VERSION ""

NS_ :

BS_:

BU_: Airbag Allrad EPS Teves_MK60_ESP LWS LWR Teves_MK70_MABS Waehlhebel EPB TRW_ESP ACC_Radar AFS Magne_Ride RKA_Plus Selespeed Waehlhebel_Sele PDC_PLA Lenkhilfe_APA VAQ Daempfer Hybrid_BMS Hybrid_PWR Hybrid_DQ200 EKlimakomp SWA HCA ACC_Lidar Lenkhilfe_ZF_3G FLA AG6 DQ Hybrid_MSG Diesel Otto Gateway_PQ35_A Gateway_PQ46_A Vector_XXX Fzg_CAN

BO_ 1164 mHandschalter_1: 8 Diesel
 SG_ HS1_res_24 : 24|8@1+ (1,0) [0|255] ""  Gateway_PQ46_A,Gateway_PQ35_A,ACC_Lidar,ACC_Radar
 SG_ HS1_Checksumme : 0|8@1+ (1,0) [0|255] ""  Gateway_PQ46_A,Gateway_PQ35_A,ACC_Radar,ACC_Lidar
 SG_ HS1_res_32 : 32|8@1+ (1,0) [0|255] ""  Gateway_PQ46_A,Gateway_PQ35_A,ACC_Lidar,ACC_Radar
 SG_ HS1_res_48 : 48|5@1+ (1,0) [0|31] ""  Gateway_PQ46_A,Gateway_PQ35_A,ACC_Lidar,ACC_Radar
 SG_ HS1_res_19 : 19|1@1+ (1,0) [0|1] ""  Gateway_PQ46_A,Gateway_PQ35_A,ACC_Lidar,ACC_Radar
 SG_ HS1_res_60 : 60|4@1+ (1,0) [0|15] ""  Gateway_PQ46_A,Gateway_PQ35_A,ACC_Lidar,ACC_Radar
 SG_ HS1_res_40 : 40|8@1+ (1,0) [0|255] ""  Gateway_PQ46_A,Gateway_PQ35_A,ACC_Lidar,ACC_Radar
 SG_ HS1_Zaehler : 8|4@1+ (1,0) [0|15] ""  Gateway_PQ46_A,Gateway_PQ35_A,ACC_Radar,ACC_Lidar
 SG_ HS1_res_56 : 56|4@1+ (1,0) [0|15] ""  Gateway_PQ46_A,Gateway_PQ35_A,ACC_Lidar,ACC_Radar
 SG_ HS1_Gang : 16|3@1+ (1,0) [0|7] ""  ACC_Radar,Gateway_PQ46_A,Gateway_PQ35_A,ACC_Lidar
 SG_ HS1_res_12 : 12|1@1+ (1,0) [0|1] ""  Gateway_PQ46_A,Gateway_PQ35_A,ACC_Lidar,ACC_Radar
 SG_ HS1_Drehz_Grenze : 13|3@1+ (1,0) [0|7] ""  ACC_Radar,Gateway_PQ46_A,Gateway_PQ35_A,ACC_Lidar
 SG_ HS1_res_20 : 20|2@1+ (1,0) [0|3] ""  Gateway_PQ46_A,Gateway_PQ35_A,ACC_Lidar,ACC_Radar
 SG_ HS1_res_22 : 22|1@1+ (1,0) [0|1] ""  Gateway_PQ46_A,Gateway_PQ35_A,ACC_Lidar,ACC_Radar
 SG_ HS1_res_23 : 23|1@1+ (1,0) [0|1] ""  Gateway_PQ46_A,Gateway_PQ35_A,ACC_Lidar,ACC_Radar
 SG_ HS1_res_53 : 53|1@1+ (1,0) [0|1] "" Vector__XXX
 SG_ HS1_res_54 : 54|2@1+ (1,0) [0|3] "" Vector__XXX

BO_ 1423 mMotor_12: 8 Diesel
 SG_ M12_Reserve1 : 0|8@1+ (1,0) [0|255] ""  Gateway_PQ46_A,Gateway_PQ35_A
 SG_ M12_Reserve2 : 8|4@1+ (1,0) [0|15] ""  Gateway_PQ46_A,Gateway_PQ35_A
 SG_ M12_SCR_Anz_Motorstarts : 12|4@1+ (1,0) [0|15] ""  Gateway_PQ35_A,Gateway_PQ46_A
 SG_ M12_SCR_Reichweite : 16|15@1+ (1,0) [0|32766] "km"  Gateway_PQ35_A,Gateway_PQ46_A
 SG_ M12_SCR_Warnstufe_1 : 32|1@1+ (1,0) [0|1] ""  Gateway_PQ35_A,Gateway_PQ46_A
 SG_ M12_SCR_Warnstufe_2 : 33|1@1+ (1,0) [0|1] ""  Gateway_PQ35_A,Gateway_PQ46_A
 SG_ M12_Luftfilter_Lampe : 39|1@1+ (1,0) [0|1] ""  Gateway_PQ46_A,Gateway_PQ35_A
 SG_ M12_res_31 : 31|1@1+ (1,0) [0|1] ""  Gateway_PQ46_A,Gateway_PQ35_A
 SG_ M12_Akustik : 37|2@1+ (1,0) [0|3] ""  Gateway_PQ35_A,Gateway_PQ46_A
 SG_ M12_res_40 : 40|1@1+ (1,0) [0|1] ""  Gateway_PQ46_A,Gateway_PQ35_A
 SG_ M12_SCR_Systemfehler : 41|1@1+ (1,0) [0|1] ""  Gateway_PQ35_A,Gateway_PQ46_A
 SG_ M12_SCR_Text : 34|3@1+ (1,0) [0|7] ""  Gateway_PQ35_A,Gateway_PQ46_A
 SG_ M12_SCR_Inducement : 42|2@1+ (1,0) [0|3] ""  Gateway_PQ35_A,Gateway_PQ46_A
 SG_ M12_res_44 : 44|1@1+ (1,0) [0|1] ""  Gateway_PQ46_A,Gateway_PQ35_A
 SG_ M12_res_45 : 45|1@1+ (1,0) [0|1] ""  Gateway_PQ46_A,Gateway_PQ35_A
 SG_ M12_res_46 : 46|1@1+ (1,0) [0|1] ""  Gateway_PQ46_A,Gateway_PQ35_A
 SG_ M12_res_47 : 47|1@1+ (1,0) [0|1] ""  Gateway_PQ46_A,Gateway_PQ35_A
 SG_ M12_res_48 : 48|1@1+ (1,0) [0|1] ""  Gateway_PQ46_A,Gateway_PQ35_A
 SG_ M12_res_49 : 49|1@1+ (1,0) [0|1] ""  Gateway_PQ46_A,Gateway_PQ35_A
 SG_ M12_res_50 : 50|1@1+ (1,0) [0|1] ""  Gateway_PQ46_A,Gateway_PQ35_A
 SG_ M12_res_51 : 51|1@1+ (1,0) [0|1] ""  Gateway_PQ46_A,Gateway_PQ35_A
 SG_ M12_res_52 : 52|1@1+ (1,0) [0|1] ""  Gateway_PQ46_A,Gateway_PQ35_A
 SG_ M12_res_53 : 53|1@1+ (1,0) [0|1] ""  Gateway_PQ46_A,Gateway_PQ35_A
 SG_ M12_res_54 : 54|1@1+ (1,0) [0|1] ""  Gateway_PQ46_A,Gateway_PQ35_A
 SG_ M12_res_55 : 55|1@1+ (1,0) [0|1] ""  Gateway_PQ46_A,Gateway_PQ35_A
 SG_ M12_res_56 : 56|1@1+ (1,0) [0|1] ""  Gateway_PQ46_A,Gateway_PQ35_A
 SG_ M12_res_57 : 57|1@1+ (1,0) [0|1] ""  Gateway_PQ46_A,Gateway_PQ35_A
 SG_ M12_res_58 : 58|1@1+ (1,0) [0|1] ""  Gateway_PQ46_A,Gateway_PQ35_A
 SG_ M12_res_59 : 59|1@1+ (1,0) [0|1] ""  Gateway_PQ46_A,Gateway_PQ35_A
 SG_ M12_res_60 : 60|1@1+ (1,0) [0|1] ""  Gateway_PQ46_A,Gateway_PQ35_A
 SG_ M12_res_61 : 61|1@1+ (1,0) [0|1] ""  Gateway_PQ46_A,Gateway_PQ35_A
 SG_ M12_res_62 : 62|1@1+ (1,0) [0|1] ""  Gateway_PQ46_A,Gateway_PQ35_A
 SG_ M12_res_63 : 63|1@1+ (1,0) [0|1] ""  Gateway_PQ46_A,Gateway_PQ35_A

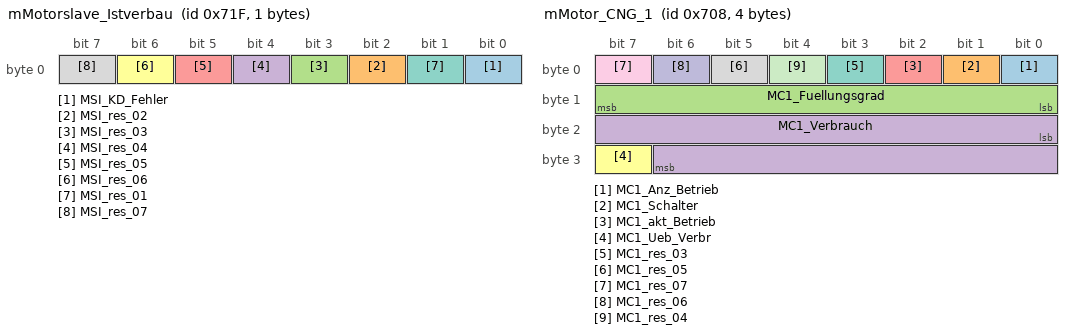
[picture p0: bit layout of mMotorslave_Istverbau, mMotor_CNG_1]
BO_ 1823 mMotorslave_Istverbau: 1 Otto
 SG_ MSI_KD_Fehler : 0|1@1+ (1,0) [0|1] ""  Gateway_PQ35_A
 SG_ MSI_res_02 : 2|1@1+ (1,0) [0|1] "" Vector__XXX
 SG_ MSI_res_03 : 3|1@1+ (1,0) [0|1] "" Vector__XXX
 SG_ MSI_res_04 : 4|1@1+ (1,0) [0|1] "" Vector__XXX
 SG_ MSI_res_05 : 5|1@1+ (1,0) [0|1] "" Vector__XXX
 SG_ MSI_res_06 : 6|1@1+ (1,0) [0|1] "" Vector__XXX
 SG_ MSI_res_01 : 1|1@1+ (1,0) [0|1] "" Vector__XXX
 SG_ MSI_res_07 : 7|1@1+ (1,0) [0|1] "" Vector__XXX

BO_ 1800 mMotor_CNG_1: 4 Otto
 SG_ MC1_Anz_Betrieb : 0|1@1+ (1,0) [0|1] ""  Gateway_PQ35_A,Gateway_PQ46_A
 SG_ MC1_Schalter : 1|1@1+ (1,0) [0|1] ""  Gateway_PQ35_A,Gateway_PQ46_A
 SG_ MC1_Fuellungsgrad : 8|8@1+ (0.4,0) [0|101.6] "%"  Gateway_PQ35_A,Gateway_PQ46_A
 SG_ MC1_Verbrauch : 16|15@1+ (1,0) [0|32767] "mg"  Gateway_PQ35_A,Gateway_PQ46_A
 SG_ MC1_akt_Betrieb : 2|1@1+ (1,0) [0|1] ""  Gateway_PQ35_A,Gateway_PQ46_A
 SG_ MC1_Ueb_Verbr : 31|1@1+ (1,0) [0|1] ""  Gateway_PQ35_A,Gateway_PQ46_A
 SG_ MC1_res_03 : 3|1@1+ (1,0) [0|1] ""  Gateway_PQ46_A,Gateway_PQ35_A
 SG_ MC1_res_05 : 5|1@1+ (1,0) [0|1] ""  Gateway_PQ46_A,Gateway_PQ35_A
 SG_ MC1_res_07 : 7|1@1+ (1,0) [0|1] ""  Gateway_PQ46_A,Gateway_PQ35_A
 SG_ MC1_res_06 : 6|1@1+ (1,0) [0|1] ""  Gateway_PQ46_A,Gateway_PQ35_A
 SG_ MC1_res_04 : 4|1@1+ (1,0) [0|1] ""  Gateway_PQ46_A,Gateway_PQ35_A

BO_ 1888 mTP_Dyn_Getriebe_1: 8 Gateway_PQ35_A
 SG_ TPDyn_Getriebe_1 : 0|64@1+ (1,0) [0|1.8446744074E+019] ""  AG6,DQ,Selespeed,Hybrid_DQ200

BO_ 1897 mTP_Dyn_Airbag_2: 8 Gateway_PQ35_A
 SG_ TPDyn_Airbag_2 : 0|64@1+ (1,0) [0|1.8446744074E+019] ""  Airbag

BO_ 1960 mTP_Dyn_Lenkhilfe_1: 8 Gateway_PQ35_A
 SG_ TPDyn_Lenkhilfe_1 : 0|64@1+ (1,0) [0|1.8446744074E+019] ""  EPS,Lenkhilfe_APA

BO_ 1889 mTP_Dyn_Getriebe_2: 8 Gateway_PQ35_A
 SG_ TPDyn_Getriebe_2 : 0|64@1+ (1,0) [0|1.8446744074E+019] ""  AG6,DQ,Selespeed,Hybrid_DQ200

BO_ 1924 mTP_Dyn_Dyn_LWR_1: 8 Gateway_PQ35_A
 SG_ TPDyn_Dyn_LWR_1 : 0|64@1+ (1,0) [0|1.8446744074E+019] ""  LWR,AFS

BO_ 1925 mTP_Dyn_Dyn_LWR_2: 8 Gateway_PQ35_A
 SG_ TPDyn_Dyn_LWR_2 : 0|64@1+ (1,0) [0|1.8446744074E+019] ""  LWR,AFS

BO_ 1961 mTP_Dyn_Lenkhilfe_2: 8 Gateway_PQ35_A
 SG_ TPDyn_Lenkhilfe_2 : 0|64@1+ (1,0) [0|1.8446744074E+019] ""  EPS,Lenkhilfe_APA

BO_ 1892 mTP_Dyn_Allrad_1: 8 Gateway_PQ35_A
 SG_ TPDyn_Allrad_1 : 0|64@1+ (1,0) [0|1.8446744074E+019] ""  Allrad

BO_ 1937 mTP_Dyn_ABS_2: 8 Gateway_PQ35_A
 SG_ TPDyn_ABS_2 : 0|64@1+ (1,0) [0|1.8446744074E+019] "" Vector__XXX

BO_ 1896 mTP_Dyn_Airbag_1: 8 Gateway_PQ35_A
 SG_ TPDyn_Airbag_1 : 0|64@1+ (1,0) [0|1.8446744074E+019] ""  Airbag

BO_ 1936 mTP_Dyn_ABS_1: 8 Gateway_PQ35_A
 SG_ TPDyn_ABS_1 : 0|64@1+ (1,0) [0|1.8446744074E+019] ""  Teves_MK60_ESP,Teves_MK70_MABS,TRW_ESP

BO_ 800 mKombi_1: 8 Gateway_PQ35_A
 SG_ KO1_Oeldruck : 2|1@1+ (1,0) [0|1] ""  Diesel,Otto
 SG_ KO1_SleepInd : 0|1@1+ (1,0) [0|1] "" Vector__XXX
 SG_ KO1_Sta_Tank : 1|1@1+ (1,0) [0|1] ""  Otto,Hybrid_MSG,Diesel
 SG_ KO1_Kuehlmittel : 4|1@1+ (1,0) [0|1] "" Vector__XXX
 SG_ KO1_Sta_Oeldr : 3|1@1+ (1,0) [0|1] "" Vector__XXX
 SG_ KO1_Warn_Tank : 6|1@1+ (1,0) [0|1] ""  Diesel
 SG_ KO1_La_Ladekon : 10|1@1+ (1,0) [0|1] "" Vector__XXX
 SG_ KO1_Vorgluehen : 7|1@1+ (1,0) [0|1] ""  Diesel
 SG_ KO1_Wakeup_Komfort : 5|1@1+ (1,0) [0|1] "" Vector__XXX
 SG_ KO1_Tankinhalt : 16|7@1+ (1,0) [0|126] "l"  Diesel,Otto,Hybrid_MSG
 SG_ KO1_Zeitluecke : 12|3@1+ (1,0) [0|7] ""  ACC_Radar,ACC_Lidar
 SG_ KO1_Tankstop : 15|1@1+ (1,0) [0|1] "" Vector__XXX
 SG_ KO1_OBD_Tank : 23|1@1+ (1,0) [0|1] ""  Otto,Hybrid_MSG,Diesel
 SG_ KO1_kmh : 25|15@1+ (0.01,0) [0|326] "km/h"  EPS,LWR,PDC_PLA,Lenkhilfe_ZF_3G
 SG_ KO1_Quelle_kmh : 24|1@1+ (1,0) [0|1] ""  Otto
 SG_ KO1_ACC_Inkons : 44|1@1+ (1,0) [0|1] ""  ACC_Radar,ACC_Lidar
 SG_ KO1_Zaehler : 40|4@1+ (1,0) [0|15] ""  ACC_Radar,HCA,ACC_Lidar
 SG_ KO1_kmh_mph : 56|1@1+ (1,0) [0|1] ""  ACC_Radar,ACC_Lidar,Diesel,Otto
 SG_ KO1_ACC_AnzFhl : 45|1@1+ (1,0) [0|1] ""  ACC_Radar,ACC_Lidar
 SG_ KO1_angez_kmh : 46|10@1+ (0.32,0) [0|325.76] "km/h"  DQ,ACC_Radar,RKA_Plus,Hybrid_DQ200,HCA,ACC_Lidar,Diesel,Otto
 SG_ KO1_Bremsinfo : 8|1@1+ (1,0) [0|1] "" Vector__XXX
 SG_ KO1_Stellglieder : 11|1@1+ (1,0) [0|1] ""  Diesel,Airbag,EPS,Lenkhilfe_ZF_3G
 SG_ KO1_ABS_Lampe : 57|1@1+ (1,0) [0|1] "" Vector__XXX
 SG_ KO1_LDW_AnzFeh : 62|1@1+ (1,0) [0|1] ""  HCA
 SG_ KO1_Airbag_Lampe : 60|1@1+ (1,0) [0|1] ""  Airbag
 SG_ KO1_ASRESP_Lampe : 58|1@1+ (1,0) [0|1] "" Vector__XXX
 SG_ KO1_Lenkh_Lampe : 61|1@1+ (1,0) [0|1] ""  EPS,Lenkhilfe_APA,Lenkhilfe_ZF_3G
 SG_ KO1_SILA_gueltig : 63|1@1+ (1,0) [0|1] ""  Airbag,EPS,Lenkhilfe_APA,Lenkhilfe_ZF_3G
 SG_ KO1_Handbremse : 9|1@1+ (1,0) [0|1] ""  DQ,RKA_Plus,Hybrid_DQ200,Selespeed,Allrad,Lenkhilfe_APA,Teves_MK60_ESP,Teves_MK70_MABS,EPS,Lenkhilfe_ZF_3G
 SG_ KO1_Brems_Lampe : 59|1@1+ (1,0) [0|1] "" Vector__XXX

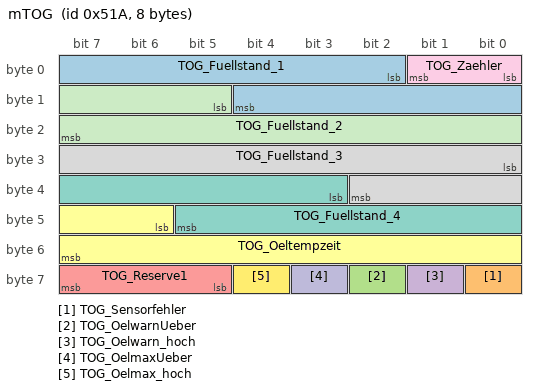
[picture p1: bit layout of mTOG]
BO_ 1306 mTOG: 8 Gateway_PQ35_A
 SG_ TOG_Fuellstand_1 : 2|11@1+ (0.5,100) [101|1123] "ms"  Diesel,Otto,Hybrid_MSG
 SG_ TOG_Sensorfehler : 56|1@1+ (1,0) [0|1] ""  Diesel,Otto,Hybrid_MSG
 SG_ TOG_OelwarnUeber : 58|1@1+ (1,0) [0|1] "" Vector__XXX
 SG_ TOG_Oelwarn_hoch : 57|1@1+ (1,0) [0|1] ""  Diesel,Otto,Hybrid_MSG
 SG_ TOG_Reserve1 : 61|3@1+ (1,0) [0|7] "" Vector__XXX
 SG_ TOG_Oeltempzeit : 46|10@1+ (0.125,0) [0.25|127] "ms"  Diesel,Otto,Hybrid_MSG
 SG_ TOG_Fuellstand_4 : 35|11@1+ (0.5,100) [101|1123] "ms"  Diesel,Otto,Hybrid_MSG
 SG_ TOG_Fuellstand_3 : 24|11@1+ (0.5,100) [101|1123] "ms"  Diesel,Otto,Hybrid_MSG
 SG_ TOG_Zaehler : 0|2@1+ (1,0) [0|3] ""  Diesel,Otto,Hybrid_MSG
 SG_ TOG_OelmaxUeber : 59|1@1+ (1,0) [0|1] "" Vector__XXX
 SG_ TOG_Fuellstand_2 : 13|11@1+ (0.5,100) [101|1123] "ms"  Diesel,Otto,Hybrid_MSG
 SG_ TOG_Oelmax_hoch : 60|1@1+ (1,0) [0|1] "" Vector__XXX

BO_ 1312 mKombi_3: 8 Gateway_PQ35_A
 SG_ KO3_Sprache m0 : 0|8@1+ (1,0) [0|255] ""  TRW_ESP
 SG_ KO3_Mp_Code M : 14|2@1+ (1,0) [0|3] ""  Airbag,Teves_MK60_ESP,Teves_MK70_MABS,TRW_ESP,PDC_PLA,SWA,Allrad
 SG_ KO3_Schluessel : 16|4@1+ (1,0) [0|15] "" Vector__XXX
 SG_ KO3_Standzeit : 24|15@1+ (4,0) [0|131068] "s"  Otto,TRW_ESP,AFS,Magne_Ride,Hybrid_MSG,Diesel,Allrad,Teves_MK60_ESP
 SG_ KO3_Sta_Standz : 39|1@1+ (1,0) [0|1] ""  AFS,Magne_Ride,Diesel,Otto,Teves_MK60_ESP
 SG_ KO3_Kilometer : 40|20@1+ (1,0) [0|1000000] "km"  AG6,EPS,Teves_MK60_ESP,Teves_MK70_MABS,Lenkhilfe_ZF_3G
 SG_ KO3_Um_AFS2 : 20|1@1+ (1,0) [0|1] ""  AFS
 SG_ KO3_Reserve2 : 60|4@1+ (1,0) [0|15] "" Vector__XXX
 SG_ KO3_Land m0 : 8|6@1+ (1,0) [0|63] "" Vector__XXX
 SG_ KO3_Baureihe m1 : 8|3@1+ (1,0) [0|7] ""  Teves_MK60_ESP,Allrad
 SG_ KO3_Radumfang m2 : 0|12@1+ (1,0) [0|4095] ""  Teves_MK60_ESP,Teves_MK70_MABS,TRW_ESP,PDC_PLA,SWA,Allrad
 SG_ KO3_Derivat m1 : 0|4@1+ (1,0) [0|15] ""  Teves_MK60_ESP,Allrad
 SG_ KO3_Generation m1 : 4|4@1+ (1,0) [0|15] ""  Teves_MK60_ESP,Allrad
 SG_ KO3_Marke m1 : 11|3@1+ (1,0) [0|7] ""  Teves_MK60_ESP,Allrad
 SG_ KO3_Verbau_BN m3 : 6|1@1+ (1,0) [0|1] "" Vector__XXX
 SG_ KO3_Verbau_ADR m3 : 5|1@1+ (1,0) [0|1] "" Vector__XXX
 SG_ KO3_Verbau_Air m3 : 4|1@1+ (1,0) [0|1] ""  Airbag
 SG_ KO3_Verbau_DP m3 : 9|1@1+ (1,0) [0|1] "" Vector__XXX
 SG_ KO3_Verbau_Get m3 : 1|1@1+ (1,0) [0|1] "" Vector__XXX
 SG_ KO3_Verbau_Kl m3 : 3|1@1+ (1,0) [0|1] "" Vector__XXX
 SG_ KO3_Verbau_LH m3 : 10|1@1+ (1,0) [0|1] "" Vector__XXX
 SG_ KO3_Verbau_Br m3 : 2|1@1+ (1,0) [0|1] ""  Teves_MK60_ESP
 SG_ KO3_Verbau_Niveau m3 : 11|1@1+ (1,0) [0|1] "" Vector__XXX
 SG_ KO3_Verbau_Mot m3 : 0|1@1+ (1,0) [0|1] "" Vector__XXX
 SG_ KO3_SWA_AnzFeh : 23|1@1+ (1,0) [0|1] ""  SWA
 SG_ KO3_Verbau_LWS m3 : 8|1@1+ (1,0) [0|1] "" Vector__XXX
 SG_ KO3_Um_AutoHold : 22|1@1+ (1,0) [0|1] ""  TRW_ESP
 SG_ KO3_Verbau_Syn m3 : 7|1@1+ (1,0) [0|1] "" Vector__XXX
 SG_ KO3_Um_Tourist : 21|1@1+ (1,0) [0|1] ""  AFS

BO_ 1056 mKombi_2: 8 Gateway_PQ35_A
 SG_ KO2_Sta_Auss_T : 0|1@1+ (1,0) [0|1] ""  Diesel,Otto,Magne_Ride,RKA_Plus,Hybrid_MSG,HCA,Teves_MK60_ESP,Teves_MK70_MABS
 SG_ KO2_Temp_Einheit : 4|1@1+ (1,0) [0|1] "" Vector__XXX
 SG_ KO2_gef_Auss_T : 8|8@1+ (0.5,-50) [-50|77] "°C"  Otto,DQ,TRW_ESP,Magne_Ride,RKA_Plus,PDC_PLA,Hybrid_MSG,Hybrid_DQ200,HCA,Selespeed
 SG_ KO2_Bel_Schalt : 48|7@1+ (1,0) [0|100] "%" Vector__XXX
 SG_ KO2_Oelwarn : 2|1@1+ (1,0) [0|1] "" Vector__XXX
 SG_ KO2_Aussen_T : 16|8@1+ (0.5,-50) [-50|77] "°C"  PDC_PLA,Magne_Ride,Otto,Diesel,Teves_MK60_ESP,Teves_MK70_MABS
 SG_ KO2_Sta_Schalt : 55|1@1+ (1,0) [0|1] "" Vector__XXX
 SG_ KO2_Sta_Displ : 47|1@1+ (1,0) [0|1] ""  Airbag,Magne_Ride,Waehlhebel_Sele,PDC_PLA,Daempfer
 SG_ KO2_Bel_Displ : 40|7@1+ (1,0) [0|100] "%"  Airbag,Magne_Ride,Waehlhebel_Sele,PDC_PLA,Daempfer
 SG_ KO2_Fehlereintr : 7|1@1+ (1,0) [0|1] "" Vector__XXX
 SG_ KO2_Reserve5 : 59|1@1+ (1,0) [0|1] "" Vector__XXX
 SG_ KO2_Wischwasser : 5|1@1+ (1,0) [0|1] "" Vector__XXX
 SG_ KO2_PLA_Displaystatus : 6|1@1+ (1,0) [0|1] ""  PDC_PLA
 SG_ KO2_GRA_High : 3|1@1+ (1,0) [0|1] ""  Diesel,Otto
 SG_ KO2_Kuehlm_T : 32|8@1+ (0.75,-48) [-48|142.5] "°C" Vector__XXX
 SG_ KO2_Verb_TOG : 1|1@1+ (1,0) [0|1] ""  Diesel,Hybrid_MSG,Otto
 SG_ KO2_OelTemp : 24|8@1+ (1,-60) [-60|194] "°C" Vector__XXX
 SG_ KO2_MFA_v_Einheit : 56|1@1+ (1,0) [0|1] ""  Diesel,Otto,Hybrid_MSG
 SG_ KO2_OBD_Nib_Temp : 60|4@1+ (1,0) [0|15] ""  Diesel,Otto,Hybrid_MSG
 SG_ KO2_Passiv_Autolock : 57|1@1+ (1,0) [0|1] "" Vector__XXX
 SG_ KO2_WFS_Schl_Ort : 58|1@1+ (1,0) [0|1] "" Vector__XXX

BO_ 912 mGate_Komf_1: 8 Gateway_PQ35_A
 SG_ GK1_Sta_Licht1 : 2|1@1+ (1,0) [0|1] ""  Teves_MK60_ESP,Teves_MK70_MABS,TRW_ESP,AFS,PDC_PLA,SWA,Lenkhilfe_APA,Diesel,Otto,EPS,Lenkhilfe_ZF_3G,EPB,FLA
 SG_ GK1_Sta_Licht3 : 3|1@1+ (1,0) [0|1] ""  AFS,TRW_ESP
 SG_ GK1_Sta_Anhaen : 1|1@1+ (1,0) [0|1] ""  Teves_MK60_ESP,DQ,TRW_ESP,RKA_Plus,PDC_PLA,Hybrid_DQ200,Diesel,Otto,SWA,HCA
 SG_ GK1_Sta_Tuerkont : 4|1@1+ (1,0) [0|1] ""  Teves_MK60_ESP,Teves_MK70_MABS,EPB,TRW_ESP,Hybrid_MSG,Otto,Diesel
 SG_ GK1_Sta_RDK_Warn : 0|1@1+ (1,0) [0|1] ""  TRW_ESP
 SG_ GK1_SleepAckn : 7|1@1+ (1,0) [0|1] ""  AG6,Diesel,EPS,Otto,Teves_MK60_ESP,LWS,Teves_MK70_MABS,DQ,EPB,TRW_ESP,Waehlhebel_Sele,Lenkhilfe_APA,Hybrid_MSG,Hybrid_DQ200,Selespeed,Lenkhilfe_ZF_3G
 SG_ GK1_Fa_Tuerkont : 16|1@1+ (1,0) [0|1] ""  Teves_MK60_ESP,Teves_MK70_MABS,EPB,TRW_ESP,Hybrid_MSG,Diesel,Otto
 SG_ GK1_BLS_ILM : 32|1@1+ (1,0) [0|1] ""  TRW_ESP
 SG_ GK1_Count_Li_Hi : 24|4@1+ (1,0) [0|15] ""  TRW_ESP
 SG_ GK1_BrLi_links : 29|1@1+ (1,0) [0|1] ""  TRW_ESP
 SG_ GK1_BrLi_rechts : 30|1@1+ (1,0) [0|1] ""  TRW_ESP
 SG_ GK1_KW_Warm : 23|1@1+ (1,0) [0|1] ""  Otto,TRW_ESP,Hybrid_MSG
 SG_ GK1_BrLi_mitte : 31|1@1+ (1,0) [0|1] ""  TRW_ESP
 SG_ GK1_EDC_ILM : 33|1@1+ (1,0) [0|1] ""  TRW_ESP
 SG_ GK1_EDC_AAG : 45|1@1+ (1,0) [0|1] ""  TRW_ESP
 SG_ GK1_Count_Anhaen : 40|4@1+ (1,0) [0|15] ""  TRW_ESP
 SG_ GK1_BLS_AAG : 44|1@1+ (1,0) [0|1] ""  TRW_ESP
 SG_ GK1_LS1_Fernlicht : 37|1@1+ (1,0) [0|1] ""  TRW_ESP,FLA
 SG_ GK1_Rueckfahr : 28|1@1+ (1,0) [0|1] ""  Teves_MK60_ESP,Teves_MK70_MABS,EPB,TRW_ESP,AFS,PDC_PLA,SWA,Otto,Diesel,Lenkhilfe_APA,EPS,Lenkhilfe_ZF_3G,FLA
 SG_ GK1_Anhaenger : 46|1@1+ (1,0) [0|1] ""  Teves_MK60_ESP,DQ,TRW_ESP,RKA_Plus,PDC_PLA,Hybrid_DQ200,Otto,Diesel,SWA,HCA
 SG_ GK1_Abblendlicht : 48|1@1+ (1,0) [0|1] ""  LWR,TRW_ESP,AFS,FLA
 SG_ GK1_BrLi_Anhaen : 47|1@1+ (1,0) [0|1] ""  TRW_ESP
 SG_ GK1_Blinker_re : 35|1@1+ (1,0) [0|1] ""  LWR,TRW_ESP,AFS,PDC_PLA,Diesel,Otto
 SG_ GK1_Blinker_li : 34|1@1+ (1,0) [0|1] ""  LWR,TRW_ESP,AFS,PDC_PLA,Diesel,Otto
 SG_ GK1_Anh_abgesteckt : 60|1@1+ (1,0) [0|1] ""  TRW_ESP
 SG_ GK1_Sta_Li_vorn : 5|1@1+ (1,0) [0|1] ""  AFS,TRW_ESP
 SG_ GK1_Warnblk_Status : 55|1@1+ (1,0) [0|1] ""  TRW_ESP
 SG_ GK1_Fernlicht : 49|1@1+ (1,0) [0|1] ""  LWR,TRW_ESP,AFS,FLA
 SG_ GK1_RueckfahrSch : 17|1@1+ (1,0) [0|1] ""  TRW_ESP
 SG_ GK1_res_06 : 6|1@1+ (1,0) [0|1] ""  TRW_ESP
 SG_ GK1_Abbl_VR_def : 53|1@1+ (1,0) [0|1] ""  TRW_ESP,AFS
 SG_ GK1_Blink_Autob : 54|1@1+ (1,0) [0|1] ""  AFS,TRW_ESP
 SG_ GK1_Wischer_vorn : 50|1@1+ (1,0) [0|1] ""  Diesel,Teves_MK60_ESP,TRW_ESP,AFS,Teves_MK70_MABS,HCA
 SG_ GK1_Abbl_VL_def : 52|1@1+ (1,0) [0|1] ""  TRW_ESP,AFS
 SG_ GK1_Sta_ILM_F_1 : 51|1@1+ (1,0) [0|1] ""  Teves_MK60_ESP,TRW_ESP,AFS,Teves_MK70_MABS,HCA
 SG_ GK1_ELV_verrieg : 18|1@1+ (1,0) [0|1] ""  EPB,TRW_ESP
 SG_ GK1_def_P_verr : 36|1@1+ (1,0) [0|1] ""  AG6,DQ,TRW_ESP,Hybrid_DQ200
 SG_ GK1_Sta_Kessy_2 : 19|1@1+ (1,0) [0|1] ""  TRW_ESP,EPB
 SG_ GK1_SH_Verbau : 21|1@1+ (1,0) [0|1] ""  Otto,TRW_ESP,Hybrid_MSG
 SG_ GK1_Sta_LSM : 39|1@1+ (1,0) [0|1] ""  AG6,TRW_ESP,AFS,PDC_PLA,Diesel,Otto,FLA
 SG_ GK1_Sta_Licht2 : 38|1@1+ (1,0) [0|1] ""  TRW_ESP,AFS
 SG_ GK1_Sta_Stdhzg : 20|1@1+ (1,0) [0|1] ""  Otto,TRW_ESP,Hybrid_MSG
 SG_ GK1_SH_laeuft : 56|1@1+ (1,0) [0|1] ""  TRW_ESP
 SG_ GK1_ParkFrontWi : 22|1@1+ (1,0) [0|1] ""  TRW_ESP
 SG_ GK1_AnhKonLamp : 61|1@1+ (1,0) [0|1] ""  TRW_ESP
 SG_ GK1_SH_Zusatzfkt : 63|1@1+ (1,0) [0|1] ""  TRW_ESP
 SG_ GK1_Nebel_ein : 58|1@1+ (1,0) [0|1] ""  TRW_ESP,AFS,FLA
 SG_ GK1_Bremslicht : 59|1@1+ (1,0) [0|1] ""  TRW_ESP
 SG_ GK1_SH_Vorwaerm : 57|1@1+ (1,0) [0|1] ""  TRW_ESP
 SG_ GK1_res_62 : 62|1@1+ (1,0) [0|1] ""  TRW_ESP
 SG_ GK1_CharismaModus m1 : 8|4@1+ (1,0) [0|3] ""  TRW_ESP,Daempfer,Lenkhilfe_APA,EPS,Otto,Diesel,AG6,DQ,Lenkhilfe_ZF_3G
 SG_ GK1_SamFktNr M : 12|4@1+ (1,0) [0|15] ""  TRW_ESP,Diesel,Daempfer,Lenkhilfe_APA,EPS,Otto,AG6,DQ,Lenkhilfe_ZF_3G

BO_ 1490 mIdent: 8 Gateway_PQ35_A
 SG_ IDT_Mux M : 0|2@1+ (1,0) [0|2] ""  EPS,Teves_MK60_ESP,Teves_MK70_MABS,TRW_ESP,Magne_Ride,Lenkhilfe_APA,Daempfer,LWS,EPB,Lenkhilfe_ZF_3G,Airbag
 SG_ IDT_Geheimnis_2 m0 : 16|8@1+ (1,0) [0|255] ""  TRW_ESP
 SG_ IDT_VIN_1 m0 : 40|8@1+ (1,0) [0|255] ""  Magne_Ride,Daempfer,LWS,TRW_ESP,Airbag
 SG_ IDT_Geheimnis_1 m0 : 8|8@1+ (1,0) [0|255] ""  TRW_ESP
 SG_ IDT_VIN_16 m2 : 48|8@1+ (1,0) [0|255] ""  EPS,Teves_MK60_ESP,Teves_MK70_MABS,TRW_ESP,Magne_Ride,Lenkhilfe_APA,Daempfer,LWS,EPB,Lenkhilfe_ZF_3G,Airbag
 SG_ IDT_Geheimnis_3 m0 : 24|8@1+ (1,0) [0|255] ""  TRW_ESP
 SG_ IDT_VIN_14 m2 : 32|8@1+ (1,0) [0|255] ""  EPS,Teves_MK60_ESP,Teves_MK70_MABS,TRW_ESP,Magne_Ride,Lenkhilfe_APA,Daempfer,LWS,EPB,Lenkhilfe_ZF_3G,Airbag
 SG_ IDT_VIN_15 m2 : 40|8@1+ (1,0) [0|255] ""  EPS,Teves_MK60_ESP,Teves_MK70_MABS,TRW_ESP,Magne_Ride,Lenkhilfe_APA,Daempfer,LWS,EPB,Lenkhilfe_ZF_3G,Airbag
 SG_ IDT_Geheimnis_4 m0 : 32|8@1+ (1,0) [0|255] ""  TRW_ESP
 SG_ IDT_VIN_13 m2 : 24|8@1+ (1,0) [0|255] ""  Magne_Ride,Daempfer,LWS,TRW_ESP,EPB,Airbag,Teves_MK60_ESP
 SG_ IDT_VIN_10 m1 : 56|8@1+ (1,0) [0|255] ""  Magne_Ride,Daempfer,LWS,TRW_ESP,Airbag
 SG_ IDT_VIN_11 m2 : 8|8@1+ (1,0) [0|255] ""  Magne_Ride,Daempfer,LWS,TRW_ESP,Airbag
 SG_ IDT_VIN_4 m1 : 8|8@1+ (1,0) [0|255] ""  Magne_Ride,Daempfer,LWS,TRW_ESP,Airbag
 SG_ IDT_VIN_2 m0 : 48|8@1+ (1,0) [0|255] ""  Magne_Ride,Daempfer,LWS,TRW_ESP,Airbag
 SG_ IDT_VIN_12 m2 : 16|8@1+ (1,0) [0|255] ""  Magne_Ride,Daempfer,LWS,TRW_ESP,Airbag
 SG_ IDT_VIN_6 m1 : 24|8@1+ (1,0) [0|255] ""  Magne_Ride,Daempfer,LWS,TRW_ESP,Airbag
 SG_ IDT_VIN_3 m0 : 56|8@1+ (1,0) [0|255] ""  Magne_Ride,Daempfer,LWS,TRW_ESP,Airbag
 SG_ IDT_VIN_17 m2 : 56|8@1+ (1,0) [0|255] ""  EPS,Teves_MK60_ESP,Teves_MK70_MABS,TRW_ESP,Magne_Ride,Lenkhilfe_APA,Daempfer,LWS,EPB,Lenkhilfe_ZF_3G,Airbag
 SG_ IDT_VIN_7 m1 : 32|8@1+ (1,0) [0|255] ""  Teves_MK60_ESP,Magne_Ride,Daempfer,LWS,TRW_ESP,EPB,Airbag
 SG_ IDT_VIN_9 m1 : 48|8@1+ (1,0) [0|255] ""  Magne_Ride,Daempfer,LWS,TRW_ESP,Airbag
 SG_ IDT_VIN_5 m1 : 16|8@1+ (1,0) [0|255] ""  Magne_Ride,Daempfer,LWS,TRW_ESP,Airbag
 SG_ IDT_VIN_8 m1 : 40|8@1+ (1,0) [0|255] ""  Teves_MK60_ESP,Magne_Ride,Daempfer,LWS,TRW_ESP,EPB,Airbag
 SG_ IDT_res2 : 2|1@1+ (1,0) [0|1] ""  TRW_ESP
 SG_ IDT_res3 : 3|1@1+ (1,0) [0|1] ""  TRW_ESP
 SG_ IDT_res7 : 7|1@1+ (1,0) [0|1] ""  TRW_ESP
 SG_ IDT_res5 : 5|1@1+ (1,0) [0|1] ""  TRW_ESP
 SG_ IDT_res6 : 6|1@1+ (1,0) [0|1] ""  TRW_ESP
 SG_ IDT_res4 : 4|1@1+ (1,0) [0|1] ""  TRW_ESP

BO_ 906 mGRA_Neu: 4 Gateway_PQ35_A
 SG_ GRA_Checksum : 0|8@1+ (1,0) [0|255] ""  Diesel,Otto,ACC_Radar,Hybrid_MSG,ACC_Lidar
 SG_ GRA_Kodierinfo : 15|1@1+ (1,0) [0|1] ""  Diesel,ACC_Radar,ACC_Lidar
 SG_ GRA_Hauptschalt : 8|1@1+ (1,0) [0|1] ""  Diesel,Otto,ACC_Radar,Hybrid_MSG,ACC_Lidar
 SG_ GRA_Neu_Zaehler : 20|4@1+ (1,0) [0|15] ""  Diesel,Otto,ACC_Radar,Hybrid_MSG,ACC_Lidar
 SG_ GRA_Sender : 18|2@1+ (1,0) [0|3] ""  Diesel,Otto,ACC_Radar,Hybrid_MSG,ACC_Lidar
 SG_ GRA_Sta_Limiter : 28|1@1+ (1,0) [0|1] "" Vector__XXX
 SG_ GRA_Sportschalter : 30|1@1+ (1,0) [0|1] "" Vector__XXX
 SG_ GRA_Abbrechen : 9|1@1+ (1,0) [0|1] ""  Diesel,Otto,ACC_Radar,Hybrid_MSG,ACC_Lidar
 SG_ GRA_Down_kurz : 10|1@1+ (1,0) [0|1] ""  Diesel,Otto,ACC_Radar,Hybrid_MSG,ACC_Lidar
 SG_ GRA_Fehler_Tip : 31|1@1+ (1,0) [0|1] ""  AG6
 SG_ GRA_Up_kurz : 11|1@1+ (1,0) [0|1] ""  Diesel,Otto,ACC_Radar,Hybrid_MSG,ACC_Lidar
 SG_ GRA_Up_lang : 13|1@1+ (1,0) [0|1] ""  Diesel,Otto,ACC_Radar,Hybrid_MSG,ACC_Lidar
 SG_ GRA_Down_lang : 12|1@1+ (1,0) [0|1] ""  Diesel,Otto,ACC_Radar,Hybrid_MSG,ACC_Lidar
 SG_ GRA_Neu_Setzen : 16|1@1+ (1,0) [0|1] ""  Diesel,Otto,DQ,ACC_Radar,Hybrid_MSG,Hybrid_DQ200,ACC_Lidar
 SG_ GRA_Tip_Down : 24|1@1+ (1,0) [0|1] ""  AG6,DQ,Hybrid_DQ200,Selespeed
 SG_ GRA_Recall : 17|1@1+ (1,0) [0|1] ""  Diesel,Otto,DQ,ACC_Radar,Hybrid_MSG,Hybrid_DQ200,ACC_Lidar
 SG_ GRA_Tip_Up : 25|1@1+ (1,0) [0|1] ""  AG6,DQ,Hybrid_DQ200,Selespeed
 SG_ GRA_Zeitluecke : 26|2@1+ (1,0) [0|3] ""  ACC_Radar,ACC_Lidar
 SG_ GRA_Typ_Hauptschalt : 29|1@1+ (1,0) [0|1] ""  Diesel,Otto,ACC_Radar,Hybrid_MSG,ACC_Lidar
 SG_ GRA_Fehler_Bed : 14|1@1+ (1,0) [0|1] ""  Diesel,ACC_Radar,Hybrid_MSG,Otto,ACC_Lidar

BO_TX_BU_ 1164 : Otto,Diesel;
BO_TX_BU_ 1888 : Gateway_PQ46_A,Gateway_PQ35_A;
BO_TX_BU_ 1897 : Gateway_PQ46_A,Gateway_PQ35_A;
BO_TX_BU_ 1960 : Gateway_PQ46_A,Gateway_PQ35_A;
BO_TX_BU_ 1889 : Gateway_PQ46_A,Gateway_PQ35_A;
BO_TX_BU_ 1924 : Gateway_PQ46_A,Gateway_PQ35_A;
BO_TX_BU_ 1925 : Gateway_PQ46_A,Gateway_PQ35_A;
BO_TX_BU_ 1961 : Gateway_PQ46_A,Gateway_PQ35_A;
BO_TX_BU_ 1892 : Gateway_PQ46_A,Gateway_PQ35_A;
BO_TX_BU_ 1937 : Gateway_PQ46_A,Gateway_PQ35_A;
BO_TX_BU_ 1896 : Gateway_PQ46_A,Gateway_PQ35_A;
BO_TX_BU_ 1936 : Gateway_PQ46_A,Gateway_PQ35_A;
BO_TX_BU_ 800 : Gateway_PQ46_A,Gateway_PQ35_A;
BO_TX_BU_ 1306 : Gateway_PQ46_A,Gateway_PQ35_A;
BO_TX_BU_ 1312 : Gateway_PQ46_A,Gateway_PQ35_A;
BO_TX_BU_ 1056 : Gateway_PQ46_A,Gateway_PQ35_A;
BO_TX_BU_ 912 : Gateway_PQ46_A,Gateway_PQ35_A;
BO_TX_BU_ 1490 : Gateway_PQ46_A,Gateway_PQ35_A;
BO_TX_BU_ 906 : Gateway_PQ46_A,Gateway_PQ35_A;
CM_ SG_ 1164 HS1_res_24 " 
 ";
CM_ SG_ 1164 HS1_Checksumme " 
Prüfsumme, Definition im CAN Lastenheft";
CM_ SG_ 1164 HS1_res_32 " 
 ";
CM_ SG_ 1164 HS1_res_48 " 
 ";
CM_ SG_ 1164 HS1_res_19 " 
Reserviert für Kupplungsschalter";
CM_ SG_ 1164 HS1_res_60 " 
Reserviert für Sollgang (für Hochschaltanzeige im Kombi)";
CM_ SG_ 1164 HS1_res_40 " 
 ";
CM_ SG_ 1164 HS1_Zaehler " 
Freilaufender Botschaftszähler gem. CAN Lastenheft";
CM_ SG_ 1164 HS1_res_56 " 
Reserviert für Istgang (für Hochschaltanzeige im Kombi)";
CM_ SG_ 1164 HS1_Gang "Ganginformation
Erkennung der Ganginformation im ACC für die ACC-Funktion in Kombination mit Handschaltgetrieben";
CM_ SG_ 1164 HS1_res_12 " 
 ";
CM_ SG_ 1164 HS1_Drehz_Grenze "ACC Motordrehzahlgrenze
Erkennung der Motordrehzahlgrenzen im ACC für die ACC-Funktion in Kombination mit Handschaltgetrieben für die Schaltaufforderung beim Erreichen der Komfortgrenzen bzw. die ACC-Abschaltung beim Erreichen der Abschaltgrenzen";
CM_ SG_ 1164 HS1_res_20 " 
 ";
CM_ SG_ 1164 HS1_res_22 " 
Reserviert für Pfeil-Anzeige Kombi";
CM_ SG_ 1164 HS1_res_23 " 
Reserviert für Pfeil-Anzeige Kombi";
CM_ SG_ 1164 HS1_res_53 " 
Reserviert für Senderkennung";
CM_ SG_ 1164 HS1_res_54 " 
 ";
CM_ SG_ 1423 M12_Reserve1 " 
 ";
CM_ SG_ 1423 M12_Reserve2 " 
 ";
CM_ SG_ 1423 M12_SCR_Anz_Motorstarts "SCR_Anz_Motorstarts
Anzahl noch möglicher Motorstarts, wenn Reichweite = 0 ist0..13 = Anzeige x mögliche Restarts14 = Eingeschränkte Fahrfunktion (z. Zt. Audi)15 = keine Einschränkung (Anzeige Reichweite)";
CM_ SG_ 1423 M12_SCR_Reichweite "SCR_Reichweite
Gesamtreichweite in km der aktuellen SCR-Tankfüllung";
CM_ SG_ 1423 M12_SCR_Warnstufe_1 "SCR_Warnstufe_1 (Prio 2)
Ansteuerung der SCR Füllstandswarnlampe (Stufe 1) (gelbe Lampe)";
CM_ SG_ 1423 M12_SCR_Warnstufe_2 "SCR_Warnstufe_2 (Prio 1)
Ansteuerung der SCR Füllstandswarnlampe (Stufe 2) (Blinkbit für gelbe Lampe oder rote Lampe)";
CM_ SG_ 1423 M12_Luftfilter_Lampe "Lampe Luftfilter verschmutzt
 ";
CM_ SG_ 1423 M12_res_31 " 
 ";
CM_ SG_ 1423 M12_Akustik "Akustik
0 = keine Akustik1 = Akustik 1 (1xSummer 2000 bei VW)2 = Akustik 2 (3xSummer2000 bei VW)3 = Akustik bei Hinweis (Gong 1000 bei VW)";
CM_ SG_ 1423 M12_res_40 " 
 ";
CM_ SG_ 1423 M12_SCR_Systemfehler "SCR_Systemfehler
Ansteuerung Anzeige für SCR-Systemfehler";
CM_ SG_ 1423 M12_SCR_Text "SCR_Text
Warntext (z. B. in Kombination mit SCR Warnstufe und SCR-Systemfehler)0 =  kein Text1 =  Warntext 1 (Prio 2)2 = Warntext 2 (Prio 1)3 = Hinweistext bzgl. Füllstand4 = reserviert5 = Warntext SCR-Systemfehler Stufe 16 = Warntext SCR-Systemfehler Stufe 27 = Hinweistext SCR-Systemfehler";
CM_ SG_ 1423 M12_SCR_Inducement "SCR_Inducement_Strategie
Reserviert für Information an das Kombi, welches Anzeigekonzept das Kombiinstrument passend zur Auslegung des Motor-Inducement-Konzeptes bedienen soll.";
CM_ SG_ 1423 M12_res_44 " 
 ";
CM_ SG_ 1423 M12_res_45 " 
 ";
CM_ SG_ 1423 M12_res_46 " 
 ";
CM_ SG_ 1423 M12_res_47 " 
 ";
CM_ SG_ 1423 M12_res_48 " 
 ";
CM_ SG_ 1423 M12_res_49 " 
 ";
CM_ SG_ 1423 M12_res_50 " 
 ";
CM_ SG_ 1423 M12_res_51 " 
 ";
CM_ SG_ 1423 M12_res_52 " 
 ";
CM_ SG_ 1423 M12_res_53 " 
 ";
CM_ SG_ 1423 M12_res_54 " 
 ";
CM_ SG_ 1423 M12_res_55 " 
 ";
CM_ SG_ 1423 M12_res_56 " 
 ";
CM_ SG_ 1423 M12_res_57 " 
 ";
CM_ SG_ 1423 M12_res_58 " 
 ";
CM_ SG_ 1423 M12_res_59 " 
 ";
CM_ SG_ 1423 M12_res_60 " 
 ";
CM_ SG_ 1423 M12_res_61 " 
 ";
CM_ SG_ 1423 M12_res_62 " 
 ";
CM_ SG_ 1423 M12_res_63 " 
 ";
CM_ SG_ 1823 MSI_KD_Fehler "Kundendienstfehler
Info für Diagnose; bei gesetztem Bit befindet sich mindestens ein Kundendienstfehler im Fehlerspeicher des Motorslave";
CM_ SG_ 1823 MSI_res_02 " 
 ";
CM_ SG_ 1823 MSI_res_03 " 
 ";
CM_ SG_ 1823 MSI_res_04 " 
 ";
CM_ SG_ 1823 MSI_res_05 " 
 ";
CM_ SG_ 1823 MSI_res_06 " 
 ";
CM_ SG_ 1823 MSI_res_01 " 
 ";
CM_ SG_ 1823 MSI_res_07 " 
 ";
CM_ SG_ 1800 MC1_Anz_Betrieb "Betriebsart für Anzeige
Kombiinstrument zeigt die Gasbetriebsart an; Motor steuert die Anzeige mit diesem Bit;Blinken der Anzeige wird durch Setzen und Löschen des Bits nachgebildet (z.B. wenn der Fahrer auf leeren Gastank schalten will)";
CM_ SG_ 1800 MC1_Schalter "Betriebsart Schalterstellung
In diesem Bit wird die Schalterstellung ausgegeben (nicht für die Anzeige im Kombi !); Anmerkung: die aktuelle Betriebsart kann von der eingestellten abweichen";
CM_ SG_ 1800 MC1_Fuellungsgrad "Füllungsgrad Erdgas
Gefilterter temperaturkompensierter Gasdruckwert als Prozentwert vom Maximalwert wird im Kombi als Zeiger dargestellt";
CM_ SG_ 1800 MC1_Verbrauch "Erdgas-Verbrauchssignal
Low Byte 3; High Byte 4;Motor-Steuergerät interner Verbrauchszähler, der vom Kombi zyklisch ausgelesen wird, um die Gasmenge zur Verbrauchsberechnung aufzusummieren; aus diesem Zählerstand werden Momentan- und Durchschnitts-verbrauch berechnet; das Überlauf-Bit (Byte 4, Bit 7) ist zu berücksichtigen";
CM_ SG_ 1800 MC1_akt_Betrieb "Aktuelle Betriebsart
Motor fährt mit Benzin oder Gas(z.Zt. nicht für die Anzeige im Kombi !)";
CM_ SG_ 1800 MC1_Ueb_Verbr "Erdgasverbrauch-Überlauf
Der Motor-Steuergerät interne Verbrauchszähler ist mindestens einmal übergelaufen. Dieses Bit wird genutzt, um erkennen zu können, das das Motorsteuergerät aus dem Reset-Zustand hochläuft";
CM_ SG_ 1800 MC1_res_03 " 
 ";
CM_ SG_ 1800 MC1_res_05 " 
 ";
CM_ SG_ 1800 MC1_res_07 " 
 ";
CM_ SG_ 1800 MC1_res_06 " 
 ";
CM_ SG_ 1800 MC1_res_04 " 
 ";
CM_ SG_ 1888 TPDyn_Getriebe_1 "TP 2.0 Empfangskanal 1 fuer Getriebe_SG
Getriebe";
CM_ SG_ 1897 TPDyn_Airbag_2 "TP 2.0 Empfangskanal 2 fuer Airbag_SG
Airbag";
CM_ SG_ 1960 TPDyn_Lenkhilfe_1 "TP 2.0 Empfangskanal 1 fuer Lenkhilfe_SG
Lenkhilfe";
CM_ SG_ 1889 TPDyn_Getriebe_2 "TP 2.0 Empfangskanal 2 fuer Getriebe_SG
Getriebe";
CM_ SG_ 1924 TPDyn_Dyn_LWR_1 "TP 2.0 Empfangskanal 1 fuer Dyn_LWR_SG
Dyn_LWR";
CM_ SG_ 1925 TPDyn_Dyn_LWR_2 "TP 2.0 Empfangskanal 2 fuer Dyn_LWR_SG
Dyn_LWR";
CM_ SG_ 1961 TPDyn_Lenkhilfe_2 "TP 2.0 Empfangskanal 2 fuer Lenkhilfe_SG
Lenkhilfe";
CM_ SG_ 1892 TPDyn_Allrad_1 "TP 2.0 Empfangskanal 1 fuer Allrad_SG
Allrad";
CM_ SG_ 1937 TPDyn_ABS_2 "TP 2.0 Empfangskanal 2 fuer ABS_SG
ABS";
CM_ SG_ 1896 TPDyn_Airbag_1 "TP 2.0 Empfangskanal 1 fuer Airbag_SG
Airbag";
CM_ SG_ 1936 TPDyn_ABS_1 "TP 2.0 Empfangskanal 1 fuer ABS_SG
ABS";
CM_ SG_ 800 KO1_Oeldruck "Öldruck
Öldruckschalter";
CM_ SG_ 800 KO1_SleepInd "Sleep-Indication-Bit Kombi-CAN
SIB zwischen Kombi und Gateway (nur auf dem Kombi-CAN, wird aber auch auf A-CAN gespiegelt)(z.Zt. nur Audi D3/C6, Audi AB2 und PQ46): Bit hält im PQ35/46 den CAN-Infotainment wachNMHigh-Teilnehmer der PQ35/46 müssen das Signal nach Kl.-15 aus weiterhin bedienen oder dauerhaft auf 1 = Sleep bereit setzen!";
CM_ SG_ 800 KO1_Sta_Tank "Fehlerstatus Tank
nach 2 Sekunden liegt spätestens die Tankinfo vor";
CM_ SG_ 800 KO1_Kuehlmittel "Kühlmittelmangel
 ";
CM_ SG_ 800 KO1_Sta_Oeldr "Dynamische Öldruckwarnung
Öldruckwarnung könnte auch vom Empfänger des Öldruckschalters generiert werden";
CM_ SG_ 800 KO1_Warn_Tank "Tankwarnlampe
Fahrer wird gewarnt (z. Zt. 7 Liter)";
CM_ SG_ 800 KO1_La_Ladekon "Ladekontroll-Lampe (Kombi 1)
Kombi hat seine Ladekontroll-Lampe eingeschaltet (Empfänger: z.Zt. Batman), nicht PQ35/46, nicht Audi D3/C6";
CM_ SG_ 800 KO1_Vorgluehen "Vorglühlampe (Kombi 1)
Rückmeldeinformation für das Motorsteuergerät";
CM_ SG_ 800 KO1_Wakeup_Komfort "Wakeup CAN-Komfort
Das Audi PQ35-/ VW PQ46-Kombi kann durch Setzen dieses Bits bei aktivem Kombi-CAN den Komfort-CAN aufwecken oder wachhalten";
CM_ SG_ 800 KO1_Tankinhalt "Tankinhalt
Restmenge 2 bzw. 2,5l nicht auflösbar";
CM_ SG_ 800 KO1_Zeitluecke "ACC Zusatzanzeige / Angezeigte Zeitlücke
nur in ADR/ACC-Fahrzeugen:ACC Zusatzanzeige: 0 = aus / ungleich 0 = ein;angezeigte ADR-Zeitlücke wird auf 3 Bits begrenzt";
CM_ SG_ 800 KO1_Tankstop "Tankstop
Kombi hat Tankstop erkannt (Vorsicht: Wartezeit nach Klemme 15 ein berücksichtigen); Flag wird nach 5 Sekunden bei fahrendem Fahrzeug gelöscht";
CM_ SG_ 800 KO1_OBD_Tank "Tankwarnung
OBD-Schwelle (z. Zt. 15 %, applizierbar)";
CM_ SG_ 800 KO1_kmh "Geschwindigkeit (Kombi 1)
Fahrzeuggeschwindigkeit als Rohsignal vom Tachogeber (ab ca. 25 km/h eine Geberradumdrehung, d.h. z.Zt. Mittelwert aus 4 Perioden der wahren Geschwindigkeit) oder vom ABS-Steuergerät (Raddrehzahl x Radumfang); die Auflösung entspricht der ABS-Geschwindigkeit in Bremse 1, (nicht Audi D3/C6) ; bei Geschwindigkeiten > 326 wird FFH ausgegeben";
CM_ SG_ 800 KO1_Quelle_kmh "Signalquelle Geschwindigkeit
Die Fahrzeuggeschwindigkeit wird aus einem Tachogeber (eigener Hallgeber, eigener Reed-Kontakt, Fahrtenschreiber) oder aus der Referenzgeschwindigkeit vom ABS berechnet (nicht Audi D3/C6)";
CM_ SG_ 800 KO1_ACC_Inkons "ACC Botschaft(en) nicht konsistent
Rückmeldung zum ACC-/ADR- System bzgl. CAN- Lastenheft";
CM_ SG_ 800 KO1_Zaehler "Botschaftszähler
Plausibilisierung erfolgt im ACC-/ADR- System: im PQ46 nur bei ACC unterstützt";
CM_ SG_ 800 KO1_kmh_mph "Einheit der angezeigten Geschwindigkeit
Dem Fahrer wird die Geschwindigkeit in km/h oder in Miles/hour angezeigt (über Personalisierung verstellbar) (bei Audi konstanter Wert)";
CM_ SG_ 800 KO1_ACC_AnzFhl "ACC Anzeige Fehler
Bit wird bei einem ACC/ADR relevanten Fehler (Anzeige/Gong) gesetzt.";
CM_ SG_ 800 KO1_angez_kmh "Angezeigte Geschwindigkeit
Am Tacho angezeigte Geschwindigkeit (incl Voreilung)";
CM_ SG_ 800 KO1_Bremsinfo "Bremsflüssigkeitswarnung
 ";
CM_ SG_ 800 KO1_Stellglieder "Kombi im Stellgliedtest
Im Stellgliedtest werden auch Lampen angesteuert (Achtung: Rückmeldebits können gesetzt sein)";
CM_ SG_ 800 KO1_ABS_Lampe "ABS Lampe ein
ABS-Sicherheits-Lampe wurde eingeschaltet";
CM_ SG_ 800 KO1_LDW_AnzFeh "LDW-Anzeigefehler
Kombiinstrument hat Fehler erkannt";
CM_ SG_ 800 KO1_Airbag_Lampe "Airbag Lampe ein
Airbag Sicherheits-Lampe wurde eingeschaltet";
CM_ SG_ 800 KO1_ASRESP_Lampe "ASR/ESP Lampe ein
ASR-/ESP-Sicherheits-Lampe wurde eingeschaltet";
CM_ SG_ 800 KO1_Lenkh_Lampe "Lenkhilfe Lampe ein
Lenkhilfe-Sicherheits-Lampe wurde eingeschaltet";
CM_ SG_ 800 KO1_SILA_gueltig "SILA gültig
Rückmeldeinformation (Bit 1-5) ist gültig";
CM_ SG_ 800 KO1_Handbremse "Handbremse angezogen
Umgesetzt bei VW, Audi B6, B7Nicht bei Audi-Fahrzeugen mit EPB (Audi D3, C6)Sonderfall PQ46: Hardware-Eingang von EPB zur Ansteuerung der BKL-Lampe, auch im Betriebsfall BKL-Blinken!Sonderfall BY61x: Gespiegelt aus EPB-Botschaft CAN-Antrieb.";
CM_ SG_ 800 KO1_Brems_Lampe "Bremskontroll-Lampe ein
Sicherheits-Lampe Bremskontrolle wurde eingeschaltet;Besonderheit (VW PQ35/46): Lampe wird auch zur Handbremskontrolle (Audi: auch von EPB) und Bremsflüssigkeitswarnung (auch bei Audi) verwendet und vom Kombi aufgeprüft";
CM_ SG_ 1306 TOG_Fuellstand_1 "Füllstandszeit 1
Füllstand im ersten Zeitfenster";
CM_ SG_ 1306 TOG_Sensorfehler "Sensorfehler
 ";
CM_ SG_ 1306 TOG_OelwarnUeber "Ölwarnschwelle überschritten
nur für WIV 3.1 im Audi C6";
CM_ SG_ 1306 TOG_Oelwarn_hoch "Ölwarnschwelle plus Offset überschritten
 ";
CM_ SG_ 1306 TOG_Reserve1 " 
 ";
CM_ SG_ 1306 TOG_Oeltempzeit "Öltemperaturzeit
Öltemperaturzeit aus max. 4 Zeitfenstern";
CM_ SG_ 1306 TOG_Fuellstand_4 "Füllstandszeit 4
Füllstand im vierten Zeitfenster";
CM_ SG_ 1306 TOG_Fuellstand_3 "Füllstandszeit 3
Füllstand im dritten Zeitfenster";
CM_ SG_ 1306 TOG_Zaehler "Botschaftszähler
Zähler wird mit jeder Botschaft inkrementiert";
CM_ SG_ 1306 TOG_OelmaxUeber "Maximums-Ölfüllstand überschritten
nur für WIV 3.1 im Audi C6";
CM_ SG_ 1306 TOG_Fuellstand_2 "Füllstandszeit 2
Füllstand im zweiten Zeitfenster";
CM_ SG_ 1306 TOG_Oelmax_hoch "Maximums-Ölfüllstand plus Offset überschritten
nur für WIV 3.1 im Audi C6";
CM_ SG_ 1312 KO3_Sprache "Kombi Multiplex Info (Sprachvariante)
Code 00: Länder- und Sprachvariante werden nur ausgegeben, wenn Sie im Kombi vorliegen (z.B. Highline);";
CM_ SG_ 1312 KO3_Mp_Code "Kombi Multiplex Code
Code 00 Ländervariante, Sprachvariante: Land, Sprache (nur Highline); Code 01 Plattform: Plattforminfo, die im Kombi vorliegt; Code 10 Radumfang: mittlerer Radumfang (aus der K-Zahl gerechnet); Code 11 Verbauliste: Verbauliste nach Kenntnisstand des KombisMuxinhalte zu Code ´01´ und ´11´ werden im Kombi Audi C6 nicht mehr unterstützt!!!";
CM_ SG_ 1312 KO3_Schluessel "Schlüsselinfo
15 Schlüssel-Infos Nur wenn WFS im Kombi implementiert ist! (im Touareg GP, D1GP/BY61x gespiegelt aus Komfort-Botschaft mKessy_2, Byte 1, Bit 0-3)";
CM_ SG_ 1312 KO3_Standzeit "Standzeit
(0...36,4 h)  Low Byte 4, High Byte 5; ; Standzeit in 4 Sekunden Auflösung; mit diesen 15 Bits läßt sich eine Zeit bis 36 Stunden, 24 Minuten und 28 Sekunden darstellen; ; Der Standzeitzähler wird mit Klemme 15 aus gestartet, ; er bleibt 2 Minuten vor einem Überlauf stehen, dieser alte Wert für den es keinen Überlauf geben darf, wird erst mit Motorstart und 2 Sekunden Motorlauf aktualisiert   ; Beispiel für Standzeitzähler:	alter Zählerstand 343H, Klemme 15 3 Minuten aus (45 x 4 Sekunden), ;";
CM_ SG_ 1312 KO3_Sta_Standz "Reset Standzeit
 ";
CM_ SG_ 1312 KO3_Kilometer "Kilometerstand
Low Byte 6, High Byte 7 und in Byte 8 Bit 3..0 (additiv) ; Wertebereich geht bis (220 - 1), Fehler wird ausgegeben, falls Kilometerstand nicht restaurierbar";
CM_ SG_ 1312 KO3_Um_AFS2 "Umschaltung AFS II
Aufforderung an das AFS.Funktion auch während der Fahrt bedienbar.Gedrückter Taster bewirkt Umschaltung im AFS-Steuergerät (siehe mLWR_Zustand, Byte 6, Bit 4,5)";
CM_ SG_ 1312 KO3_Reserve2 " 
Reserviert für Fehlerstatus Tankfüllstandsgeber";
CM_ SG_ 1312 KO3_Land "Kombi Multiplex Info (Ländervariante)
Code 00: Länder- und Sprachvariante werden nur ausgegeben, wenn Sie im Kombi vorliegen (z.B. Highline);";
CM_ SG_ 1312 KO3_Baureihe "Kombi Multiplex Info (Plattform/Baureihe)
Code 01: Plattforminformation entspricht dem Kenntnisstand des Kombis";
CM_ SG_ 1312 KO3_Radumfang "Kombi Multiplex Info (Radumfang)
Code 10: mittlerer Reifenumfang in Millimeter (Byte 2 Bit 5,4 reserviert, Byte 2 Bit 3..0 und Byte 1 Bit 7..0; Wertebereich 0..4096 mm)";
CM_ SG_ 1312 KO3_Derivat "Kombi Multiplex Info (Plattform/Derivat)
Code 01: Plattforminformation entspricht dem Kenntnisstand des Kombis; als Derivat wird 0 (Kurzheck) ausgegeben, wenn es keine Besonderheiten abhängig vom Derivat gibt";
CM_ SG_ 1312 KO3_Generation "Kombi Multiplex Info (Plattform/Generation)
Code 01: Plattforminformation entspricht dem Kenntnisstand des Kombis";
CM_ SG_ 1312 KO3_Marke "Kombi Multiplex Info (Plattform/Marke)
Code 01: Plattforminformation entspricht dem Kenntnisstand des Kombis";
CM_ SG_ 1312 KO3_Verbau_BN "Verbauliste Bordnetz
Code 11: Verbauliste nach Kenntnisstand des Kombis";
CM_ SG_ 1312 KO3_Verbau_ADR "Verbauliste ADR
Code 11: Verbauliste nach Kenntnisstand des Kombis";
CM_ SG_ 1312 KO3_Verbau_Air "Verbauliste Airbag
Code 11: Verbauliste nach Kenntnisstand des Kombis";
CM_ SG_ 1312 KO3_Verbau_DP "Verbauliste Dieselpumpe
Code 11: Verbauliste nach Kenntnisstand des Kombis";
CM_ SG_ 1312 KO3_Verbau_Get "Verbauliste Getriebe
Code 11: Verbauliste nach Kenntnisstand des Kombis";
CM_ SG_ 1312 KO3_Verbau_Kl "Verbauliste Klima
Code 11: Verbauliste nach Kenntnisstand des Kombis";
CM_ SG_ 1312 KO3_Verbau_LH "Verbauliste Lenkhilfe
Code 11: Verbauliste nach Kenntnisstand des Kombis";
CM_ SG_ 1312 KO3_Verbau_Br "Verbauliste Bremse
Code 11: Verbauliste nach Kenntnisstand des Kombis";
CM_ SG_ 1312 KO3_Verbau_Niveau "Verbauliste Niveauregulierung
Code 11: Verbauliste nach Kenntnisstand des Kombis";
CM_ SG_ 1312 KO3_Verbau_Mot "Verbauliste Motor
Code 11: Verbauliste nach Kenntnisstand des Kombis";
CM_ SG_ 1312 KO3_SWA_AnzFeh "SWA Anzeigefehler
Kombiinstrument hat Fehler erkannt";
CM_ SG_ 1312 KO3_Verbau_LWS "Verbauliste Lenkwinkel
Code 11: Verbauliste nach Kenntnisstand des Kombis";
CM_ SG_ 1312 KO3_Um_AutoHold "Auto Hold umschalten
Umstellung der Auto Hold-Funktion im MFA-Display als Rückmeldung für die EPB (PQ46 ab 22/08, VW469)Gedrückter Taster bewirkt Umschaltung im EPB-Steuergerät (siehe mEPB_1, Byte 5, Bit 2,3)";
CM_ SG_ 1312 KO3_Verbau_Syn "Verbauliste Allrad
Code 11: Verbauliste nach Kenntnisstand des Kombis";
CM_ SG_ 1312 KO3_Um_Tourist "Touristenfunktion umschalten
Aufforderung an das AFS.Gedrückter Taster bewirkt Umschaltung im AFS-Steuergerät (siehe mLWR_Zustand, Byte 6, Bit 6,7)";
CM_ SG_ 1056 KO2_Sta_Auss_T "Fehlerstatus Außentemperatur
n.i.O. steht für Fehlerwert, außerhalb des Meßbereichs (ungenau), nicht verbaut oder noch kein aktueller Wert ,  Besonderheit Initwerte Temperaturen (bei VW und Audi ???): ; 0/1*: 	0:   Klemme 30 Reset ; 	1:   Klemme 15 Hochlauf ; 0/alt**	0:   es liegt kein alter Wert vor (Kl.30 reset) ; 	alt: der letzte bei Kl.15 aus abgespeicherte Wert (bei Audi-Kombis wird hier 01H ausgegeben) ; ";
CM_ SG_ 1056 KO2_Temp_Einheit "Temperatureinheit
Außentemperatur Anzeige im Kombi wird in Grad Celsius oder Fahrenheit gemacht";
CM_ SG_ 1056 KO2_gef_Auss_T "Außentemperatur gefiltert
realer Meßbereich z. Zt. ca. -45..58 Grad; 0 für nicht verbaut;im Fehlerfall (FFH) ggf. auf Byte 8, Bit 7..4 achten";
CM_ SG_ 1056 KO2_Bel_Schalt "Klemme 58s (Kombi 2)
Schalter-Beleuchtung (z.Zt. nur Audi) ,Tastverhältnis in Prozent";
CM_ SG_ 1056 KO2_Oelwarn "Ölwarnschwelle plus Offset überschritten
´Ölwarnschwelle plus Offset überschritten (s. TOG1, Byte 8, Bit 1)(wird verwendet, falls bei WIV3.2 der TOG-Sensor nicht direkt am Kombi angeschlossen ist, siehe Byte 1, Bit 1)";
CM_ SG_ 1056 KO2_Aussen_T "Außentemperatur ungefiltert (Kombi 2)
Klima-Steuergerät kann aus dem Rohsignal eigene Plausibilitäten berechnen; 0 für nicht verbaut; im Hochlauf alter abgespeicherter Wert bis neuer vorliegt, Besonderheit Initwerte Temperaturen (bei VW und Audi ???): ; 0/1*: 	0:   Klemme 30 Reset ; 	1:   Klemme 15 Hochlauf ; 0/alt**	0:   es liegt kein alter Wert vor (Kl.30 reset) ; 	alt: der letzte bei Kl.15 aus abgespeicherte Wert (bei Audi-Kombis wird hier 01H ausgegeben) ;im Fehlerfall (FFH) ggf. auf Byte 8, Bit 7..4 ";
CM_ SG_ 1056 KO2_Sta_Schalt "Fehlerstatus Kl. 58 s (Kombi 2)
N.i.O. steht für nicht verfügbar (z. Zt. bei VW) oder Ersatzwert in Bit 6..0 wird vorgegeben";
CM_ SG_ 1056 KO2_Sta_Displ "Fehlerstatus Kl. 58 d (Kombi 2)
N.i.O. steht für nicht verfügbar oder Ersatzwert in Bit 6..0 wird vorgegeben (Standard); VW Highline / Mini-DOT und Audi Kombis geben das mit dem Fototransister bewertete Signal aus";
CM_ SG_ 1056 KO2_Bel_Displ "Klemme 58d (Kombi 2)
Display-Beleuchtung, Tastverhältnis in Prozent";
CM_ SG_ 1056 KO2_Fehlereintr "Fehlerspeichereintrag (Kombi 2)
Bei gesetztem Bit ist mindestens ein Kundendienstfehler eingetragen";
CM_ SG_ 1056 KO2_Reserve5 " 
 ";
CM_ SG_ 1056 KO2_Wischwasser "Wischwasserwarnung
Zusatzinfo zur Scheinwerferreinigungsanlage (z. Zt. nur Audi D3)";
CM_ SG_ 1056 KO2_PLA_Displaystatus "PLA Displaystatus
Das Signal wird als aktive Rückmeldung genutzt, ob die Info des PLA im Kombi angezeigt wird. Wenn nach Anforderung des Displays das Signal zweimal auf 0 ist, wird der Parkvorgang abgebrochen.Ein Kombi, dass PLA Anzeige nicht unterstützt, schickt dauerhaft 0.";
CM_ SG_ 1056 KO2_GRA_High "GRA-High-Anzeige im Display wird unterstützt
Kombi unterstützt die 'GRA High' (Sollgeschwindigkeit wird angezeigt)";
CM_ SG_ 1056 KO2_Kuehlm_T "Kühlmitteltemperatur (Kombi 2)
realer Meßbereich ca. 50..130 Grad, diese Größe wird nur vorrüber-gehend ausgegeben, bis das Motor-Steuergerät einen Temperatur-sensor für den gesamten Temperaturbereich hat; 0 für nicht verbaut ; im Hochlauf alter abgespeicherter Wert bis neuer vorliegt, (nur Porsche Cayenne, BY61x abwärtskompatibel)";
CM_ SG_ 1056 KO2_Verb_TOG "TOG nicht verbaut
´TOG nicht verbaut´: TOG nicht am Kombi angeschlossen; TOG-Botschaft wird nicht vom Kombi gesendet (Bit wird bei Audi nicht unterstützt)";
CM_ SG_ 1056 KO2_OelTemp "Öltemperatur
realer Meßbereich bei A03 Wirbelkammer Diesel ca. 60..150 Grad, sonst -40..150 Grad; 0 für nicht verbaut ; im Hochlauf alter abgespeicherter Wert bis neuer vorliegt, (nur Porsche Cayenne, BV61x abwärtskompatibel)";
CM_ SG_ 1056 KO2_MFA_v_Einheit "MFA v Einheit
Meldung an den Motor, mit welcher Einheit die GRA-Geschwindigkeit dargestellt wird, damit der Motor in der Botschaft Motor_8 die GRA-Wunschgeschwindigkeit anzeigeoptimiert ausgeben kann (Verhinderung von Werten, die keiner Meilengröße entsprechen). (im Audi B7, C6, D3, AU716, TTNF! Audi steuert mit dem Signal Einheit der angezeigten Geschwindigkeit in Kombi_1, Byte 8, Bit 0 Hardwarevarianten des Kombis! Daher die Notwendigkeit dieses Signals MFA v Einheit)";
CM_ SG_ 1056 KO2_OBD_Nib_Temp "Fehler-Nibble Aussentemperatur
Die Motorsteuerung muss bei einem Sensorfehler Fehlerarten unterscheiden können (CARB-Forderung)(PQ35/46 geplant zu KW 22/07, Touareg GP 22/08)0000 = kein Fehler0001 = KS-0010 = KS+0011 = OC0100 = OOR+0101 = OOR-0110 = RC+0111 = RC-1000 = KS+/OC1001 = KS-/OC1010 = KS-/KS+1011 = KS-/KS+/OC1100 = frei1101 = frei1110 = frei1111 = frei";
CM_ SG_ 1056 KO2_Passiv_Autolock "Passiv Autolock
Umschaltanforderung vom Kombi: ´Passiv Autolock / Autounlock´";
CM_ SG_ 1056 KO2_WFS_Schl_Ort "Schluesselerkennung
Schlüsselerkennung via Lesespule oder Keyless";
CM_ SG_ 912 GK1_Sta_Licht1 "Licht 1-Botschaft veraltet
Licht-Botschaft nicht empfangen (100 ms)";
CM_ SG_ 912 GK1_Sta_Licht3 "Licht 3-/ Licht hinten-Botschaft veraltet
'Licht_hinten'-Botschaft nicht empfangen (200 ms nur Audi)'mLicht_3'-Botschaft veraltet (2 s Colorado)reserviert im PQ35/46 (Init 0 im PQ35/46)";
CM_ SG_ 912 GK1_Sta_Anhaen "Anhänger-Botschaft veraltet
Anhänger-Botschaft nicht empfangen (1,6 s/200 ms)";
CM_ SG_ 912 GK1_Sta_Tuerkont "Fahrertürkontakt veraltet
'mBSG_Kombi oder 'mTSG_FT1 -Botschaft nicht empfangen (100 ms) ; 'mBSG_1' nicht empfangen (400 ms); (abhängig von der Quelle des Fahrertürkontaktes)";
CM_ SG_ 912 GK1_Sta_RDK_Warn "Reifendruckwarnung veraltet
RDK-Botschaft nicht empfangen (1,6 s/200 ms)";
CM_ SG_ 912 GK1_SleepAckn "Sleep Acknowledge
Nach Empfang des 'Sleep-Acknowledge (Klemme 15 aus) muß der Sendebetrieb sofort eingestellt werden; die CAN-Schnittstelle (empfangseitig) wird nach der Wartezeit (750 ms) komplett abgeschaltet (nicht Colorado)Touareg GP u. D1GP setzen das Bit nach Kl.15 aus (3-maliges Senden)* BCM PQ25 setzt Bit nach Kl.15 aus dauerhaft, wenn (BR1_Rad_kmh = 0 oder BR1 Timeout).Rücksetzen des Bits erst nach Kl.15 ein";
CM_ SG_ 912 GK1_Fa_Tuerkont "Fahrertürkontakt
1 = Tuer geoeffnet, 0 = Tuer geschlossenInfo wird bei Gateway-Funktionalität z. B. aus 'mBSG_1, Byte 1, Bit 0' (VW A4/B5/PQ24) oder TSG_FT1, Byte 1, Bit 0 entnommen (je nach Quelle des Signals). BCM PQ25 ist Original-Sender.";
CM_ SG_ 912 GK1_BLS_ILM "BLS ILM unplausibel
Bremse 1, Byte 2, Bit 3 widerspricht der Hardware-Leitung vom BLS zum ILM hinten (nur bei Audi): Info wird aus 'Licht hinten entnommen";
CM_ SG_ 912 GK1_Count_Li_Hi "Zähler Bremslicht
Zähler wird vom ILM in der Botschaft 'Licht hinten', Byte 1, Bit 0-3 generiert (nur bei Audi)";
CM_ SG_ 912 GK1_BrLi_links "Bremslicht links defekt
Aktueller Zustand der Bremslichtlampe hinten links aus 'mLicht 2, Byte 3, Bit 2 oder 'Licht 3, Byte 1, Bit 2";
CM_ SG_ 912 GK1_BrLi_rechts "Bremslicht rechts defekt
Aktueller Zustand der Bremslichtlampe hinten rechts aus 'mLicht 2, Byte 4, Bit 2 oder 'Licht 3, Byte 2, Bit 2";
CM_ SG_ 912 GK1_KW_Warm "Kühlwasser warm
Info wird aus mStHeizung_1 entnommen (Bit wurde ab V2.8.9 eingeführt) (Zusatzfunktion der Standheizung)";
CM_ SG_ 912 GK1_BrLi_mitte "Bremslicht mitte defekt
Aktueller Zustand der Bremslichtlampe hinten Mitte aus 'mLicht 2, Byte 3, Bit 5 oder 'Licht 3, Byte 1, Bit 5 oder aus 'Licht hinten, Byte 4, Bit 7 (nur bei Audi)";
CM_ SG_ 912 GK1_EDC_ILM "ECD ILM unplausibel
'Bremse 5, Byte 7, Bit 3 widerspricht der Hardware-Leitung vom ESP zum ILM hinten (nur bei Audi): Info wird aus 'Licht hinten entnommen";
CM_ SG_ 912 GK1_EDC_AAG "ECD AAG unplausibel
'Bremse 5, Byte 7, Bit 3 widerspricht der Hardware-Leitung vom ESP zum Anhänger-SG (nur bei Audi) : Info wird aus 'Anhänger 1 entnommen";
CM_ SG_ 912 GK1_Count_Anhaen "Zähler Anhänger
Zähler wird vom Anhänger-SG generiert (nur bei Audi): Info wird aus 'Anhänger 1 entnommen";
CM_ SG_ 912 GK1_BLS_AAG "BLS AAG unplausibel
Bremse 1, Byte 2, Bit 3 widerspricht der Hardware-Leitung vom BLS zum Anhänger-SG (nur bei Audi) : Info wird aus 'Anhänger 1 entnommen";
CM_ SG_ 912 GK1_LS1_Fernlicht "Fernlicht ein
Fernlichtschalter (Info wird aus 'mLSM_1', Byte 1, Bit 3 entnommen)";
CM_ SG_ 912 GK1_Rueckfahr "Rückfahrlicht (Gateway Komfort 1)
Info wird aus 'mLicht 1, Byte 1, Bit 5-Botschaft oder aus 'Licht hinten (nur bei Audi) entnommen ";
CM_ SG_ 912 GK1_Anhaenger "Anhänger erkannt (Gateway Komfort 1)
Info wird aus der 'mAnhänger_1, Byte 1, Bit 7 (Audi B6, VW) oder aus 'Anhänger 1 (nur Audi) entnommen";
CM_ SG_ 912 GK1_Abblendlicht "Abblendlicht
Aktueller Zustand des Abblendlichts; aus Licht vorne, Byte 1, Bit 1(nur Audi) oder aus 'Licht 1, Byte 1, Bit 1 (VW) entnommen";
CM_ SG_ 912 GK1_BrLi_Anhaen "Bremslicht Anhänger defekt
Aktueller Zustand der Bremslichtlampen; aus 'mAnhänger_1, Byte 1, Bit 0 entnommen";
CM_ SG_ 912 GK1_Blinker_re "Blinker rechts
Meldung für ADR/ACC, Info wird aus 'mLSM1, Byte1, Bit1 entnommen";
CM_ SG_ 912 GK1_Blinker_li "Blinker links
Meldung für ADR/ACC, Info wird aus 'mLSM1, Byte1, Bit0 entnommen";
CM_ SG_ 912 GK1_Anh_abgesteckt "Anhänger abgesteckt
Aktueller Zustand des Anhängers wird aus Anhänger-Botschaft entnommen";
CM_ SG_ 912 GK1_Sta_Li_vorn "Licht vorne-Botschaft veraltet
'Licht_vorne -Botschaft nicht empfangen (2 s, nur Audi)reserviert im PQ35/46 (Init 0 im PQ35/46)";
CM_ SG_ 912 GK1_Warnblk_Status "Warnblink-Status
Aktueller Zustand aus Licht-Botschaft entnommen";
CM_ SG_ 912 GK1_Fernlicht "Fernlicht
Aktueller Zustand des Fernlichts; aus Licht vorne, Byte 1, Bit 2(nur Audi) ) oder aus 'Licht 1, Byte 1, Bit 2 (VW) entnommen";
CM_ SG_ 912 GK1_RueckfahrSch "Rückfahrlichtschalter
Info wird aus 'ILM_Fahrer_1', Byte 2, Bit 1 (nur bei Audi) entnommen";
CM_ SG_ 912 GK1_res_06 " 
reserviert im PQ35/46 (Init 0 im PQ35/46)";
CM_ SG_ 912 GK1_Abbl_VR_def "Abblendlicht_VR_def
Aktueller Zustand aus Licht-Botschaft entnommen";
CM_ SG_ 912 GK1_Blink_Autob "Blinken_Autobahn
Aktueller Zustand aus Blinkmodi-Botschaft entnommen";
CM_ SG_ 912 GK1_Wischer_vorn "Wischer vorne läuft
Aktueller Zustand aus ILM Fahrer oder 'Wischer 1' Botschaft entnommen";
CM_ SG_ 912 GK1_Abbl_VL_def "Abblendlicht_VL_def
Aktueller Zustand aus Licht-Botschaft entnommen";
CM_ SG_ 912 GK1_Sta_ILM_F_1 "ILM_Fahrer_1 veraltet / Wischer 1 veraltet
ILM_Fahrer_1-Botschaft nicht empfangen (2 s); Wischer_1 Botschaft nicht empfangen (400 msec)";
CM_ SG_ 912 GK1_ELV_verrieg "ELV verriegelt
Info wird aus 'mKessy_2' Byte 2, Bit 2 (Col.), 'mELV_Kessy_WFS', Byte 3, Bit 2 (PQ46), 'mELV_1', Byte 2, Bit 0 (PQ35/PQ25) entnommen";
CM_ SG_ 912 GK1_def_P_verr "P-verriegelt defekt
P-verriegelt wurde als defekt erkannt";
CM_ SG_ 912 GK1_Sta_Kessy_2 "Kessy 2 Botschaft veraltet
Kessy 2 (400 msec Col.), mELV_Kessy_WFS (200 msec PQ46), mELV_1 (2000msec PQ35/PQ25) wird nicht empfangen";
CM_ SG_ 912 GK1_SH_Verbau "Standheizung verbaut
Info aus mStheizung_1: Standheizung steht für potentielle Aufheizung des Kühlwassers vor Kl. 15 ein (Zuheizer setzt Bit auf 0)";
CM_ SG_ 912 GK1_Sta_LSM "LSM-Botschaft veraltet
LSM-Botschaft wird nicht empfangen (200 ms)";
CM_ SG_ 912 GK1_Sta_Licht2 "Licht_2-Botschaft veraltet
Licht 2-Botschaft wird nicht empfangen (2 s)";
CM_ SG_ 912 GK1_Sta_Stdhzg "Standheizungs-Botschaft veraltet
mStheizung_1 wird nicht empfangen (400 ms)";
CM_ SG_ 912 GK1_SH_laeuft "Standheizung läuft
Nur im D3 wird diese Info auch aus ´Klima1_D3´ entnommen";
CM_ SG_ 912 GK1_ParkFrontWi "Parklage Frontwischer
Info wird aus 'mWischer_1' entnommen";
CM_ SG_ 912 GK1_AnhKonLamp "Kontrolllampe Anhänger
Akt. Zustand der Anhängerblinklampe (Taktsignal) wird aus BSG-Botschaft entnommen (nur T5)";
CM_ SG_ 912 GK1_SH_Zusatzfkt "Zusatzfunktionen Standheizung
Zusatzfunktionen der Standheizung sind verfügbar, wenn DLC von mStHeizung_1 >=7";
CM_ SG_ 912 GK1_Nebel_ein "Nebellicht ein
Aktueller Zustand des Nebellichts aus Licht-Botschaft entnommen";
CM_ SG_ 912 GK1_Bremslicht "Bremslicht ein
Aktueller Zustand des Bremslichts aus Licht-Botschaft entnommen";
CM_ SG_ 912 GK1_SH_Vorwaerm "Standheizung Motorvorwärmung
Nur im D3 wird diese Info auch aus ´Klima1_D3´ entnommen";
CM_ SG_ 912 GK1_res_62 " 
 ";
CM_ SG_ 912 GK1_CharismaModus "Charisma-Modus
Charisma-ModusNur gültig, wenn Byte 2, Bit 7..4 auf den Wert 1 gesetzt ist";
CM_ SG_ 912 GK1_SamFktNr "Sammelfunktion Nr.
Sammelfunktions-Nr.Die gültigen SF werden mit jeder neuen Botschaft hochgezählt. Bei Änderung wird mit Inhibit 50ms das Hochzählen mit der entsprech. SF-Nr. unterbrochen.";
CM_ SG_ 1490 IDT_Mux "Multiplexer Ident
Schaltet die nächsten 7 Byte um zur Übertragung von Fahrgestellnummer und Fahrzeuggeheimnis.VW756/VW611: Reihenfolge der Inhalte für schnelle Initialisierung anderer Steuergeräte über Ident-Wert 0 folgendermaßen definiert 0, 1, 0, 2, 0, 1, 0, &";
CM_ SG_ 1490 IDT_Geheimnis_2 "Geheimnis 2
Multiplex = 02. Byte Fahrzeuggeheimnis (nicht PQ35/46)";
CM_ SG_ 1490 IDT_VIN_1 "VIN 1
Multiplex = 01. Stelle der FahrgestellnummerWFS nicht angelernt: Ausgabe X (0x58) oder - (0x2D)";
CM_ SG_ 1490 IDT_Geheimnis_1 "Geheimnis 1
Multiplex = 01. Byte Fahrzeuggeheimnis (nicht PQ35/46)";
CM_ SG_ 1490 IDT_VIN_16 "VIN 16
Multiplex = 216. Stelle der FahrgestellnummerWFS nicht angelernt: Ausgabe X (0x58) oder - (0x2D)";
CM_ SG_ 1490 IDT_Geheimnis_3 "Geheimnis 3
Multiplex = 03. Byte Fahrzeuggeheimnis (nicht PQ35/46)";
CM_ SG_ 1490 IDT_VIN_14 "VIN 14
Multiplex = 214. Stelle der FahrgestellnummerWFS nicht angelernt: Ausgabe X (0x58) oder - (0x2D)";
CM_ SG_ 1490 IDT_VIN_15 "VIN 15
Multiplex = 215. Stelle der FahrgestellnummerWFS nicht angelernt: Ausgabe X (0x58) oder - (0x2D)";
CM_ SG_ 1490 IDT_Geheimnis_4 "Geheimnis 4
Multiplex = 04. Byte Fahrzeuggeheimnis (nicht PQ35/46)";
CM_ SG_ 1490 IDT_VIN_13 "VIN 13
Multiplex = 213. Stelle der FahrgestellnummerWFS nicht angelernt: Ausgabe X (0x58) oder - (0x2D)";
CM_ SG_ 1490 IDT_VIN_10 "VIN 10
Multiplex = 110. Stelle der FahrgestellnummerWFS nicht angelernt: Ausgabe X (0x58) oder - (0x2D)";
CM_ SG_ 1490 IDT_VIN_11 "VIN 11
Multiplex = 211. Stelle der FahrgestellnummerWFS nicht angelernt: Ausgabe X (0x58) oder - (0x2D)";
CM_ SG_ 1490 IDT_VIN_4 "VIN 4
Multiplex = 14. Stelle der FahrgestellnummerWFS nicht angelernt: Ausgabe X (0x58) oder - (0x2D)";
CM_ SG_ 1490 IDT_VIN_2 "VIN 2
Multiplex = 02. Stelle der FahrgestellnummerWFS nicht angelernt: Ausgabe X (0x58) oder - (0x2D)";
CM_ SG_ 1490 IDT_VIN_12 "VIN 12
Multiplex = 212. Stelle der FahrgestellnummerWFS nicht angelernt: Ausgabe X (0x58) oder - (0x2D)";
CM_ SG_ 1490 IDT_VIN_6 "VIN 6
Multiplex = 16. Stelle der FahrgestellnummerWFS nicht angelernt: Ausgabe X (0x58) oder - (0x2D)";
CM_ SG_ 1490 IDT_VIN_3 "VIN 3
Multiplex = 03. Stelle der FahrgestellnummerWFS nicht angelernt: Ausgabe X (0x58) oder - (0x2D)";
CM_ SG_ 1490 IDT_VIN_17 "VIN 17
Multiplex = 217. Stelle der FahrgestellnummerWFS nicht angelernt: Ausgabe X (0x58) oder - (0x2D)";
CM_ SG_ 1490 IDT_VIN_7 "VIN 7
Multiplex = 17. Stelle der FahrgestellnummerWFS nicht angelernt: Ausgabe X (0x58) oder - (0x2D)";
CM_ SG_ 1490 IDT_VIN_9 "VIN 9
Multiplex = 19. Stelle der FahrgestellnummerWFS nicht angelernt: Ausgabe X (0x58) oder - (0x2D)";
CM_ SG_ 1490 IDT_VIN_5 "VIN 5
Multiplex = 15. Stelle der FahrgestellnummerWFS nicht angelernt: Ausgabe X (0x58) oder - (0x2D)";
CM_ SG_ 1490 IDT_VIN_8 "VIN 8
Multiplex = 18. Stelle der FahrgestellnummerWFS nicht angelernt: Ausgabe X (0x58) oder - (0x2D)";
CM_ SG_ 1490 IDT_res2 " 
 ";
CM_ SG_ 1490 IDT_res3 " 
 ";
CM_ SG_ 1490 IDT_res7 " 
 ";
CM_ SG_ 1490 IDT_res5 " 
 ";
CM_ SG_ 1490 IDT_res6 " 
 ";
CM_ SG_ 1490 IDT_res4 " 
 ";
CM_ SG_ 906 GRA_Checksum "Checksumme (GRA_Neu)
Prüfsumme, Definition im CAN-Lastenheft";
CM_ SG_ 906 GRA_Kodierinfo "Kodierinfo SMLS
Wird zur Verbaukontrolle verwendet (nicht VW D1/Colorado, aber im Touareg GP) (im PQ24/T5 immer 0=GRA)";
CM_ SG_ 906 GRA_Hauptschalt "GRA/ ADR-Hauptschalter (GRA_Neu)
GRA Gerastetes Aus / Ein (Ein steht für 'aktivierbar); ; ADR/ACC 'Gerastet AUS / 'Nicht Gerastet AUS; ; Bei Sender-Codierung '01 u. 10' sind Tipsignale entprellt.4 Positionen LSM (Sender-Codierung '11') überträgt Tastsignal (Byte 4 Bit 5 gesetzt)";
CM_ SG_ 906 GRA_Neu_Zaehler "Botschaftszähler (GRA_Neu)
Botschaftszähler zur Erkennung fehlender und veraltetet Botschaften, Definition im CAN-Lastenheft";
CM_ SG_ 906 GRA_Sender "Sender Codierung
Sender der Original-Information wird hier eingetragen; die Botschaft wird in einigen Fahrzeugen vom Gateway gespiegelt (z.B. LSM in der D-Klasse) ;";
CM_ SG_ 906 GRA_Sta_Limiter "Limiter ein
Variable Geschwindigkeitsbegrenzung ist eingeschaltet ; (z.Zt. ist die Nutzung nicht geklärt)";
CM_ SG_ 906 GRA_Sportschalter "Sportschalter ein
z. Zt. nur Audi B7 RS4 (bewirkt Fahrpedal-Kennlinienumschaltung im Motor-SG)";
CM_ SG_ 906 GRA_Abbrechen "Abbrechen
GRA: 'GRA Aus mit Speichern bzw. ADR/ACC: 'Soft AUS ; Bei Sender-Codierung '01 u. 10' sind Tipsignale entprellt.";
CM_ SG_ 906 GRA_Down_kurz "KurzTip-down
GRA-Tipschalter 'Verzögern / Tip Down ; ADR/ACC-Tipschalter 'Kurz Tip Down; ; Bei Sender-Codierung '00' und '11' wird hier 'Setzen/Verzögern' übertragen (4 Position Lenkstockschalter, siehe auch Konzernspec. GRA).  ; Bei Sender Codierung '01 u. 10' sind Tipsignale entprellt.";
CM_ SG_ 906 GRA_Fehler_Tip "Tiptronik-Bedienteil Fehler
Wird gesendet bei Codierung '01' und '11' Bedienteil hat einen Fehler erkannt";
CM_ SG_ 906 GRA_Up_kurz "KurzTip-up
GRA-Tipschalter 'Beschleunigen / Tip-up ; ADR/ACC-Tipschalter 'Kurz Tip Up; ; Bei Sender-Codierung '00' und '11' wird hier 'Wiederaufnahme/Beschleunigen' übertragen (4 Position Lenkstockschalter, siehe auch Konzernspec. GRA). ; Bei Sender Codierung '01 u. 10' sind Tipsignale entprellt.";
CM_ SG_ 906 GRA_Up_lang "LangTip-up
Betätigung des Tipschalters 'Kurz Tip Upfür t > 0.5 sec bedeutet bei GRA 'Beschleunigen'  ; bzw. bei ADR/ACC 'Lang Tip Up";
CM_ SG_ 906 GRA_Down_lang "LangTip-down
Betätigung des Tipschalters 'Kurz Tip Down für t > 0.5 sec bedeutet bei GRA 'Verzögern' bzw. bei ADR/ACC 'Lang Tip Down";
CM_ SG_ 906 GRA_Neu_Setzen "GRA / ADR-Tipschalter 'Setzen'
Für ADR/ACC: Tipschalter 'SET' ; Bei Sender-Codierung '00' und '11' wird hier immer '0' übertragen (4 Position Lenkstockschalter, siehe auch Konzernspec. GRA) ; Bei B6 Bedienhebel eigene Taste sonst aus Tipschalter 'Kurz-Tip-down' generiert. ; Bei Sender Codierung '01 u. 10' sind Tipsignale entprellt.";
CM_ SG_ 906 GRA_Tip_Down "Tiptronik-Tip-Down
Wird gesendet bei Codierung '01' und '11' Übertragungszeit Tastenbetätigung bis CAN-Signal im Eingangspuffer des Getriebesteuergerätes maximal 100ms";
CM_ SG_ 906 GRA_Recall "GRA / ADR-Tipschalter 'Wiederaufnahme'
Für ADR/ACC: Tipschalter 'RESUME' ; Bei Sender Codierung '00' und '11' wird hier immer '0' übertragen (4 Position Lenkstockschalter, siehe auch Konzernspec. GRA) ; Bei B6 Bedienhebel eigene Taste sonst aus Tipschalter 'Kurz-Tip-up' generiert. ; Bei Sender Codierung '01 u. 10' sind Tipsignale entprellt.";
CM_ SG_ 906 GRA_Tip_Up "Tiptronik-Tip-Up
Wird gesendet bei Codierung '01' und '11' Übertragungszeit Tastenbetätigung bis CAN-Signal im Eingangspuffer des Getriebesteuergerätes maximal 100ms";
CM_ SG_ 906 GRA_Zeitluecke "Zeitlückenverstellung
DIST -1: Zeitlücke um 1 Stufe kleiner ; DIST +1: Zeitlücke um 1 Stufe größer";
CM_ SG_ 906 GRA_Typ_Hauptschalt "Typ Hauptschalter
Hauptschalter (Byte 2, Bit 0) ist gerastet Schalter oder getastet ausgeführt (im PQ24/T5 immer 0=gerastet)";
CM_ SG_ 906 GRA_Fehler_Bed "Bedienteil Fehler (GRA_Neu)
Im Bedienteil selbst wurde ein Fehler erkannt und im sendenden Steuergerät abgelegt";
BA_DEF_ BO_  "VAGTP20_API" HEX 0 255;
BA_DEF_ BO_  "VAGTP20_StatConnection" ENUM  "No","Yes";
BA_DEF_ BO_  "VAGTP20_DynConnection" ENUM  "No","Yes";
BA_DEF_ BO_  "VAGTP20_DynSetup" ENUM  "No","Yes";
BA_DEF_ BO_  "NmMessage" ENUM  "No","Yes";
BA_DEF_ BO_  "NmhMessage" ENUM  "No","Yes";
BA_DEF_ BO_  "GenMsgCycleTime" INT 0 65535;
BA_DEF_ BO_  "GenMsgSendType" ENUM  "cyclicX","spontanX","cyclicIfActiveX","spontanWithDelay","cyclicAndSpontanX","cyclicAndSpontanWithDelay","spontanWithRepitition","cyclicIfActiveAndSpontanWD","NoMsgSendType","cyclicWithRepeatOnDemand";
BA_DEF_ BO_  "GenMsgCycleTimeFast" INT 0 65535;
BA_DEF_ BO_  "GenMsgNrOfRepetition" INT 0 255;
BA_DEF_ BO_  "GenMsgDelayTime" INT 0 100000;
BA_DEF_ BO_  "GenMsgILSupport" ENUM  "No","Yes";
BA_DEF_ BO_  "GenMsgTimeoutTime" INT 0 100000;
BA_DEF_ BO_  "GenMsgAutoGenDsp" ENUM  "No","Yes";
BA_DEF_ BO_  "GenMsgAutoGenSnd" ENUM  "No","Yes";
BA_DEF_ BO_  "DiagRequest" ENUM  "No","Yes";
BA_DEF_ BO_  "DiagResponse" ENUM  "No","Yes";
BA_DEF_ BO_  "DiagState" ENUM  "No","Yes";
BA_DEF_ SG_  "GenSigSendType" ENUM  "Cyclic","OnWrite","OnWriteWithRepetition","OnChange","OnChangeWithRepetition","IfActive","IfActiveWithRepetition","NoSigSendType";
BA_DEF_ SG_  "GenSigStartValue" INT 0 4294967295;
BA_DEF_ SG_  "GenSigInactiveValue" INT 0 2147483647;
BA_DEF_ SG_  "GenSigAutoGenDsp" ENUM  "No","Yes";
BA_DEF_ SG_  "GenSigAutoGenSnd" ENUM  "No","Yes";
BA_DEF_ SG_  "GenSigEnvVarType" STRING ;
BA_DEF_ SG_  "GenSigFuncType" ENUM  "NoFunction","MsgCounter","CRC-8","XOR","XOR-2","DatedBit","SW-Kl15","CHK","Constant","Protokoll";
BA_DEF_ SG_  "NWM-WakeUpAllowed" ENUM  "No","Yes";
BA_DEF_ SG_  "INIT" STRING ;
BA_DEF_ SG_  "GenSigTimeoutMsg_Airbag" HEX 0 2047;
BA_DEF_ SG_  "GenSigTimeoutTime_Airbag" INT 0 65535;
BA_DEF_ SG_  "GenSigTimeoutMsg_Allrad" HEX 0 2047;
BA_DEF_ SG_  "GenSigTimeoutTime_Allrad" INT 0 65535;
BA_DEF_ SG_  "GenSigTimeoutMsg_Lenkhilfe_ZF_2" HEX 0 2047;
BA_DEF_ SG_  "GenSigTimeoutTime_Lenkhilfe_ZF_2" INT 0 65535;
BA_DEF_ SG_  "GenSigTimeoutMsg_Teves_MK60_ESP" HEX 0 2047;
BA_DEF_ SG_  "GenSigTimeoutTime_Teves_MK60_ESP" INT 0 65535;
BA_DEF_ SG_  "GenSigTimeoutMsg_LWS" HEX 0 2047;
BA_DEF_ SG_  "GenSigTimeoutTime_LWS" INT 0 65535;
BA_DEF_ SG_  "GenSigTimeoutMsg_LWR" HEX 0 2047;
BA_DEF_ SG_  "GenSigTimeoutTime_LWR" INT 0 65535;
BA_DEF_ SG_  "GenSigTimeoutMsg_Teves_MK70_MAB" HEX 0 2047;
BA_DEF_ SG_  "GenSigTimeoutTime_Teves_MK70_MAB" INT 0 65535;
BA_DEF_ SG_  "GenSigTimeoutMsg_Waehlhebel" HEX 0 2047;
BA_DEF_ SG_  "GenSigTimeoutTime_Waehlhebel" INT 0 65535;
BA_DEF_ SG_  "GenSigTimeoutMsg_EPB" HEX 0 2047;
BA_DEF_ SG_  "GenSigTimeoutTime_EPB" INT 0 65535;
BA_DEF_ SG_  "GenSigTimeoutMsg_TRW_ESP" HEX 0 2047;
BA_DEF_ SG_  "GenSigTimeoutTime_TRW_ESP" INT 0 65535;
BA_DEF_ SG_  "GenSigTimeoutMsg_ACC_Radar" HEX 0 2047;
BA_DEF_ SG_  "GenSigTimeoutTime_ACC_Radar" INT 0 65535;
BA_DEF_ SG_  "GenSigTimeoutMsg_AFS" HEX 0 2047;
BA_DEF_ SG_  "GenSigTimeoutTime_AFS" INT 0 65535;
BA_DEF_ SG_  "GenSigTimeoutMsg_Magne_Ride" HEX 0 2047;
BA_DEF_ SG_  "GenSigTimeoutTime_Magne_Ride" INT 0 65535;
BA_DEF_ SG_  "GenSigTimeoutMsg_RKA_Plus" HEX 0 2047;
BA_DEF_ SG_  "GenSigTimeoutTime_RKA_Plus" INT 0 65535;
BA_DEF_ SG_  "GenSigTimeoutMsg_Selespeed" HEX 0 2047;
BA_DEF_ SG_  "GenSigTimeoutTime_Selespeed" INT 0 65535;
BA_DEF_ SG_  "GenSigTimeoutMsg_Waehlhebel_Sel" HEX 0 2047;
BA_DEF_ SG_  "GenSigTimeoutTime_Waehlhebel_Sel" INT 0 65535;
BA_DEF_ SG_  "GenSigTimeoutMsg_PDC_PLA" HEX 0 2047;
BA_DEF_ SG_  "GenSigTimeoutTime_PDC_PLA" INT 0 65535;
BA_DEF_ SG_  "GenSigTimeoutMsg_Lenkhilfe_APA" HEX 0 2047;
BA_DEF_ SG_  "GenSigTimeoutTime_Lenkhilfe_APA" INT 0 65535;
BA_DEF_ SG_  "GenSigTimeoutMsg_VAQ" HEX 0 2047;
BA_DEF_ SG_  "GenSigTimeoutTime_VAQ" INT 0 65535;
BA_DEF_ SG_  "GenSigTimeoutMsg_Daempfer" HEX 0 2047;
BA_DEF_ SG_  "GenSigTimeoutTime_Daempfer" INT 0 65535;
BA_DEF_ SG_  "GenSigTimeoutMsg_Hybrid_BMS" HEX 0 2047;
BA_DEF_ SG_  "GenSigTimeoutTime_Hybrid_BMS" INT 0 65535;
BA_DEF_ SG_  "GenSigTimeoutMsg_Hybrid_PWR" HEX 0 2047;
BA_DEF_ SG_  "GenSigTimeoutTime_Hybrid_PWR" INT 0 65535;
BA_DEF_ SG_  "GenSigTimeoutMsg_Hybrid_DQ200" HEX 0 2047;
BA_DEF_ SG_  "GenSigTimeoutTime_Hybrid_DQ200" INT 0 65535;
BA_DEF_ SG_  "GenSigTimeoutMsg_EKlimakomp" HEX 0 2047;
BA_DEF_ SG_  "GenSigTimeoutTime_EKlimakomp" INT 0 65535;
BA_DEF_ SG_  "GenSigTimeoutMsg_SWA" HEX 0 2047;
BA_DEF_ SG_  "GenSigTimeoutTime_SWA" INT 0 65535;
BA_DEF_ SG_  "GenSigTimeoutMsg_HCA" HEX 0 2047;
BA_DEF_ SG_  "GenSigTimeoutTime_HCA" INT 0 65535;
BA_DEF_ SG_  "GenSigTimeoutMsg_ACC_Lidar" HEX 0 2047;
BA_DEF_ SG_  "GenSigTimeoutTime_ACC_Lidar" INT 0 65535;
BA_DEF_ SG_  "GenSigTimeoutMsg_Lenkhilfe_ZF_3" HEX 0 2047;
BA_DEF_ SG_  "GenSigTimeoutTime_Lenkhilfe_ZF_3" INT 0 65535;
BA_DEF_ SG_  "GenSigTimeoutMsg_FLA" HEX 0 2047;
BA_DEF_ SG_  "GenSigTimeoutTime_FLA" INT 0 65535;
BA_DEF_ SG_  "GenSigTimeoutMsg_AG6" HEX 0 2047;
BA_DEF_ SG_  "GenSigTimeoutTime_AG6" INT 0 65535;
BA_DEF_ SG_  "GenSigTimeoutMsg_DQ" HEX 0 2047;
BA_DEF_ SG_  "GenSigTimeoutTime_DQ" INT 0 65535;
BA_DEF_ SG_  "GenSigTimeoutMsg_Hybrid_MSG" HEX 0 2047;
BA_DEF_ SG_  "GenSigTimeoutTime_Hybrid_MSG" INT 0 65535;
BA_DEF_ SG_  "GenSigTimeoutMsg_Diesel" HEX 0 2047;
BA_DEF_ SG_  "GenSigTimeoutTime_Diesel" INT 0 65535;
BA_DEF_ SG_  "GenSigTimeoutMsg_Otto" HEX 0 2047;
BA_DEF_ SG_  "GenSigTimeoutTime_Otto" INT 0 65535;
BA_DEF_ SG_  "GenSigTimeoutMsg_Gateway_PQ35_A" HEX 0 2047;
BA_DEF_ SG_  "GenSigTimeoutTime_Gateway_PQ35_A" INT 0 65535;
BA_DEF_ SG_  "GenSigTimeoutMsg_Gateway_PQ46_A" HEX 0 2047;
BA_DEF_ SG_  "GenSigTimeoutTime_Gateway_PQ46_A" INT 0 65535;
BA_DEF_DEF_  "VAGTP20_API" 0;
BA_DEF_DEF_  "VAGTP20_StatConnection" "No";
BA_DEF_DEF_  "VAGTP20_DynConnection" "No";
BA_DEF_DEF_  "VAGTP20_DynSetup" "No";
BA_DEF_DEF_  "NmMessage" "No";
BA_DEF_DEF_  "NmhMessage" "No";
BA_DEF_DEF_  "GenMsgCycleTime" 0;
BA_DEF_DEF_  "GenMsgSendType" "NoMsgSendType";
BA_DEF_DEF_  "GenMsgCycleTimeFast" 0;
BA_DEF_DEF_  "GenMsgNrOfRepetition" 0;
BA_DEF_DEF_  "GenMsgDelayTime" 0;
BA_DEF_DEF_  "GenMsgILSupport" "No";
BA_DEF_DEF_  "GenMsgTimeoutTime" 0;
BA_DEF_DEF_  "GenMsgAutoGenDsp" "Yes";
BA_DEF_DEF_  "GenMsgAutoGenSnd" "Yes";
BA_DEF_DEF_  "DiagRequest" "No";
BA_DEF_DEF_  "DiagResponse" "No";
BA_DEF_DEF_  "DiagState" "No";
BA_DEF_DEF_  "GenSigSendType" "NoSigSendType";
BA_DEF_DEF_  "GenSigStartValue" 0;
BA_DEF_DEF_  "GenSigInactiveValue" 0;
BA_DEF_DEF_  "GenSigAutoGenDsp" "Yes";
BA_DEF_DEF_  "GenSigAutoGenSnd" "Yes";
BA_DEF_DEF_  "GenSigEnvVarType" "Undef";
BA_DEF_DEF_  "GenSigFuncType" "NoFunction";
BA_DEF_DEF_  "NWM-WakeUpAllowed" "No";
BA_DEF_DEF_  "INIT" "";
BA_DEF_DEF_  "GenSigTimeoutMsg_Airbag" 0;
BA_DEF_DEF_  "GenSigTimeoutTime_Airbag" 0;
BA_DEF_DEF_  "GenSigTimeoutMsg_Allrad" 0;
BA_DEF_DEF_  "GenSigTimeoutTime_Allrad" 0;
BA_DEF_DEF_  "GenSigTimeoutMsg_Lenkhilfe_ZF_2" 0;
BA_DEF_DEF_  "GenSigTimeoutTime_Lenkhilfe_ZF_2" 0;
BA_DEF_DEF_  "GenSigTimeoutMsg_Teves_MK60_ESP" 0;
BA_DEF_DEF_  "GenSigTimeoutTime_Teves_MK60_ESP" 0;
BA_DEF_DEF_  "GenSigTimeoutMsg_LWS" 0;
BA_DEF_DEF_  "GenSigTimeoutTime_LWS" 0;
BA_DEF_DEF_  "GenSigTimeoutMsg_LWR" 0;
BA_DEF_DEF_  "GenSigTimeoutTime_LWR" 0;
BA_DEF_DEF_  "GenSigTimeoutMsg_Teves_MK70_MAB" 0;
BA_DEF_DEF_  "GenSigTimeoutTime_Teves_MK70_MAB" 0;
BA_DEF_DEF_  "GenSigTimeoutMsg_Waehlhebel" 0;
BA_DEF_DEF_  "GenSigTimeoutTime_Waehlhebel" 0;
BA_DEF_DEF_  "GenSigTimeoutMsg_EPB" 0;
BA_DEF_DEF_  "GenSigTimeoutTime_EPB" 0;
BA_DEF_DEF_  "GenSigTimeoutMsg_TRW_ESP" 0;
BA_DEF_DEF_  "GenSigTimeoutTime_TRW_ESP" 0;
BA_DEF_DEF_  "GenSigTimeoutMsg_ACC_Radar" 0;
BA_DEF_DEF_  "GenSigTimeoutTime_ACC_Radar" 0;
BA_DEF_DEF_  "GenSigTimeoutMsg_AFS" 0;
BA_DEF_DEF_  "GenSigTimeoutTime_AFS" 0;
BA_DEF_DEF_  "GenSigTimeoutMsg_Magne_Ride" 0;
BA_DEF_DEF_  "GenSigTimeoutTime_Magne_Ride" 0;
BA_DEF_DEF_  "GenSigTimeoutMsg_RKA_Plus" 0;
BA_DEF_DEF_  "GenSigTimeoutTime_RKA_Plus" 0;
BA_DEF_DEF_  "GenSigTimeoutMsg_Selespeed" 0;
BA_DEF_DEF_  "GenSigTimeoutTime_Selespeed" 0;
BA_DEF_DEF_  "GenSigTimeoutMsg_Waehlhebel_Sel" 0;
BA_DEF_DEF_  "GenSigTimeoutTime_Waehlhebel_Sel" 0;
BA_DEF_DEF_  "GenSigTimeoutMsg_PDC_PLA" 0;
BA_DEF_DEF_  "GenSigTimeoutTime_PDC_PLA" 0;
BA_DEF_DEF_  "GenSigTimeoutMsg_Lenkhilfe_APA" 0;
BA_DEF_DEF_  "GenSigTimeoutTime_Lenkhilfe_APA" 0;
BA_DEF_DEF_  "GenSigTimeoutMsg_VAQ" 0;
BA_DEF_DEF_  "GenSigTimeoutTime_VAQ" 0;
BA_DEF_DEF_  "GenSigTimeoutMsg_Daempfer" 0;
BA_DEF_DEF_  "GenSigTimeoutTime_Daempfer" 0;
BA_DEF_DEF_  "GenSigTimeoutMsg_Hybrid_BMS" 0;
BA_DEF_DEF_  "GenSigTimeoutTime_Hybrid_BMS" 0;
BA_DEF_DEF_  "GenSigTimeoutMsg_Hybrid_PWR" 0;
BA_DEF_DEF_  "GenSigTimeoutTime_Hybrid_PWR" 0;
BA_DEF_DEF_  "GenSigTimeoutMsg_Hybrid_DQ200" 0;
BA_DEF_DEF_  "GenSigTimeoutTime_Hybrid_DQ200" 0;
BA_DEF_DEF_  "GenSigTimeoutMsg_EKlimakomp" 0;
BA_DEF_DEF_  "GenSigTimeoutTime_EKlimakomp" 0;
BA_DEF_DEF_  "GenSigTimeoutMsg_SWA" 0;
BA_DEF_DEF_  "GenSigTimeoutTime_SWA" 0;
BA_DEF_DEF_  "GenSigTimeoutMsg_HCA" 0;
BA_DEF_DEF_  "GenSigTimeoutTime_HCA" 0;
BA_DEF_DEF_  "GenSigTimeoutMsg_ACC_Lidar" 0;
BA_DEF_DEF_  "GenSigTimeoutTime_ACC_Lidar" 0;
BA_DEF_DEF_  "GenSigTimeoutMsg_Lenkhilfe_ZF_3" 0;
BA_DEF_DEF_  "GenSigTimeoutTime_Lenkhilfe_ZF_3" 0;
BA_DEF_DEF_  "GenSigTimeoutMsg_FLA" 0;
BA_DEF_DEF_  "GenSigTimeoutTime_FLA" 0;
BA_DEF_DEF_  "GenSigTimeoutMsg_AG6" 0;
BA_DEF_DEF_  "GenSigTimeoutTime_AG6" 0;
BA_DEF_DEF_  "GenSigTimeoutMsg_DQ" 0;
BA_DEF_DEF_  "GenSigTimeoutTime_DQ" 0;
BA_DEF_DEF_  "GenSigTimeoutMsg_Hybrid_MSG" 0;
BA_DEF_DEF_  "GenSigTimeoutTime_Hybrid_MSG" 0;
BA_DEF_DEF_  "GenSigTimeoutMsg_Diesel" 0;
BA_DEF_DEF_  "GenSigTimeoutTime_Diesel" 0;
BA_DEF_DEF_  "GenSigTimeoutMsg_Otto" 0;
BA_DEF_DEF_  "GenSigTimeoutTime_Otto" 0;
BA_DEF_DEF_  "GenSigTimeoutMsg_Gateway_PQ35_A" 0;
BA_DEF_DEF_  "GenSigTimeoutTime_Gateway_PQ35_A" 0;
BA_DEF_DEF_  "GenSigTimeoutMsg_Gateway_PQ46_A" 0;
BA_DEF_DEF_  "GenSigTimeoutTime_Gateway_PQ46_A" 0;
BA_ "GenMsgTimeoutTime" BO_ 1164 500;
BA_ "GenMsgSendType" BO_ 1164 0;
BA_ "GenMsgCycleTime" BO_ 1164 40;
BA_ "GenMsgTimeoutTime" BO_ 1423 5000;
BA_ "GenMsgSendType" BO_ 1423 0;
BA_ "GenMsgCycleTime" BO_ 1423 500;
BA_ "GenMsgTimeoutTime" BO_ 1823 1000;
BA_ "GenMsgSendType" BO_ 1823 0;
BA_ "GenMsgCycleTime" BO_ 1823 100;
BA_ "GenMsgTimeoutTime" BO_ 1800 2000;
BA_ "GenMsgSendType" BO_ 1800 0;
BA_ "GenMsgCycleTime" BO_ 1800 200;
BA_ "GenMsgSendType" BO_ 1888 1;
BA_ "VAGTP20_DynConnection" BO_ 1888 1;
BA_ "GenMsgSendType" BO_ 1897 1;
BA_ "VAGTP20_DynConnection" BO_ 1897 1;
BA_ "GenMsgSendType" BO_ 1960 1;
BA_ "VAGTP20_DynConnection" BO_ 1960 1;
BA_ "GenMsgSendType" BO_ 1889 1;
BA_ "VAGTP20_DynConnection" BO_ 1889 1;
BA_ "GenMsgSendType" BO_ 1924 1;
BA_ "VAGTP20_DynConnection" BO_ 1924 1;
BA_ "GenMsgSendType" BO_ 1925 1;
BA_ "VAGTP20_DynConnection" BO_ 1925 1;
BA_ "GenMsgSendType" BO_ 1961 1;
BA_ "VAGTP20_DynConnection" BO_ 1961 1;
BA_ "GenMsgSendType" BO_ 1892 1;
BA_ "VAGTP20_DynConnection" BO_ 1892 1;
BA_ "GenMsgSendType" BO_ 1937 1;
BA_ "VAGTP20_DynConnection" BO_ 1937 1;
BA_ "GenMsgSendType" BO_ 1896 1;
BA_ "VAGTP20_DynConnection" BO_ 1896 1;
BA_ "GenMsgSendType" BO_ 1936 1;
BA_ "VAGTP20_DynConnection" BO_ 1936 1;
BA_ "GenMsgTimeoutTime" BO_ 800 500;
BA_ "GenMsgCycleTimeFast" BO_ 800 20;
BA_ "GenMsgSendType" BO_ 800 0;
BA_ "GenMsgCycleTime" BO_ 800 25;
BA_ "GenMsgTimeoutTime" BO_ 1306 5000;
BA_ "GenMsgSendType" BO_ 1306 0;
BA_ "GenMsgCycleTime" BO_ 1306 500;
BA_ "GenMsgTimeoutTime" BO_ 1312 2000;
BA_ "GenMsgSendType" BO_ 1312 0;
BA_ "GenMsgCycleTime" BO_ 1312 200;
BA_ "GenMsgTimeoutTime" BO_ 1056 2000;
BA_ "GenMsgSendType" BO_ 1056 0;
BA_ "GenMsgCycleTime" BO_ 1056 200;
BA_ "GenMsgTimeoutTime" BO_ 912 1000;
BA_ "GenMsgDelayTime" BO_ 912 50;
BA_ "GenMsgSendType" BO_ 912 0;
BA_ "GenMsgCycleTime" BO_ 912 100;
BA_ "GenMsgTimeoutTime" BO_ 1490 2000;
BA_ "GenMsgSendType" BO_ 1490 0;
BA_ "GenMsgCycleTime" BO_ 1490 200;
BA_ "GenMsgTimeoutTime" BO_ 906 500;
BA_ "GenMsgSendType" BO_ 906 0;
BA_ "GenMsgCycleTime" BO_ 906 20;
BA_ "GenSigTimeoutTime_ACC_Radar" SG_ 1164 HS1_res_24 500;
BA_ "GenSigTimeoutMsg_ACC_Radar" SG_ 1164 HS1_res_24 1164;
BA_ "GenSigTimeoutTime_ACC_Lidar" SG_ 1164 HS1_res_24 500;
BA_ "GenSigTimeoutMsg_ACC_Lidar" SG_ 1164 HS1_res_24 1164;
BA_ "GenSigTimeoutTime_Gateway_PQ35_A" SG_ 1164 HS1_res_24 500;
BA_ "GenSigTimeoutMsg_Gateway_PQ35_A" SG_ 1164 HS1_res_24 1164;
BA_ "GenSigTimeoutTime_Gateway_PQ46_A" SG_ 1164 HS1_res_24 500;
BA_ "GenSigTimeoutMsg_Gateway_PQ46_A" SG_ 1164 HS1_res_24 1164;
BA_ "GenSigSendType" SG_ 1164 HS1_res_24 0;
BA_ "GenSigTimeoutTime_ACC_Lidar" SG_ 1164 HS1_Checksumme 500;
BA_ "GenSigTimeoutMsg_ACC_Lidar" SG_ 1164 HS1_Checksumme 1164;
BA_ "GenSigTimeoutTime_ACC_Radar" SG_ 1164 HS1_Checksumme 500;
BA_ "GenSigTimeoutMsg_ACC_Radar" SG_ 1164 HS1_Checksumme 1164;
BA_ "GenSigTimeoutTime_Gateway_PQ35_A" SG_ 1164 HS1_Checksumme 500;
BA_ "GenSigTimeoutMsg_Gateway_PQ35_A" SG_ 1164 HS1_Checksumme 1164;
BA_ "GenSigTimeoutTime_Gateway_PQ46_A" SG_ 1164 HS1_Checksumme 500;
BA_ "GenSigTimeoutMsg_Gateway_PQ46_A" SG_ 1164 HS1_Checksumme 1164;
BA_ "GenSigSendType" SG_ 1164 HS1_Checksumme 0;
BA_ "INIT" SG_ 1164 HS1_Checksumme "CHK";
BA_ "GenSigTimeoutTime_ACC_Radar" SG_ 1164 HS1_res_32 500;
BA_ "GenSigTimeoutMsg_ACC_Radar" SG_ 1164 HS1_res_32 1164;
BA_ "GenSigTimeoutTime_ACC_Lidar" SG_ 1164 HS1_res_32 500;
BA_ "GenSigTimeoutMsg_ACC_Lidar" SG_ 1164 HS1_res_32 1164;
BA_ "GenSigTimeoutTime_Gateway_PQ35_A" SG_ 1164 HS1_res_32 500;
BA_ "GenSigTimeoutMsg_Gateway_PQ35_A" SG_ 1164 HS1_res_32 1164;
BA_ "GenSigTimeoutTime_Gateway_PQ46_A" SG_ 1164 HS1_res_32 500;
BA_ "GenSigTimeoutMsg_Gateway_PQ46_A" SG_ 1164 HS1_res_32 1164;
BA_ "GenSigSendType" SG_ 1164 HS1_res_32 0;
BA_ "GenSigTimeoutTime_ACC_Radar" SG_ 1164 HS1_res_48 500;
BA_ "GenSigTimeoutMsg_ACC_Radar" SG_ 1164 HS1_res_48 1164;
BA_ "GenSigTimeoutTime_ACC_Lidar" SG_ 1164 HS1_res_48 500;
BA_ "GenSigTimeoutMsg_ACC_Lidar" SG_ 1164 HS1_res_48 1164;
BA_ "GenSigTimeoutTime_Gateway_PQ35_A" SG_ 1164 HS1_res_48 500;
BA_ "GenSigTimeoutMsg_Gateway_PQ35_A" SG_ 1164 HS1_res_48 1164;
BA_ "GenSigTimeoutTime_Gateway_PQ46_A" SG_ 1164 HS1_res_48 500;
BA_ "GenSigTimeoutMsg_Gateway_PQ46_A" SG_ 1164 HS1_res_48 1164;
BA_ "GenSigSendType" SG_ 1164 HS1_res_48 0;
BA_ "GenSigTimeoutTime_ACC_Radar" SG_ 1164 HS1_res_19 500;
BA_ "GenSigTimeoutMsg_ACC_Radar" SG_ 1164 HS1_res_19 1164;
BA_ "GenSigTimeoutTime_ACC_Lidar" SG_ 1164 HS1_res_19 500;
BA_ "GenSigTimeoutMsg_ACC_Lidar" SG_ 1164 HS1_res_19 1164;
BA_ "GenSigTimeoutTime_Gateway_PQ35_A" SG_ 1164 HS1_res_19 500;
BA_ "GenSigTimeoutMsg_Gateway_PQ35_A" SG_ 1164 HS1_res_19 1164;
BA_ "GenSigTimeoutTime_Gateway_PQ46_A" SG_ 1164 HS1_res_19 500;
BA_ "GenSigTimeoutMsg_Gateway_PQ46_A" SG_ 1164 HS1_res_19 1164;
BA_ "GenSigSendType" SG_ 1164 HS1_res_19 0;
BA_ "GenSigTimeoutTime_ACC_Radar" SG_ 1164 HS1_res_60 500;
BA_ "GenSigTimeoutMsg_ACC_Radar" SG_ 1164 HS1_res_60 1164;
BA_ "GenSigTimeoutTime_ACC_Lidar" SG_ 1164 HS1_res_60 500;
BA_ "GenSigTimeoutMsg_ACC_Lidar" SG_ 1164 HS1_res_60 1164;
BA_ "GenSigTimeoutTime_Gateway_PQ35_A" SG_ 1164 HS1_res_60 500;
BA_ "GenSigTimeoutMsg_Gateway_PQ35_A" SG_ 1164 HS1_res_60 1164;
BA_ "GenSigTimeoutTime_Gateway_PQ46_A" SG_ 1164 HS1_res_60 500;
BA_ "GenSigTimeoutMsg_Gateway_PQ46_A" SG_ 1164 HS1_res_60 1164;
BA_ "GenSigSendType" SG_ 1164 HS1_res_60 0;
BA_ "GenSigTimeoutTime_ACC_Radar" SG_ 1164 HS1_res_40 500;
BA_ "GenSigTimeoutMsg_ACC_Radar" SG_ 1164 HS1_res_40 1164;
BA_ "GenSigTimeoutTime_ACC_Lidar" SG_ 1164 HS1_res_40 500;
BA_ "GenSigTimeoutMsg_ACC_Lidar" SG_ 1164 HS1_res_40 1164;
BA_ "GenSigTimeoutTime_Gateway_PQ35_A" SG_ 1164 HS1_res_40 500;
BA_ "GenSigTimeoutMsg_Gateway_PQ35_A" SG_ 1164 HS1_res_40 1164;
BA_ "GenSigTimeoutTime_Gateway_PQ46_A" SG_ 1164 HS1_res_40 500;
BA_ "GenSigTimeoutMsg_Gateway_PQ46_A" SG_ 1164 HS1_res_40 1164;
BA_ "GenSigSendType" SG_ 1164 HS1_res_40 0;
BA_ "GenSigTimeoutTime_ACC_Lidar" SG_ 1164 HS1_Zaehler 500;
BA_ "GenSigTimeoutMsg_ACC_Lidar" SG_ 1164 HS1_Zaehler 1164;
BA_ "GenSigTimeoutTime_ACC_Radar" SG_ 1164 HS1_Zaehler 500;
BA_ "GenSigTimeoutMsg_ACC_Radar" SG_ 1164 HS1_Zaehler 1164;
BA_ "GenSigTimeoutTime_Gateway_PQ35_A" SG_ 1164 HS1_Zaehler 500;
BA_ "GenSigTimeoutMsg_Gateway_PQ35_A" SG_ 1164 HS1_Zaehler 1164;
BA_ "GenSigTimeoutTime_Gateway_PQ46_A" SG_ 1164 HS1_Zaehler 500;
BA_ "GenSigTimeoutMsg_Gateway_PQ46_A" SG_ 1164 HS1_Zaehler 1164;
BA_ "GenSigSendType" SG_ 1164 HS1_Zaehler 0;
BA_ "GenSigTimeoutTime_ACC_Radar" SG_ 1164 HS1_res_56 500;
BA_ "GenSigTimeoutMsg_ACC_Radar" SG_ 1164 HS1_res_56 1164;
BA_ "GenSigTimeoutTime_ACC_Lidar" SG_ 1164 HS1_res_56 500;
BA_ "GenSigTimeoutMsg_ACC_Lidar" SG_ 1164 HS1_res_56 1164;
BA_ "GenSigTimeoutTime_Gateway_PQ35_A" SG_ 1164 HS1_res_56 500;
BA_ "GenSigTimeoutMsg_Gateway_PQ35_A" SG_ 1164 HS1_res_56 1164;
BA_ "GenSigTimeoutTime_Gateway_PQ46_A" SG_ 1164 HS1_res_56 500;
BA_ "GenSigTimeoutMsg_Gateway_PQ46_A" SG_ 1164 HS1_res_56 1164;
BA_ "GenSigSendType" SG_ 1164 HS1_res_56 0;
BA_ "GenSigTimeoutTime_ACC_Lidar" SG_ 1164 HS1_Gang 500;
BA_ "GenSigTimeoutMsg_ACC_Lidar" SG_ 1164 HS1_Gang 1164;
BA_ "GenSigTimeoutTime_Gateway_PQ35_A" SG_ 1164 HS1_Gang 500;
BA_ "GenSigTimeoutMsg_Gateway_PQ35_A" SG_ 1164 HS1_Gang 1164;
BA_ "GenSigTimeoutTime_Gateway_PQ46_A" SG_ 1164 HS1_Gang 500;
BA_ "GenSigTimeoutMsg_Gateway_PQ46_A" SG_ 1164 HS1_Gang 1164;
BA_ "GenSigTimeoutTime_ACC_Radar" SG_ 1164 HS1_Gang 500;
BA_ "GenSigTimeoutMsg_ACC_Radar" SG_ 1164 HS1_Gang 1164;
BA_ "GenSigSendType" SG_ 1164 HS1_Gang 0;
BA_ "GenSigStartValue" SG_ 1164 HS1_Gang 7;
BA_ "GenSigTimeoutTime_ACC_Radar" SG_ 1164 HS1_res_12 500;
BA_ "GenSigTimeoutMsg_ACC_Radar" SG_ 1164 HS1_res_12 1164;
BA_ "GenSigTimeoutTime_ACC_Lidar" SG_ 1164 HS1_res_12 500;
BA_ "GenSigTimeoutMsg_ACC_Lidar" SG_ 1164 HS1_res_12 1164;
BA_ "GenSigTimeoutTime_Gateway_PQ35_A" SG_ 1164 HS1_res_12 500;
BA_ "GenSigTimeoutMsg_Gateway_PQ35_A" SG_ 1164 HS1_res_12 1164;
BA_ "GenSigTimeoutTime_Gateway_PQ46_A" SG_ 1164 HS1_res_12 500;
BA_ "GenSigTimeoutMsg_Gateway_PQ46_A" SG_ 1164 HS1_res_12 1164;
BA_ "GenSigSendType" SG_ 1164 HS1_res_12 0;
BA_ "GenSigTimeoutTime_ACC_Lidar" SG_ 1164 HS1_Drehz_Grenze 500;
BA_ "GenSigTimeoutMsg_ACC_Lidar" SG_ 1164 HS1_Drehz_Grenze 1164;
BA_ "GenSigTimeoutTime_Gateway_PQ35_A" SG_ 1164 HS1_Drehz_Grenze 500;
BA_ "GenSigTimeoutMsg_Gateway_PQ35_A" SG_ 1164 HS1_Drehz_Grenze 1164;
BA_ "GenSigTimeoutTime_Gateway_PQ46_A" SG_ 1164 HS1_Drehz_Grenze 500;
BA_ "GenSigTimeoutMsg_Gateway_PQ46_A" SG_ 1164 HS1_Drehz_Grenze 1164;
BA_ "GenSigTimeoutTime_ACC_Radar" SG_ 1164 HS1_Drehz_Grenze 500;
BA_ "GenSigTimeoutMsg_ACC_Radar" SG_ 1164 HS1_Drehz_Grenze 1164;
BA_ "GenSigSendType" SG_ 1164 HS1_Drehz_Grenze 0;
BA_ "GenSigStartValue" SG_ 1164 HS1_Drehz_Grenze 1;
BA_ "GenSigTimeoutTime_ACC_Radar" SG_ 1164 HS1_res_20 500;
BA_ "GenSigTimeoutMsg_ACC_Radar" SG_ 1164 HS1_res_20 1164;
BA_ "GenSigTimeoutTime_ACC_Lidar" SG_ 1164 HS1_res_20 500;
BA_ "GenSigTimeoutMsg_ACC_Lidar" SG_ 1164 HS1_res_20 1164;
BA_ "GenSigTimeoutTime_Gateway_PQ35_A" SG_ 1164 HS1_res_20 500;
BA_ "GenSigTimeoutMsg_Gateway_PQ35_A" SG_ 1164 HS1_res_20 1164;
BA_ "GenSigTimeoutTime_Gateway_PQ46_A" SG_ 1164 HS1_res_20 500;
BA_ "GenSigTimeoutMsg_Gateway_PQ46_A" SG_ 1164 HS1_res_20 1164;
BA_ "GenSigSendType" SG_ 1164 HS1_res_20 0;
BA_ "GenSigTimeoutTime_ACC_Radar" SG_ 1164 HS1_res_22 500;
BA_ "GenSigTimeoutMsg_ACC_Radar" SG_ 1164 HS1_res_22 1164;
BA_ "GenSigTimeoutTime_ACC_Lidar" SG_ 1164 HS1_res_22 500;
BA_ "GenSigTimeoutMsg_ACC_Lidar" SG_ 1164 HS1_res_22 1164;
BA_ "GenSigTimeoutTime_Gateway_PQ35_A" SG_ 1164 HS1_res_22 500;
BA_ "GenSigTimeoutMsg_Gateway_PQ35_A" SG_ 1164 HS1_res_22 1164;
BA_ "GenSigTimeoutTime_Gateway_PQ46_A" SG_ 1164 HS1_res_22 500;
BA_ "GenSigTimeoutMsg_Gateway_PQ46_A" SG_ 1164 HS1_res_22 1164;
BA_ "GenSigSendType" SG_ 1164 HS1_res_22 0;
BA_ "GenSigTimeoutTime_ACC_Radar" SG_ 1164 HS1_res_23 500;
BA_ "GenSigTimeoutMsg_ACC_Radar" SG_ 1164 HS1_res_23 1164;
BA_ "GenSigTimeoutTime_ACC_Lidar" SG_ 1164 HS1_res_23 500;
BA_ "GenSigTimeoutMsg_ACC_Lidar" SG_ 1164 HS1_res_23 1164;
BA_ "GenSigTimeoutTime_Gateway_PQ35_A" SG_ 1164 HS1_res_23 500;
BA_ "GenSigTimeoutMsg_Gateway_PQ35_A" SG_ 1164 HS1_res_23 1164;
BA_ "GenSigTimeoutTime_Gateway_PQ46_A" SG_ 1164 HS1_res_23 500;
BA_ "GenSigTimeoutMsg_Gateway_PQ46_A" SG_ 1164 HS1_res_23 1164;
BA_ "GenSigSendType" SG_ 1164 HS1_res_23 0;
BA_ "GenSigSendType" SG_ 1164 HS1_res_53 0;
BA_ "GenSigSendType" SG_ 1164 HS1_res_54 0;
BA_ "GenSigTimeoutTime_Gateway_PQ35_A" SG_ 1423 M12_Reserve1 5000;
BA_ "GenSigTimeoutMsg_Gateway_PQ35_A" SG_ 1423 M12_Reserve1 1423;
BA_ "GenSigTimeoutTime_Gateway_PQ46_A" SG_ 1423 M12_Reserve1 5000;
BA_ "GenSigTimeoutMsg_Gateway_PQ46_A" SG_ 1423 M12_Reserve1 1423;
BA_ "GenSigSendType" SG_ 1423 M12_Reserve1 0;
BA_ "GenSigTimeoutTime_Gateway_PQ35_A" SG_ 1423 M12_Reserve2 5000;
BA_ "GenSigTimeoutMsg_Gateway_PQ35_A" SG_ 1423 M12_Reserve2 1423;
BA_ "GenSigTimeoutTime_Gateway_PQ46_A" SG_ 1423 M12_Reserve2 5000;
BA_ "GenSigTimeoutMsg_Gateway_PQ46_A" SG_ 1423 M12_Reserve2 1423;
BA_ "GenSigSendType" SG_ 1423 M12_Reserve2 0;
BA_ "GenSigTimeoutTime_Gateway_PQ46_A" SG_ 1423 M12_SCR_Anz_Motorstarts 5000;
BA_ "GenSigTimeoutMsg_Gateway_PQ46_A" SG_ 1423 M12_SCR_Anz_Motorstarts 1423;
BA_ "GenSigTimeoutTime_Gateway_PQ35_A" SG_ 1423 M12_SCR_Anz_Motorstarts 5000;
BA_ "GenSigTimeoutMsg_Gateway_PQ35_A" SG_ 1423 M12_SCR_Anz_Motorstarts 1423;
BA_ "GenSigSendType" SG_ 1423 M12_SCR_Anz_Motorstarts 0;
BA_ "GenSigStartValue" SG_ 1423 M12_SCR_Anz_Motorstarts 15;
BA_ "GenSigTimeoutTime_Gateway_PQ46_A" SG_ 1423 M12_SCR_Reichweite 5000;
BA_ "GenSigTimeoutMsg_Gateway_PQ46_A" SG_ 1423 M12_SCR_Reichweite 1423;
BA_ "GenSigTimeoutTime_Gateway_PQ35_A" SG_ 1423 M12_SCR_Reichweite 5000;
BA_ "GenSigTimeoutMsg_Gateway_PQ35_A" SG_ 1423 M12_SCR_Reichweite 1423;
BA_ "GenSigSendType" SG_ 1423 M12_SCR_Reichweite 0;
BA_ "GenSigStartValue" SG_ 1423 M12_SCR_Reichweite 32767;
BA_ "GenSigTimeoutTime_Gateway_PQ46_A" SG_ 1423 M12_SCR_Warnstufe_1 5000;
BA_ "GenSigTimeoutMsg_Gateway_PQ46_A" SG_ 1423 M12_SCR_Warnstufe_1 1423;
BA_ "GenSigTimeoutTime_Gateway_PQ35_A" SG_ 1423 M12_SCR_Warnstufe_1 5000;
BA_ "GenSigTimeoutMsg_Gateway_PQ35_A" SG_ 1423 M12_SCR_Warnstufe_1 1423;
BA_ "GenSigSendType" SG_ 1423 M12_SCR_Warnstufe_1 0;
BA_ "GenSigTimeoutTime_Gateway_PQ46_A" SG_ 1423 M12_SCR_Warnstufe_2 5000;
BA_ "GenSigTimeoutMsg_Gateway_PQ46_A" SG_ 1423 M12_SCR_Warnstufe_2 1423;
BA_ "GenSigTimeoutTime_Gateway_PQ35_A" SG_ 1423 M12_SCR_Warnstufe_2 5000;
BA_ "GenSigTimeoutMsg_Gateway_PQ35_A" SG_ 1423 M12_SCR_Warnstufe_2 1423;
BA_ "GenSigSendType" SG_ 1423 M12_SCR_Warnstufe_2 0;
BA_ "GenSigTimeoutTime_Gateway_PQ35_A" SG_ 1423 M12_Luftfilter_Lampe 5000;
BA_ "GenSigTimeoutMsg_Gateway_PQ35_A" SG_ 1423 M12_Luftfilter_Lampe 1423;
BA_ "GenSigTimeoutTime_Gateway_PQ46_A" SG_ 1423 M12_Luftfilter_Lampe 5000;
BA_ "GenSigTimeoutMsg_Gateway_PQ46_A" SG_ 1423 M12_Luftfilter_Lampe 1423;
BA_ "GenSigSendType" SG_ 1423 M12_Luftfilter_Lampe 0;
BA_ "GenSigTimeoutTime_Gateway_PQ35_A" SG_ 1423 M12_res_31 5000;
BA_ "GenSigTimeoutMsg_Gateway_PQ35_A" SG_ 1423 M12_res_31 1423;
BA_ "GenSigTimeoutTime_Gateway_PQ46_A" SG_ 1423 M12_res_31 5000;
BA_ "GenSigTimeoutMsg_Gateway_PQ46_A" SG_ 1423 M12_res_31 1423;
BA_ "GenSigSendType" SG_ 1423 M12_res_31 0;
BA_ "GenSigTimeoutTime_Gateway_PQ46_A" SG_ 1423 M12_Akustik 5000;
BA_ "GenSigTimeoutMsg_Gateway_PQ46_A" SG_ 1423 M12_Akustik 1423;
BA_ "GenSigTimeoutTime_Gateway_PQ35_A" SG_ 1423 M12_Akustik 5000;
BA_ "GenSigTimeoutMsg_Gateway_PQ35_A" SG_ 1423 M12_Akustik 1423;
BA_ "GenSigSendType" SG_ 1423 M12_Akustik 0;
BA_ "GenSigTimeoutTime_Gateway_PQ35_A" SG_ 1423 M12_res_40 5000;
BA_ "GenSigTimeoutMsg_Gateway_PQ35_A" SG_ 1423 M12_res_40 1423;
BA_ "GenSigTimeoutTime_Gateway_PQ46_A" SG_ 1423 M12_res_40 5000;
BA_ "GenSigTimeoutMsg_Gateway_PQ46_A" SG_ 1423 M12_res_40 1423;
BA_ "GenSigSendType" SG_ 1423 M12_res_40 0;
BA_ "GenSigTimeoutTime_Gateway_PQ46_A" SG_ 1423 M12_SCR_Systemfehler 5000;
BA_ "GenSigTimeoutMsg_Gateway_PQ46_A" SG_ 1423 M12_SCR_Systemfehler 1423;
BA_ "GenSigTimeoutTime_Gateway_PQ35_A" SG_ 1423 M12_SCR_Systemfehler 5000;
BA_ "GenSigTimeoutMsg_Gateway_PQ35_A" SG_ 1423 M12_SCR_Systemfehler 1423;
BA_ "GenSigSendType" SG_ 1423 M12_SCR_Systemfehler 0;
BA_ "GenSigTimeoutTime_Gateway_PQ46_A" SG_ 1423 M12_SCR_Text 5000;
BA_ "GenSigTimeoutMsg_Gateway_PQ46_A" SG_ 1423 M12_SCR_Text 1423;
BA_ "GenSigTimeoutTime_Gateway_PQ35_A" SG_ 1423 M12_SCR_Text 5000;
BA_ "GenSigTimeoutMsg_Gateway_PQ35_A" SG_ 1423 M12_SCR_Text 1423;
BA_ "GenSigSendType" SG_ 1423 M12_SCR_Text 0;
BA_ "GenSigTimeoutTime_Gateway_PQ46_A" SG_ 1423 M12_SCR_Inducement 5000;
BA_ "GenSigTimeoutMsg_Gateway_PQ46_A" SG_ 1423 M12_SCR_Inducement 1423;
BA_ "GenSigTimeoutTime_Gateway_PQ35_A" SG_ 1423 M12_SCR_Inducement 5000;
BA_ "GenSigTimeoutMsg_Gateway_PQ35_A" SG_ 1423 M12_SCR_Inducement 1423;
BA_ "GenSigSendType" SG_ 1423 M12_SCR_Inducement 0;
BA_ "INIT" SG_ 1423 M12_SCR_Inducement "const";
BA_ "GenSigTimeoutTime_Gateway_PQ35_A" SG_ 1423 M12_res_44 5000;
BA_ "GenSigTimeoutMsg_Gateway_PQ35_A" SG_ 1423 M12_res_44 1423;
BA_ "GenSigTimeoutTime_Gateway_PQ46_A" SG_ 1423 M12_res_44 5000;
BA_ "GenSigTimeoutMsg_Gateway_PQ46_A" SG_ 1423 M12_res_44 1423;
BA_ "GenSigSendType" SG_ 1423 M12_res_44 0;
BA_ "GenSigTimeoutTime_Gateway_PQ35_A" SG_ 1423 M12_res_45 5000;
BA_ "GenSigTimeoutMsg_Gateway_PQ35_A" SG_ 1423 M12_res_45 1423;
BA_ "GenSigTimeoutTime_Gateway_PQ46_A" SG_ 1423 M12_res_45 5000;
BA_ "GenSigTimeoutMsg_Gateway_PQ46_A" SG_ 1423 M12_res_45 1423;
BA_ "GenSigSendType" SG_ 1423 M12_res_45 0;
BA_ "GenSigTimeoutTime_Gateway_PQ35_A" SG_ 1423 M12_res_46 5000;
BA_ "GenSigTimeoutMsg_Gateway_PQ35_A" SG_ 1423 M12_res_46 1423;
BA_ "GenSigTimeoutTime_Gateway_PQ46_A" SG_ 1423 M12_res_46 5000;
BA_ "GenSigTimeoutMsg_Gateway_PQ46_A" SG_ 1423 M12_res_46 1423;
BA_ "GenSigSendType" SG_ 1423 M12_res_46 0;
BA_ "GenSigTimeoutTime_Gateway_PQ35_A" SG_ 1423 M12_res_47 5000;
BA_ "GenSigTimeoutMsg_Gateway_PQ35_A" SG_ 1423 M12_res_47 1423;
BA_ "GenSigTimeoutTime_Gateway_PQ46_A" SG_ 1423 M12_res_47 5000;
BA_ "GenSigTimeoutMsg_Gateway_PQ46_A" SG_ 1423 M12_res_47 1423;
BA_ "GenSigSendType" SG_ 1423 M12_res_47 0;
BA_ "GenSigTimeoutTime_Gateway_PQ35_A" SG_ 1423 M12_res_48 5000;
BA_ "GenSigTimeoutMsg_Gateway_PQ35_A" SG_ 1423 M12_res_48 1423;
BA_ "GenSigTimeoutTime_Gateway_PQ46_A" SG_ 1423 M12_res_48 5000;
BA_ "GenSigTimeoutMsg_Gateway_PQ46_A" SG_ 1423 M12_res_48 1423;
BA_ "GenSigSendType" SG_ 1423 M12_res_48 0;
BA_ "GenSigTimeoutTime_Gateway_PQ35_A" SG_ 1423 M12_res_49 5000;
BA_ "GenSigTimeoutMsg_Gateway_PQ35_A" SG_ 1423 M12_res_49 1423;
BA_ "GenSigTimeoutTime_Gateway_PQ46_A" SG_ 1423 M12_res_49 5000;
BA_ "GenSigTimeoutMsg_Gateway_PQ46_A" SG_ 1423 M12_res_49 1423;
BA_ "GenSigSendType" SG_ 1423 M12_res_49 0;
BA_ "GenSigTimeoutTime_Gateway_PQ35_A" SG_ 1423 M12_res_50 5000;
BA_ "GenSigTimeoutMsg_Gateway_PQ35_A" SG_ 1423 M12_res_50 1423;
BA_ "GenSigTimeoutTime_Gateway_PQ46_A" SG_ 1423 M12_res_50 5000;
BA_ "GenSigTimeoutMsg_Gateway_PQ46_A" SG_ 1423 M12_res_50 1423;
BA_ "GenSigSendType" SG_ 1423 M12_res_50 0;
BA_ "GenSigTimeoutTime_Gateway_PQ35_A" SG_ 1423 M12_res_51 5000;
BA_ "GenSigTimeoutMsg_Gateway_PQ35_A" SG_ 1423 M12_res_51 1423;
BA_ "GenSigTimeoutTime_Gateway_PQ46_A" SG_ 1423 M12_res_51 5000;
BA_ "GenSigTimeoutMsg_Gateway_PQ46_A" SG_ 1423 M12_res_51 1423;
BA_ "GenSigSendType" SG_ 1423 M12_res_51 0;
BA_ "GenSigTimeoutTime_Gateway_PQ35_A" SG_ 1423 M12_res_52 5000;
BA_ "GenSigTimeoutMsg_Gateway_PQ35_A" SG_ 1423 M12_res_52 1423;
BA_ "GenSigTimeoutTime_Gateway_PQ46_A" SG_ 1423 M12_res_52 5000;
BA_ "GenSigTimeoutMsg_Gateway_PQ46_A" SG_ 1423 M12_res_52 1423;
BA_ "GenSigSendType" SG_ 1423 M12_res_52 0;
BA_ "GenSigTimeoutTime_Gateway_PQ35_A" SG_ 1423 M12_res_53 5000;
BA_ "GenSigTimeoutMsg_Gateway_PQ35_A" SG_ 1423 M12_res_53 1423;
BA_ "GenSigTimeoutTime_Gateway_PQ46_A" SG_ 1423 M12_res_53 5000;
BA_ "GenSigTimeoutMsg_Gateway_PQ46_A" SG_ 1423 M12_res_53 1423;
BA_ "GenSigSendType" SG_ 1423 M12_res_53 0;
BA_ "GenSigTimeoutTime_Gateway_PQ35_A" SG_ 1423 M12_res_54 5000;
BA_ "GenSigTimeoutMsg_Gateway_PQ35_A" SG_ 1423 M12_res_54 1423;
BA_ "GenSigTimeoutTime_Gateway_PQ46_A" SG_ 1423 M12_res_54 5000;
BA_ "GenSigTimeoutMsg_Gateway_PQ46_A" SG_ 1423 M12_res_54 1423;
BA_ "GenSigSendType" SG_ 1423 M12_res_54 0;
BA_ "GenSigTimeoutTime_Gateway_PQ35_A" SG_ 1423 M12_res_55 5000;
BA_ "GenSigTimeoutMsg_Gateway_PQ35_A" SG_ 1423 M12_res_55 1423;
BA_ "GenSigTimeoutTime_Gateway_PQ46_A" SG_ 1423 M12_res_55 5000;
BA_ "GenSigTimeoutMsg_Gateway_PQ46_A" SG_ 1423 M12_res_55 1423;
BA_ "GenSigSendType" SG_ 1423 M12_res_55 0;
BA_ "GenSigTimeoutTime_Gateway_PQ35_A" SG_ 1423 M12_res_56 5000;
BA_ "GenSigTimeoutMsg_Gateway_PQ35_A" SG_ 1423 M12_res_56 1423;
BA_ "GenSigTimeoutTime_Gateway_PQ46_A" SG_ 1423 M12_res_56 5000;
BA_ "GenSigTimeoutMsg_Gateway_PQ46_A" SG_ 1423 M12_res_56 1423;
BA_ "GenSigSendType" SG_ 1423 M12_res_56 0;
BA_ "GenSigTimeoutTime_Gateway_PQ35_A" SG_ 1423 M12_res_57 5000;
BA_ "GenSigTimeoutMsg_Gateway_PQ35_A" SG_ 1423 M12_res_57 1423;
BA_ "GenSigTimeoutTime_Gateway_PQ46_A" SG_ 1423 M12_res_57 5000;
BA_ "GenSigTimeoutMsg_Gateway_PQ46_A" SG_ 1423 M12_res_57 1423;
BA_ "GenSigSendType" SG_ 1423 M12_res_57 0;
BA_ "GenSigTimeoutTime_Gateway_PQ35_A" SG_ 1423 M12_res_58 5000;
BA_ "GenSigTimeoutMsg_Gateway_PQ35_A" SG_ 1423 M12_res_58 1423;
BA_ "GenSigTimeoutTime_Gateway_PQ46_A" SG_ 1423 M12_res_58 5000;
BA_ "GenSigTimeoutMsg_Gateway_PQ46_A" SG_ 1423 M12_res_58 1423;
BA_ "GenSigSendType" SG_ 1423 M12_res_58 0;
BA_ "GenSigTimeoutTime_Gateway_PQ35_A" SG_ 1423 M12_res_59 5000;
BA_ "GenSigTimeoutMsg_Gateway_PQ35_A" SG_ 1423 M12_res_59 1423;
BA_ "GenSigTimeoutTime_Gateway_PQ46_A" SG_ 1423 M12_res_59 5000;
BA_ "GenSigTimeoutMsg_Gateway_PQ46_A" SG_ 1423 M12_res_59 1423;
BA_ "GenSigSendType" SG_ 1423 M12_res_59 0;
BA_ "GenSigTimeoutTime_Gateway_PQ35_A" SG_ 1423 M12_res_60 5000;
BA_ "GenSigTimeoutMsg_Gateway_PQ35_A" SG_ 1423 M12_res_60 1423;
BA_ "GenSigTimeoutTime_Gateway_PQ46_A" SG_ 1423 M12_res_60 5000;
BA_ "GenSigTimeoutMsg_Gateway_PQ46_A" SG_ 1423 M12_res_60 1423;
BA_ "GenSigSendType" SG_ 1423 M12_res_60 0;
BA_ "GenSigTimeoutTime_Gateway_PQ35_A" SG_ 1423 M12_res_61 5000;
BA_ "GenSigTimeoutMsg_Gateway_PQ35_A" SG_ 1423 M12_res_61 1423;
BA_ "GenSigTimeoutTime_Gateway_PQ46_A" SG_ 1423 M12_res_61 5000;
BA_ "GenSigTimeoutMsg_Gateway_PQ46_A" SG_ 1423 M12_res_61 1423;
BA_ "GenSigSendType" SG_ 1423 M12_res_61 0;
BA_ "GenSigTimeoutTime_Gateway_PQ35_A" SG_ 1423 M12_res_62 5000;
BA_ "GenSigTimeoutMsg_Gateway_PQ35_A" SG_ 1423 M12_res_62 1423;
BA_ "GenSigTimeoutTime_Gateway_PQ46_A" SG_ 1423 M12_res_62 5000;
BA_ "GenSigTimeoutMsg_Gateway_PQ46_A" SG_ 1423 M12_res_62 1423;
BA_ "GenSigSendType" SG_ 1423 M12_res_62 0;
BA_ "GenSigTimeoutTime_Gateway_PQ35_A" SG_ 1423 M12_res_63 5000;
BA_ "GenSigTimeoutMsg_Gateway_PQ35_A" SG_ 1423 M12_res_63 1423;
BA_ "GenSigTimeoutTime_Gateway_PQ46_A" SG_ 1423 M12_res_63 5000;
BA_ "GenSigTimeoutMsg_Gateway_PQ46_A" SG_ 1423 M12_res_63 1423;
BA_ "GenSigSendType" SG_ 1423 M12_res_63 0;
BA_ "GenSigTimeoutTime_Gateway_PQ35_A" SG_ 1823 MSI_KD_Fehler 1000;
BA_ "GenSigTimeoutMsg_Gateway_PQ35_A" SG_ 1823 MSI_KD_Fehler 1823;
BA_ "GenSigSendType" SG_ 1823 MSI_KD_Fehler 0;
BA_ "GenSigSendType" SG_ 1823 MSI_res_02 0;
BA_ "GenSigSendType" SG_ 1823 MSI_res_03 0;
BA_ "GenSigSendType" SG_ 1823 MSI_res_04 0;
BA_ "GenSigSendType" SG_ 1823 MSI_res_05 0;
BA_ "GenSigSendType" SG_ 1823 MSI_res_06 0;
BA_ "GenSigSendType" SG_ 1823 MSI_res_01 0;
BA_ "GenSigSendType" SG_ 1823 MSI_res_07 0;
BA_ "GenSigTimeoutTime_Gateway_PQ46_A" SG_ 1800 MC1_Anz_Betrieb 2000;
BA_ "GenSigTimeoutMsg_Gateway_PQ46_A" SG_ 1800 MC1_Anz_Betrieb 1800;
BA_ "GenSigTimeoutTime_Gateway_PQ35_A" SG_ 1800 MC1_Anz_Betrieb 2000;
BA_ "GenSigTimeoutMsg_Gateway_PQ35_A" SG_ 1800 MC1_Anz_Betrieb 1800;
BA_ "GenSigSendType" SG_ 1800 MC1_Anz_Betrieb 0;
BA_ "GenSigTimeoutTime_Gateway_PQ46_A" SG_ 1800 MC1_Schalter 2000;
BA_ "GenSigTimeoutMsg_Gateway_PQ46_A" SG_ 1800 MC1_Schalter 1800;
BA_ "GenSigTimeoutTime_Gateway_PQ35_A" SG_ 1800 MC1_Schalter 2000;
BA_ "GenSigTimeoutMsg_Gateway_PQ35_A" SG_ 1800 MC1_Schalter 1800;
BA_ "GenSigSendType" SG_ 1800 MC1_Schalter 0;
BA_ "GenSigTimeoutTime_Gateway_PQ46_A" SG_ 1800 MC1_Fuellungsgrad 2000;
BA_ "GenSigTimeoutMsg_Gateway_PQ46_A" SG_ 1800 MC1_Fuellungsgrad 1800;
BA_ "GenSigTimeoutTime_Gateway_PQ35_A" SG_ 1800 MC1_Fuellungsgrad 2000;
BA_ "GenSigTimeoutMsg_Gateway_PQ35_A" SG_ 1800 MC1_Fuellungsgrad 1800;
BA_ "GenSigSendType" SG_ 1800 MC1_Fuellungsgrad 0;
BA_ "GenSigTimeoutTime_Gateway_PQ46_A" SG_ 1800 MC1_Verbrauch 2000;
BA_ "GenSigTimeoutMsg_Gateway_PQ46_A" SG_ 1800 MC1_Verbrauch 1800;
BA_ "GenSigTimeoutTime_Gateway_PQ35_A" SG_ 1800 MC1_Verbrauch 2000;
BA_ "GenSigTimeoutMsg_Gateway_PQ35_A" SG_ 1800 MC1_Verbrauch 1800;
BA_ "GenSigSendType" SG_ 1800 MC1_Verbrauch 0;
BA_ "GenSigTimeoutTime_Gateway_PQ46_A" SG_ 1800 MC1_akt_Betrieb 2000;
BA_ "GenSigTimeoutMsg_Gateway_PQ46_A" SG_ 1800 MC1_akt_Betrieb 1800;
BA_ "GenSigTimeoutTime_Gateway_PQ35_A" SG_ 1800 MC1_akt_Betrieb 2000;
BA_ "GenSigTimeoutMsg_Gateway_PQ35_A" SG_ 1800 MC1_akt_Betrieb 1800;
BA_ "GenSigSendType" SG_ 1800 MC1_akt_Betrieb 0;
BA_ "GenSigTimeoutTime_Gateway_PQ46_A" SG_ 1800 MC1_Ueb_Verbr 2000;
BA_ "GenSigTimeoutMsg_Gateway_PQ46_A" SG_ 1800 MC1_Ueb_Verbr 1800;
BA_ "GenSigTimeoutTime_Gateway_PQ35_A" SG_ 1800 MC1_Ueb_Verbr 2000;
BA_ "GenSigTimeoutMsg_Gateway_PQ35_A" SG_ 1800 MC1_Ueb_Verbr 1800;
BA_ "GenSigSendType" SG_ 1800 MC1_Ueb_Verbr 0;
BA_ "GenSigTimeoutTime_Gateway_PQ35_A" SG_ 1800 MC1_res_03 2000;
BA_ "GenSigTimeoutMsg_Gateway_PQ35_A" SG_ 1800 MC1_res_03 1800;
BA_ "GenSigTimeoutTime_Gateway_PQ46_A" SG_ 1800 MC1_res_03 2000;
BA_ "GenSigTimeoutMsg_Gateway_PQ46_A" SG_ 1800 MC1_res_03 1800;
BA_ "GenSigSendType" SG_ 1800 MC1_res_03 0;
BA_ "GenSigTimeoutTime_Gateway_PQ35_A" SG_ 1800 MC1_res_05 2000;
BA_ "GenSigTimeoutMsg_Gateway_PQ35_A" SG_ 1800 MC1_res_05 1800;
BA_ "GenSigTimeoutTime_Gateway_PQ46_A" SG_ 1800 MC1_res_05 2000;
BA_ "GenSigTimeoutMsg_Gateway_PQ46_A" SG_ 1800 MC1_res_05 1800;
BA_ "GenSigSendType" SG_ 1800 MC1_res_05 0;
BA_ "GenSigTimeoutTime_Gateway_PQ35_A" SG_ 1800 MC1_res_07 2000;
BA_ "GenSigTimeoutMsg_Gateway_PQ35_A" SG_ 1800 MC1_res_07 1800;
BA_ "GenSigTimeoutTime_Gateway_PQ46_A" SG_ 1800 MC1_res_07 2000;
BA_ "GenSigTimeoutMsg_Gateway_PQ46_A" SG_ 1800 MC1_res_07 1800;
BA_ "GenSigSendType" SG_ 1800 MC1_res_07 0;
BA_ "GenSigTimeoutTime_Gateway_PQ35_A" SG_ 1800 MC1_res_06 2000;
BA_ "GenSigTimeoutMsg_Gateway_PQ35_A" SG_ 1800 MC1_res_06 1800;
BA_ "GenSigTimeoutTime_Gateway_PQ46_A" SG_ 1800 MC1_res_06 2000;
BA_ "GenSigTimeoutMsg_Gateway_PQ46_A" SG_ 1800 MC1_res_06 1800;
BA_ "GenSigSendType" SG_ 1800 MC1_res_06 0;
BA_ "GenSigTimeoutTime_Gateway_PQ35_A" SG_ 1800 MC1_res_04 2000;
BA_ "GenSigTimeoutMsg_Gateway_PQ35_A" SG_ 1800 MC1_res_04 1800;
BA_ "GenSigTimeoutTime_Gateway_PQ46_A" SG_ 1800 MC1_res_04 2000;
BA_ "GenSigTimeoutMsg_Gateway_PQ46_A" SG_ 1800 MC1_res_04 1800;
BA_ "GenSigSendType" SG_ 1800 MC1_res_04 0;
BA_ "GenSigTimeoutMsg_Hybrid_DQ200" SG_ 1888 TPDyn_Getriebe_1 1888;
BA_ "GenSigTimeoutMsg_Selespeed" SG_ 1888 TPDyn_Getriebe_1 1888;
BA_ "GenSigTimeoutMsg_DQ" SG_ 1888 TPDyn_Getriebe_1 1888;
BA_ "GenSigTimeoutMsg_AG6" SG_ 1888 TPDyn_Getriebe_1 1888;
BA_ "GenSigTimeoutMsg_Airbag" SG_ 1897 TPDyn_Airbag_2 1897;
BA_ "GenSigTimeoutMsg_Lenkhilfe_APA" SG_ 1960 TPDyn_Lenkhilfe_1 1960;
BA_ "GenSigTimeoutMsg_Lenkhilfe_ZF_2" SG_ 1960 TPDyn_Lenkhilfe_1 1960;
BA_ "GenSigTimeoutMsg_Hybrid_DQ200" SG_ 1889 TPDyn_Getriebe_2 1889;
BA_ "GenSigTimeoutMsg_Selespeed" SG_ 1889 TPDyn_Getriebe_2 1889;
BA_ "GenSigTimeoutMsg_DQ" SG_ 1889 TPDyn_Getriebe_2 1889;
BA_ "GenSigTimeoutMsg_AG6" SG_ 1889 TPDyn_Getriebe_2 1889;
BA_ "GenSigTimeoutMsg_AFS" SG_ 1924 TPDyn_Dyn_LWR_1 1924;
BA_ "GenSigTimeoutMsg_LWR" SG_ 1924 TPDyn_Dyn_LWR_1 1924;
BA_ "GenSigTimeoutMsg_AFS" SG_ 1925 TPDyn_Dyn_LWR_2 1925;
BA_ "GenSigTimeoutMsg_LWR" SG_ 1925 TPDyn_Dyn_LWR_2 1925;
BA_ "GenSigTimeoutMsg_Lenkhilfe_APA" SG_ 1961 TPDyn_Lenkhilfe_2 1961;
BA_ "GenSigTimeoutMsg_Lenkhilfe_ZF_2" SG_ 1961 TPDyn_Lenkhilfe_2 1961;
BA_ "GenSigTimeoutMsg_Allrad" SG_ 1892 TPDyn_Allrad_1 1892;
BA_ "GenSigTimeoutMsg_Airbag" SG_ 1896 TPDyn_Airbag_1 1896;
BA_ "GenSigTimeoutMsg_TRW_ESP" SG_ 1936 TPDyn_ABS_1 1936;
BA_ "GenSigTimeoutMsg_Teves_MK70_MAB" SG_ 1936 TPDyn_ABS_1 1936;
BA_ "GenSigTimeoutMsg_Teves_MK60_ESP" SG_ 1936 TPDyn_ABS_1 1936;
BA_ "GenSigTimeoutTime_Otto" SG_ 800 KO1_Oeldruck 500;
BA_ "GenSigTimeoutMsg_Otto" SG_ 800 KO1_Oeldruck 800;
BA_ "GenSigTimeoutTime_Diesel" SG_ 800 KO1_Oeldruck 500;
BA_ "GenSigTimeoutMsg_Diesel" SG_ 800 KO1_Oeldruck 800;
BA_ "GenSigSendType" SG_ 800 KO1_Oeldruck 0;
BA_ "GenSigSendType" SG_ 800 KO1_SleepInd 0;
BA_ "GenSigTimeoutTime_Diesel" SG_ 800 KO1_Sta_Tank 500;
BA_ "GenSigTimeoutMsg_Diesel" SG_ 800 KO1_Sta_Tank 800;
BA_ "GenSigTimeoutTime_Hybrid_MSG" SG_ 800 KO1_Sta_Tank 500;
BA_ "GenSigTimeoutMsg_Hybrid_MSG" SG_ 800 KO1_Sta_Tank 800;
BA_ "GenSigTimeoutTime_Otto" SG_ 800 KO1_Sta_Tank 500;
BA_ "GenSigTimeoutMsg_Otto" SG_ 800 KO1_Sta_Tank 800;
BA_ "GenSigSendType" SG_ 800 KO1_Sta_Tank 0;
BA_ "GenSigSendType" SG_ 800 KO1_Kuehlmittel 0;
BA_ "GenSigSendType" SG_ 800 KO1_Sta_Oeldr 0;
BA_ "GenSigTimeoutTime_Diesel" SG_ 800 KO1_Warn_Tank 500;
BA_ "GenSigTimeoutMsg_Diesel" SG_ 800 KO1_Warn_Tank 800;
BA_ "GenSigSendType" SG_ 800 KO1_Warn_Tank 0;
BA_ "GenSigSendType" SG_ 800 KO1_La_Ladekon 0;
BA_ "GenSigTimeoutTime_Diesel" SG_ 800 KO1_Vorgluehen 500;
BA_ "GenSigTimeoutMsg_Diesel" SG_ 800 KO1_Vorgluehen 800;
BA_ "GenSigSendType" SG_ 800 KO1_Vorgluehen 0;
BA_ "GenSigSendType" SG_ 800 KO1_Wakeup_Komfort 0;
BA_ "GenSigTimeoutTime_Hybrid_MSG" SG_ 800 KO1_Tankinhalt 500;
BA_ "GenSigTimeoutMsg_Hybrid_MSG" SG_ 800 KO1_Tankinhalt 800;
BA_ "GenSigTimeoutTime_Otto" SG_ 800 KO1_Tankinhalt 500;
BA_ "GenSigTimeoutMsg_Otto" SG_ 800 KO1_Tankinhalt 800;
BA_ "GenSigTimeoutTime_Diesel" SG_ 800 KO1_Tankinhalt 500;
BA_ "GenSigTimeoutMsg_Diesel" SG_ 800 KO1_Tankinhalt 800;
BA_ "GenSigSendType" SG_ 800 KO1_Tankinhalt 0;
BA_ "GenSigTimeoutTime_ACC_Lidar" SG_ 800 KO1_Zeitluecke 500;
BA_ "GenSigTimeoutMsg_ACC_Lidar" SG_ 800 KO1_Zeitluecke 800;
BA_ "GenSigTimeoutTime_ACC_Radar" SG_ 800 KO1_Zeitluecke 500;
BA_ "GenSigTimeoutMsg_ACC_Radar" SG_ 800 KO1_Zeitluecke 800;
BA_ "GenSigSendType" SG_ 800 KO1_Zeitluecke 0;
BA_ "GenSigSendType" SG_ 800 KO1_Tankstop 0;
BA_ "GenSigTimeoutTime_Diesel" SG_ 800 KO1_OBD_Tank 500;
BA_ "GenSigTimeoutMsg_Diesel" SG_ 800 KO1_OBD_Tank 800;
BA_ "GenSigTimeoutTime_Hybrid_MSG" SG_ 800 KO1_OBD_Tank 500;
BA_ "GenSigTimeoutMsg_Hybrid_MSG" SG_ 800 KO1_OBD_Tank 800;
BA_ "GenSigTimeoutTime_Otto" SG_ 800 KO1_OBD_Tank 500;
BA_ "GenSigTimeoutMsg_Otto" SG_ 800 KO1_OBD_Tank 800;
BA_ "GenSigSendType" SG_ 800 KO1_OBD_Tank 0;
BA_ "GenSigTimeoutTime_Lenkhilfe_ZF_3" SG_ 800 KO1_kmh 500;
BA_ "GenSigTimeoutMsg_Lenkhilfe_ZF_3" SG_ 800 KO1_kmh 800;
BA_ "GenSigTimeoutTime_PDC_PLA" SG_ 800 KO1_kmh 500;
BA_ "GenSigTimeoutMsg_PDC_PLA" SG_ 800 KO1_kmh 800;
BA_ "GenSigTimeoutTime_LWR" SG_ 800 KO1_kmh 500;
BA_ "GenSigTimeoutMsg_LWR" SG_ 800 KO1_kmh 800;
BA_ "GenSigTimeoutTime_Lenkhilfe_ZF_2" SG_ 800 KO1_kmh 500;
BA_ "GenSigTimeoutMsg_Lenkhilfe_ZF_2" SG_ 800 KO1_kmh 800;
BA_ "GenSigSendType" SG_ 800 KO1_kmh 0;
BA_ "GenSigTimeoutTime_Otto" SG_ 800 KO1_Quelle_kmh 500;
BA_ "GenSigTimeoutMsg_Otto" SG_ 800 KO1_Quelle_kmh 800;
BA_ "GenSigSendType" SG_ 800 KO1_Quelle_kmh 0;
BA_ "INIT" SG_ 800 KO1_Quelle_kmh "const";
BA_ "GenSigTimeoutTime_ACC_Lidar" SG_ 800 KO1_ACC_Inkons 500;
BA_ "GenSigTimeoutMsg_ACC_Lidar" SG_ 800 KO1_ACC_Inkons 800;
BA_ "GenSigTimeoutTime_ACC_Radar" SG_ 800 KO1_ACC_Inkons 500;
BA_ "GenSigTimeoutMsg_ACC_Radar" SG_ 800 KO1_ACC_Inkons 800;
BA_ "GenSigSendType" SG_ 800 KO1_ACC_Inkons 0;
BA_ "GenSigTimeoutTime_ACC_Lidar" SG_ 800 KO1_Zaehler 500;
BA_ "GenSigTimeoutMsg_ACC_Lidar" SG_ 800 KO1_Zaehler 800;
BA_ "GenSigTimeoutTime_HCA" SG_ 800 KO1_Zaehler 500;
BA_ "GenSigTimeoutMsg_HCA" SG_ 800 KO1_Zaehler 800;
BA_ "GenSigTimeoutTime_ACC_Radar" SG_ 800 KO1_Zaehler 500;
BA_ "GenSigTimeoutMsg_ACC_Radar" SG_ 800 KO1_Zaehler 800;
BA_ "GenSigSendType" SG_ 800 KO1_Zaehler 0;
BA_ "GenSigTimeoutTime_Otto" SG_ 800 KO1_kmh_mph 500;
BA_ "GenSigTimeoutMsg_Otto" SG_ 800 KO1_kmh_mph 800;
BA_ "GenSigTimeoutTime_Diesel" SG_ 800 KO1_kmh_mph 500;
BA_ "GenSigTimeoutMsg_Diesel" SG_ 800 KO1_kmh_mph 800;
BA_ "GenSigTimeoutTime_ACC_Lidar" SG_ 800 KO1_kmh_mph 500;
BA_ "GenSigTimeoutMsg_ACC_Lidar" SG_ 800 KO1_kmh_mph 800;
BA_ "GenSigTimeoutTime_ACC_Radar" SG_ 800 KO1_kmh_mph 500;
BA_ "GenSigTimeoutMsg_ACC_Radar" SG_ 800 KO1_kmh_mph 800;
BA_ "GenSigSendType" SG_ 800 KO1_kmh_mph 0;
BA_ "INIT" SG_ 800 KO1_kmh_mph "alt/const";
BA_ "GenSigTimeoutTime_ACC_Lidar" SG_ 800 KO1_ACC_AnzFhl 500;
BA_ "GenSigTimeoutMsg_ACC_Lidar" SG_ 800 KO1_ACC_AnzFhl 800;
BA_ "GenSigTimeoutTime_ACC_Radar" SG_ 800 KO1_ACC_AnzFhl 500;
BA_ "GenSigTimeoutMsg_ACC_Radar" SG_ 800 KO1_ACC_AnzFhl 800;
BA_ "GenSigSendType" SG_ 800 KO1_ACC_AnzFhl 0;
BA_ "GenSigTimeoutTime_Otto" SG_ 800 KO1_angez_kmh 500;
BA_ "GenSigTimeoutMsg_Otto" SG_ 800 KO1_angez_kmh 800;
BA_ "GenSigTimeoutTime_Diesel" SG_ 800 KO1_angez_kmh 500;
BA_ "GenSigTimeoutMsg_Diesel" SG_ 800 KO1_angez_kmh 800;
BA_ "GenSigTimeoutTime_ACC_Lidar" SG_ 800 KO1_angez_kmh 500;
BA_ "GenSigTimeoutMsg_ACC_Lidar" SG_ 800 KO1_angez_kmh 800;
BA_ "GenSigTimeoutTime_HCA" SG_ 800 KO1_angez_kmh 500;
BA_ "GenSigTimeoutMsg_HCA" SG_ 800 KO1_angez_kmh 800;
BA_ "GenSigTimeoutTime_Hybrid_DQ200" SG_ 800 KO1_angez_kmh 500;
BA_ "GenSigTimeoutMsg_Hybrid_DQ200" SG_ 800 KO1_angez_kmh 800;
BA_ "GenSigTimeoutTime_RKA_Plus" SG_ 800 KO1_angez_kmh 500;
BA_ "GenSigTimeoutMsg_RKA_Plus" SG_ 800 KO1_angez_kmh 800;
BA_ "GenSigTimeoutTime_ACC_Radar" SG_ 800 KO1_angez_kmh 500;
BA_ "GenSigTimeoutMsg_ACC_Radar" SG_ 800 KO1_angez_kmh 800;
BA_ "GenSigTimeoutTime_DQ" SG_ 800 KO1_angez_kmh 500;
BA_ "GenSigTimeoutMsg_DQ" SG_ 800 KO1_angez_kmh 800;
BA_ "GenSigSendType" SG_ 800 KO1_angez_kmh 0;
BA_ "GenSigSendType" SG_ 800 KO1_Bremsinfo 0;
BA_ "GenSigTimeoutTime_Lenkhilfe_ZF_3" SG_ 800 KO1_Stellglieder 500;
BA_ "GenSigTimeoutMsg_Lenkhilfe_ZF_3" SG_ 800 KO1_Stellglieder 800;
BA_ "GenSigTimeoutTime_Lenkhilfe_ZF_2" SG_ 800 KO1_Stellglieder 500;
BA_ "GenSigTimeoutMsg_Lenkhilfe_ZF_2" SG_ 800 KO1_Stellglieder 800;
BA_ "GenSigTimeoutTime_Airbag" SG_ 800 KO1_Stellglieder 500;
BA_ "GenSigTimeoutMsg_Airbag" SG_ 800 KO1_Stellglieder 800;
BA_ "GenSigTimeoutTime_Diesel" SG_ 800 KO1_Stellglieder 500;
BA_ "GenSigTimeoutMsg_Diesel" SG_ 800 KO1_Stellglieder 800;
BA_ "GenSigSendType" SG_ 800 KO1_Stellglieder 0;
BA_ "GenSigSendType" SG_ 800 KO1_ABS_Lampe 0;
BA_ "GenSigTimeoutTime_HCA" SG_ 800 KO1_LDW_AnzFeh 500;
BA_ "GenSigTimeoutMsg_HCA" SG_ 800 KO1_LDW_AnzFeh 800;
BA_ "GenSigSendType" SG_ 800 KO1_LDW_AnzFeh 0;
BA_ "GenSigTimeoutTime_Airbag" SG_ 800 KO1_Airbag_Lampe 500;
BA_ "GenSigTimeoutMsg_Airbag" SG_ 800 KO1_Airbag_Lampe 800;
BA_ "GenSigSendType" SG_ 800 KO1_Airbag_Lampe 0;
BA_ "GenSigSendType" SG_ 800 KO1_ASRESP_Lampe 0;
BA_ "GenSigTimeoutTime_Lenkhilfe_ZF_3" SG_ 800 KO1_Lenkh_Lampe 500;
BA_ "GenSigTimeoutMsg_Lenkhilfe_ZF_3" SG_ 800 KO1_Lenkh_Lampe 800;
BA_ "GenSigTimeoutTime_Lenkhilfe_APA" SG_ 800 KO1_Lenkh_Lampe 500;
BA_ "GenSigTimeoutMsg_Lenkhilfe_APA" SG_ 800 KO1_Lenkh_Lampe 800;
BA_ "GenSigTimeoutTime_Lenkhilfe_ZF_2" SG_ 800 KO1_Lenkh_Lampe 500;
BA_ "GenSigTimeoutMsg_Lenkhilfe_ZF_2" SG_ 800 KO1_Lenkh_Lampe 800;
BA_ "GenSigSendType" SG_ 800 KO1_Lenkh_Lampe 0;
BA_ "GenSigTimeoutTime_Lenkhilfe_ZF_3" SG_ 800 KO1_SILA_gueltig 500;
BA_ "GenSigTimeoutMsg_Lenkhilfe_ZF_3" SG_ 800 KO1_SILA_gueltig 800;
BA_ "GenSigTimeoutTime_Lenkhilfe_APA" SG_ 800 KO1_SILA_gueltig 500;
BA_ "GenSigTimeoutMsg_Lenkhilfe_APA" SG_ 800 KO1_SILA_gueltig 800;
BA_ "GenSigTimeoutTime_Lenkhilfe_ZF_2" SG_ 800 KO1_SILA_gueltig 500;
BA_ "GenSigTimeoutMsg_Lenkhilfe_ZF_2" SG_ 800 KO1_SILA_gueltig 800;
BA_ "GenSigTimeoutTime_Airbag" SG_ 800 KO1_SILA_gueltig 500;
BA_ "GenSigTimeoutMsg_Airbag" SG_ 800 KO1_SILA_gueltig 800;
BA_ "GenSigSendType" SG_ 800 KO1_SILA_gueltig 0;
BA_ "GenSigTimeoutTime_Lenkhilfe_ZF_3" SG_ 800 KO1_Handbremse 500;
BA_ "GenSigTimeoutMsg_Lenkhilfe_ZF_3" SG_ 800 KO1_Handbremse 800;
BA_ "GenSigTimeoutTime_Lenkhilfe_ZF_2" SG_ 800 KO1_Handbremse 500;
BA_ "GenSigTimeoutMsg_Lenkhilfe_ZF_2" SG_ 800 KO1_Handbremse 800;
BA_ "GenSigTimeoutTime_Teves_MK70_MAB" SG_ 800 KO1_Handbremse 500;
BA_ "GenSigTimeoutMsg_Teves_MK70_MAB" SG_ 800 KO1_Handbremse 800;
BA_ "GenSigTimeoutTime_Teves_MK60_ESP" SG_ 800 KO1_Handbremse 500;
BA_ "GenSigTimeoutMsg_Teves_MK60_ESP" SG_ 800 KO1_Handbremse 800;
BA_ "GenSigTimeoutTime_Lenkhilfe_APA" SG_ 800 KO1_Handbremse 500;
BA_ "GenSigTimeoutMsg_Lenkhilfe_APA" SG_ 800 KO1_Handbremse 800;
BA_ "GenSigTimeoutTime_Allrad" SG_ 800 KO1_Handbremse 500;
BA_ "GenSigTimeoutMsg_Allrad" SG_ 800 KO1_Handbremse 800;
BA_ "GenSigTimeoutTime_Selespeed" SG_ 800 KO1_Handbremse 500;
BA_ "GenSigTimeoutMsg_Selespeed" SG_ 800 KO1_Handbremse 800;
BA_ "GenSigTimeoutTime_Hybrid_DQ200" SG_ 800 KO1_Handbremse 500;
BA_ "GenSigTimeoutMsg_Hybrid_DQ200" SG_ 800 KO1_Handbremse 800;
BA_ "GenSigTimeoutTime_RKA_Plus" SG_ 800 KO1_Handbremse 500;
BA_ "GenSigTimeoutMsg_RKA_Plus" SG_ 800 KO1_Handbremse 800;
BA_ "GenSigTimeoutTime_DQ" SG_ 800 KO1_Handbremse 500;
BA_ "GenSigTimeoutMsg_DQ" SG_ 800 KO1_Handbremse 800;
BA_ "GenSigSendType" SG_ 800 KO1_Handbremse 0;
BA_ "GenSigSendType" SG_ 800 KO1_Brems_Lampe 0;
BA_ "GenSigTimeoutTime_Hybrid_MSG" SG_ 1306 TOG_Fuellstand_1 5000;
BA_ "GenSigTimeoutMsg_Hybrid_MSG" SG_ 1306 TOG_Fuellstand_1 1306;
BA_ "GenSigTimeoutTime_Otto" SG_ 1306 TOG_Fuellstand_1 5000;
BA_ "GenSigTimeoutMsg_Otto" SG_ 1306 TOG_Fuellstand_1 1306;
BA_ "GenSigTimeoutTime_Diesel" SG_ 1306 TOG_Fuellstand_1 5000;
BA_ "GenSigTimeoutMsg_Diesel" SG_ 1306 TOG_Fuellstand_1 1306;
BA_ "GenSigSendType" SG_ 1306 TOG_Fuellstand_1 0;
BA_ "GenSigStartValue" SG_ 1306 TOG_Fuellstand_1 1;
BA_ "GenSigTimeoutTime_Hybrid_MSG" SG_ 1306 TOG_Sensorfehler 5000;
BA_ "GenSigTimeoutMsg_Hybrid_MSG" SG_ 1306 TOG_Sensorfehler 1306;
BA_ "GenSigTimeoutTime_Otto" SG_ 1306 TOG_Sensorfehler 5000;
BA_ "GenSigTimeoutMsg_Otto" SG_ 1306 TOG_Sensorfehler 1306;
BA_ "GenSigTimeoutTime_Diesel" SG_ 1306 TOG_Sensorfehler 5000;
BA_ "GenSigTimeoutMsg_Diesel" SG_ 1306 TOG_Sensorfehler 1306;
BA_ "GenSigSendType" SG_ 1306 TOG_Sensorfehler 0;
BA_ "GenSigSendType" SG_ 1306 TOG_OelwarnUeber 0;
BA_ "GenSigTimeoutTime_Hybrid_MSG" SG_ 1306 TOG_Oelwarn_hoch 5000;
BA_ "GenSigTimeoutMsg_Hybrid_MSG" SG_ 1306 TOG_Oelwarn_hoch 1306;
BA_ "GenSigTimeoutTime_Otto" SG_ 1306 TOG_Oelwarn_hoch 5000;
BA_ "GenSigTimeoutMsg_Otto" SG_ 1306 TOG_Oelwarn_hoch 1306;
BA_ "GenSigTimeoutTime_Diesel" SG_ 1306 TOG_Oelwarn_hoch 5000;
BA_ "GenSigTimeoutMsg_Diesel" SG_ 1306 TOG_Oelwarn_hoch 1306;
BA_ "GenSigSendType" SG_ 1306 TOG_Oelwarn_hoch 0;
BA_ "GenSigSendType" SG_ 1306 TOG_Reserve1 0;
BA_ "GenSigTimeoutTime_Hybrid_MSG" SG_ 1306 TOG_Oeltempzeit 5000;
BA_ "GenSigTimeoutMsg_Hybrid_MSG" SG_ 1306 TOG_Oeltempzeit 1306;
BA_ "GenSigTimeoutTime_Otto" SG_ 1306 TOG_Oeltempzeit 5000;
BA_ "GenSigTimeoutMsg_Otto" SG_ 1306 TOG_Oeltempzeit 1306;
BA_ "GenSigTimeoutTime_Diesel" SG_ 1306 TOG_Oeltempzeit 5000;
BA_ "GenSigTimeoutMsg_Diesel" SG_ 1306 TOG_Oeltempzeit 1306;
BA_ "GenSigSendType" SG_ 1306 TOG_Oeltempzeit 0;
BA_ "GenSigStartValue" SG_ 1306 TOG_Oeltempzeit 1;
BA_ "GenSigTimeoutTime_Hybrid_MSG" SG_ 1306 TOG_Fuellstand_4 5000;
BA_ "GenSigTimeoutMsg_Hybrid_MSG" SG_ 1306 TOG_Fuellstand_4 1306;
BA_ "GenSigTimeoutTime_Otto" SG_ 1306 TOG_Fuellstand_4 5000;
BA_ "GenSigTimeoutMsg_Otto" SG_ 1306 TOG_Fuellstand_4 1306;
BA_ "GenSigTimeoutTime_Diesel" SG_ 1306 TOG_Fuellstand_4 5000;
BA_ "GenSigTimeoutMsg_Diesel" SG_ 1306 TOG_Fuellstand_4 1306;
BA_ "GenSigSendType" SG_ 1306 TOG_Fuellstand_4 0;
BA_ "GenSigStartValue" SG_ 1306 TOG_Fuellstand_4 1;
BA_ "GenSigTimeoutTime_Hybrid_MSG" SG_ 1306 TOG_Fuellstand_3 5000;
BA_ "GenSigTimeoutMsg_Hybrid_MSG" SG_ 1306 TOG_Fuellstand_3 1306;
BA_ "GenSigTimeoutTime_Otto" SG_ 1306 TOG_Fuellstand_3 5000;
BA_ "GenSigTimeoutMsg_Otto" SG_ 1306 TOG_Fuellstand_3 1306;
BA_ "GenSigTimeoutTime_Diesel" SG_ 1306 TOG_Fuellstand_3 5000;
BA_ "GenSigTimeoutMsg_Diesel" SG_ 1306 TOG_Fuellstand_3 1306;
BA_ "GenSigSendType" SG_ 1306 TOG_Fuellstand_3 0;
BA_ "GenSigStartValue" SG_ 1306 TOG_Fuellstand_3 1;
BA_ "GenSigTimeoutTime_Hybrid_MSG" SG_ 1306 TOG_Zaehler 5000;
BA_ "GenSigTimeoutMsg_Hybrid_MSG" SG_ 1306 TOG_Zaehler 1306;
BA_ "GenSigTimeoutTime_Otto" SG_ 1306 TOG_Zaehler 5000;
BA_ "GenSigTimeoutMsg_Otto" SG_ 1306 TOG_Zaehler 1306;
BA_ "GenSigTimeoutTime_Diesel" SG_ 1306 TOG_Zaehler 5000;
BA_ "GenSigTimeoutMsg_Diesel" SG_ 1306 TOG_Zaehler 1306;
BA_ "GenSigSendType" SG_ 1306 TOG_Zaehler 0;
BA_ "GenSigSendType" SG_ 1306 TOG_OelmaxUeber 0;
BA_ "GenSigTimeoutTime_Hybrid_MSG" SG_ 1306 TOG_Fuellstand_2 5000;
BA_ "GenSigTimeoutMsg_Hybrid_MSG" SG_ 1306 TOG_Fuellstand_2 1306;
BA_ "GenSigTimeoutTime_Otto" SG_ 1306 TOG_Fuellstand_2 5000;
BA_ "GenSigTimeoutMsg_Otto" SG_ 1306 TOG_Fuellstand_2 1306;
BA_ "GenSigTimeoutTime_Diesel" SG_ 1306 TOG_Fuellstand_2 5000;
BA_ "GenSigTimeoutMsg_Diesel" SG_ 1306 TOG_Fuellstand_2 1306;
BA_ "GenSigSendType" SG_ 1306 TOG_Fuellstand_2 0;
BA_ "GenSigStartValue" SG_ 1306 TOG_Fuellstand_2 1;
BA_ "GenSigSendType" SG_ 1306 TOG_Oelmax_hoch 0;
BA_ "GenSigTimeoutTime_TRW_ESP" SG_ 1312 KO3_Sprache 2000;
BA_ "GenSigTimeoutMsg_TRW_ESP" SG_ 1312 KO3_Sprache 1312;
BA_ "GenSigSendType" SG_ 1312 KO3_Sprache 0;
BA_ "INIT" SG_ 1312 KO3_Sprache "alt/const";
BA_ "GenSigTimeoutTime_Allrad" SG_ 1312 KO3_Mp_Code 2000;
BA_ "GenSigTimeoutMsg_Allrad" SG_ 1312 KO3_Mp_Code 1312;
BA_ "GenSigTimeoutTime_SWA" SG_ 1312 KO3_Mp_Code 2000;
BA_ "GenSigTimeoutMsg_SWA" SG_ 1312 KO3_Mp_Code 1312;
BA_ "GenSigTimeoutTime_PDC_PLA" SG_ 1312 KO3_Mp_Code 2000;
BA_ "GenSigTimeoutMsg_PDC_PLA" SG_ 1312 KO3_Mp_Code 1312;
BA_ "GenSigTimeoutTime_TRW_ESP" SG_ 1312 KO3_Mp_Code 2000;
BA_ "GenSigTimeoutMsg_TRW_ESP" SG_ 1312 KO3_Mp_Code 1312;
BA_ "GenSigTimeoutTime_Teves_MK70_MAB" SG_ 1312 KO3_Mp_Code 2000;
BA_ "GenSigTimeoutMsg_Teves_MK70_MAB" SG_ 1312 KO3_Mp_Code 1312;
BA_ "GenSigTimeoutTime_Teves_MK60_ESP" SG_ 1312 KO3_Mp_Code 2000;
BA_ "GenSigTimeoutMsg_Teves_MK60_ESP" SG_ 1312 KO3_Mp_Code 1312;
BA_ "GenSigTimeoutTime_Airbag" SG_ 1312 KO3_Mp_Code 2000;
BA_ "GenSigTimeoutMsg_Airbag" SG_ 1312 KO3_Mp_Code 1312;
BA_ "GenSigSendType" SG_ 1312 KO3_Mp_Code 0;
BA_ "GenSigSendType" SG_ 1312 KO3_Schluessel 0;
BA_ "GenSigTimeoutTime_Teves_MK60_ESP" SG_ 1312 KO3_Standzeit 2000;
BA_ "GenSigTimeoutMsg_Teves_MK60_ESP" SG_ 1312 KO3_Standzeit 1312;
BA_ "GenSigTimeoutTime_Allrad" SG_ 1312 KO3_Standzeit 2000;
BA_ "GenSigTimeoutMsg_Allrad" SG_ 1312 KO3_Standzeit 1312;
BA_ "GenSigTimeoutTime_Diesel" SG_ 1312 KO3_Standzeit 2000;
BA_ "GenSigTimeoutMsg_Diesel" SG_ 1312 KO3_Standzeit 1312;
BA_ "GenSigTimeoutTime_Hybrid_MSG" SG_ 1312 KO3_Standzeit 2000;
BA_ "GenSigTimeoutMsg_Hybrid_MSG" SG_ 1312 KO3_Standzeit 1312;
BA_ "GenSigTimeoutTime_Magne_Ride" SG_ 1312 KO3_Standzeit 2000;
BA_ "GenSigTimeoutMsg_Magne_Ride" SG_ 1312 KO3_Standzeit 1312;
BA_ "GenSigTimeoutTime_AFS" SG_ 1312 KO3_Standzeit 2000;
BA_ "GenSigTimeoutMsg_AFS" SG_ 1312 KO3_Standzeit 1312;
BA_ "GenSigTimeoutTime_TRW_ESP" SG_ 1312 KO3_Standzeit 2000;
BA_ "GenSigTimeoutMsg_TRW_ESP" SG_ 1312 KO3_Standzeit 1312;
BA_ "GenSigTimeoutTime_Otto" SG_ 1312 KO3_Standzeit 2000;
BA_ "GenSigTimeoutMsg_Otto" SG_ 1312 KO3_Standzeit 1312;
BA_ "GenSigSendType" SG_ 1312 KO3_Standzeit 0;
BA_ "GenSigTimeoutTime_Teves_MK60_ESP" SG_ 1312 KO3_Sta_Standz 2000;
BA_ "GenSigTimeoutMsg_Teves_MK60_ESP" SG_ 1312 KO3_Sta_Standz 1312;
BA_ "GenSigTimeoutTime_Otto" SG_ 1312 KO3_Sta_Standz 2000;
BA_ "GenSigTimeoutMsg_Otto" SG_ 1312 KO3_Sta_Standz 1312;
BA_ "GenSigTimeoutTime_Diesel" SG_ 1312 KO3_Sta_Standz 2000;
BA_ "GenSigTimeoutMsg_Diesel" SG_ 1312 KO3_Sta_Standz 1312;
BA_ "GenSigTimeoutTime_Magne_Ride" SG_ 1312 KO3_Sta_Standz 2000;
BA_ "GenSigTimeoutMsg_Magne_Ride" SG_ 1312 KO3_Sta_Standz 1312;
BA_ "GenSigTimeoutTime_AFS" SG_ 1312 KO3_Sta_Standz 2000;
BA_ "GenSigTimeoutMsg_AFS" SG_ 1312 KO3_Sta_Standz 1312;
BA_ "GenSigSendType" SG_ 1312 KO3_Sta_Standz 0;
BA_ "GenSigTimeoutTime_Lenkhilfe_ZF_3" SG_ 1312 KO3_Kilometer 2000;
BA_ "GenSigTimeoutMsg_Lenkhilfe_ZF_3" SG_ 1312 KO3_Kilometer 1312;
BA_ "GenSigTimeoutTime_Teves_MK70_MAB" SG_ 1312 KO3_Kilometer 2000;
BA_ "GenSigTimeoutMsg_Teves_MK70_MAB" SG_ 1312 KO3_Kilometer 1312;
BA_ "GenSigTimeoutTime_Teves_MK60_ESP" SG_ 1312 KO3_Kilometer 2000;
BA_ "GenSigTimeoutMsg_Teves_MK60_ESP" SG_ 1312 KO3_Kilometer 1312;
BA_ "GenSigTimeoutTime_Lenkhilfe_ZF_2" SG_ 1312 KO3_Kilometer 2000;
BA_ "GenSigTimeoutMsg_Lenkhilfe_ZF_2" SG_ 1312 KO3_Kilometer 1312;
BA_ "GenSigTimeoutTime_AG6" SG_ 1312 KO3_Kilometer 2000;
BA_ "GenSigTimeoutMsg_AG6" SG_ 1312 KO3_Kilometer 1312;
BA_ "GenSigSendType" SG_ 1312 KO3_Kilometer 0;
BA_ "GenSigTimeoutTime_AFS" SG_ 1312 KO3_Um_AFS2 2000;
BA_ "GenSigTimeoutMsg_AFS" SG_ 1312 KO3_Um_AFS2 1312;
BA_ "GenSigSendType" SG_ 1312 KO3_Um_AFS2 0;
BA_ "GenSigSendType" SG_ 1312 KO3_Reserve2 0;
BA_ "GenSigSendType" SG_ 1312 KO3_Land 0;
BA_ "INIT" SG_ 1312 KO3_Land "const";
BA_ "GenSigTimeoutTime_Allrad" SG_ 1312 KO3_Baureihe 2000;
BA_ "GenSigTimeoutMsg_Allrad" SG_ 1312 KO3_Baureihe 1312;
BA_ "GenSigTimeoutTime_Teves_MK60_ESP" SG_ 1312 KO3_Baureihe 2000;
BA_ "GenSigTimeoutMsg_Teves_MK60_ESP" SG_ 1312 KO3_Baureihe 1312;
BA_ "GenSigSendType" SG_ 1312 KO3_Baureihe 0;
BA_ "INIT" SG_ 1312 KO3_Baureihe "const";
BA_ "GenSigTimeoutTime_Allrad" SG_ 1312 KO3_Radumfang 2000;
BA_ "GenSigTimeoutMsg_Allrad" SG_ 1312 KO3_Radumfang 1312;
BA_ "GenSigTimeoutTime_SWA" SG_ 1312 KO3_Radumfang 2000;
BA_ "GenSigTimeoutMsg_SWA" SG_ 1312 KO3_Radumfang 1312;
BA_ "GenSigTimeoutTime_PDC_PLA" SG_ 1312 KO3_Radumfang 2000;
BA_ "GenSigTimeoutMsg_PDC_PLA" SG_ 1312 KO3_Radumfang 1312;
BA_ "GenSigTimeoutTime_TRW_ESP" SG_ 1312 KO3_Radumfang 2000;
BA_ "GenSigTimeoutMsg_TRW_ESP" SG_ 1312 KO3_Radumfang 1312;
BA_ "GenSigTimeoutTime_Teves_MK70_MAB" SG_ 1312 KO3_Radumfang 2000;
BA_ "GenSigTimeoutMsg_Teves_MK70_MAB" SG_ 1312 KO3_Radumfang 1312;
BA_ "GenSigTimeoutTime_Teves_MK60_ESP" SG_ 1312 KO3_Radumfang 2000;
BA_ "GenSigTimeoutMsg_Teves_MK60_ESP" SG_ 1312 KO3_Radumfang 1312;
BA_ "GenSigSendType" SG_ 1312 KO3_Radumfang 0;
BA_ "INIT" SG_ 1312 KO3_Radumfang "const";
BA_ "GenSigTimeoutTime_Allrad" SG_ 1312 KO3_Derivat 2000;
BA_ "GenSigTimeoutMsg_Allrad" SG_ 1312 KO3_Derivat 1312;
BA_ "GenSigTimeoutTime_Teves_MK60_ESP" SG_ 1312 KO3_Derivat 2000;
BA_ "GenSigTimeoutMsg_Teves_MK60_ESP" SG_ 1312 KO3_Derivat 1312;
BA_ "GenSigSendType" SG_ 1312 KO3_Derivat 0;
BA_ "INIT" SG_ 1312 KO3_Derivat "const";
BA_ "GenSigTimeoutTime_Allrad" SG_ 1312 KO3_Generation 2000;
BA_ "GenSigTimeoutMsg_Allrad" SG_ 1312 KO3_Generation 1312;
BA_ "GenSigTimeoutTime_Teves_MK60_ESP" SG_ 1312 KO3_Generation 2000;
BA_ "GenSigTimeoutMsg_Teves_MK60_ESP" SG_ 1312 KO3_Generation 1312;
BA_ "GenSigSendType" SG_ 1312 KO3_Generation 0;
BA_ "INIT" SG_ 1312 KO3_Generation "const";
BA_ "GenSigTimeoutTime_Allrad" SG_ 1312 KO3_Marke 2000;
BA_ "GenSigTimeoutMsg_Allrad" SG_ 1312 KO3_Marke 1312;
BA_ "GenSigTimeoutTime_Teves_MK60_ESP" SG_ 1312 KO3_Marke 2000;
BA_ "GenSigTimeoutMsg_Teves_MK60_ESP" SG_ 1312 KO3_Marke 1312;
BA_ "GenSigSendType" SG_ 1312 KO3_Marke 0;
BA_ "INIT" SG_ 1312 KO3_Marke "const";
BA_ "GenSigSendType" SG_ 1312 KO3_Verbau_BN 0;
BA_ "INIT" SG_ 1312 KO3_Verbau_BN "const";
BA_ "GenSigSendType" SG_ 1312 KO3_Verbau_ADR 0;
BA_ "INIT" SG_ 1312 KO3_Verbau_ADR "const";
BA_ "GenSigTimeoutTime_Airbag" SG_ 1312 KO3_Verbau_Air 2000;
BA_ "GenSigTimeoutMsg_Airbag" SG_ 1312 KO3_Verbau_Air 1312;
BA_ "GenSigSendType" SG_ 1312 KO3_Verbau_Air 0;
BA_ "INIT" SG_ 1312 KO3_Verbau_Air "const";
BA_ "GenSigSendType" SG_ 1312 KO3_Verbau_DP 0;
BA_ "INIT" SG_ 1312 KO3_Verbau_DP "const";
BA_ "GenSigSendType" SG_ 1312 KO3_Verbau_Get 0;
BA_ "INIT" SG_ 1312 KO3_Verbau_Get "const";
BA_ "GenSigSendType" SG_ 1312 KO3_Verbau_Kl 0;
BA_ "INIT" SG_ 1312 KO3_Verbau_Kl "const";
BA_ "GenSigSendType" SG_ 1312 KO3_Verbau_LH 0;
BA_ "INIT" SG_ 1312 KO3_Verbau_LH "const";
BA_ "GenSigTimeoutTime_Teves_MK60_ESP" SG_ 1312 KO3_Verbau_Br 2000;
BA_ "GenSigTimeoutMsg_Teves_MK60_ESP" SG_ 1312 KO3_Verbau_Br 1312;
BA_ "GenSigSendType" SG_ 1312 KO3_Verbau_Br 0;
BA_ "INIT" SG_ 1312 KO3_Verbau_Br "const";
BA_ "GenSigSendType" SG_ 1312 KO3_Verbau_Niveau 0;
BA_ "INIT" SG_ 1312 KO3_Verbau_Niveau "const";
BA_ "GenSigSendType" SG_ 1312 KO3_Verbau_Mot 0;
BA_ "INIT" SG_ 1312 KO3_Verbau_Mot "const";
BA_ "GenSigTimeoutTime_SWA" SG_ 1312 KO3_SWA_AnzFeh 2000;
BA_ "GenSigTimeoutMsg_SWA" SG_ 1312 KO3_SWA_AnzFeh 1312;
BA_ "GenSigSendType" SG_ 1312 KO3_SWA_AnzFeh 0;
BA_ "GenSigSendType" SG_ 1312 KO3_Verbau_LWS 0;
BA_ "INIT" SG_ 1312 KO3_Verbau_LWS "const";
BA_ "GenSigTimeoutTime_TRW_ESP" SG_ 1312 KO3_Um_AutoHold 2000;
BA_ "GenSigTimeoutMsg_TRW_ESP" SG_ 1312 KO3_Um_AutoHold 1312;
BA_ "GenSigSendType" SG_ 1312 KO3_Um_AutoHold 0;
BA_ "GenSigSendType" SG_ 1312 KO3_Verbau_Syn 0;
BA_ "INIT" SG_ 1312 KO3_Verbau_Syn "const";
BA_ "GenSigTimeoutTime_AFS" SG_ 1312 KO3_Um_Tourist 2000;
BA_ "GenSigTimeoutMsg_AFS" SG_ 1312 KO3_Um_Tourist 1312;
BA_ "GenSigSendType" SG_ 1312 KO3_Um_Tourist 0;
BA_ "GenSigTimeoutTime_Teves_MK70_MAB" SG_ 1056 KO2_Sta_Auss_T 2000;
BA_ "GenSigTimeoutMsg_Teves_MK70_MAB" SG_ 1056 KO2_Sta_Auss_T 1056;
BA_ "GenSigTimeoutTime_Teves_MK60_ESP" SG_ 1056 KO2_Sta_Auss_T 2000;
BA_ "GenSigTimeoutMsg_Teves_MK60_ESP" SG_ 1056 KO2_Sta_Auss_T 1056;
BA_ "GenSigTimeoutTime_HCA" SG_ 1056 KO2_Sta_Auss_T 2000;
BA_ "GenSigTimeoutMsg_HCA" SG_ 1056 KO2_Sta_Auss_T 1056;
BA_ "GenSigTimeoutTime_Hybrid_MSG" SG_ 1056 KO2_Sta_Auss_T 2000;
BA_ "GenSigTimeoutMsg_Hybrid_MSG" SG_ 1056 KO2_Sta_Auss_T 1056;
BA_ "GenSigTimeoutTime_RKA_Plus" SG_ 1056 KO2_Sta_Auss_T 2000;
BA_ "GenSigTimeoutMsg_RKA_Plus" SG_ 1056 KO2_Sta_Auss_T 1056;
BA_ "GenSigTimeoutTime_Magne_Ride" SG_ 1056 KO2_Sta_Auss_T 2000;
BA_ "GenSigTimeoutMsg_Magne_Ride" SG_ 1056 KO2_Sta_Auss_T 1056;
BA_ "GenSigTimeoutTime_Otto" SG_ 1056 KO2_Sta_Auss_T 2000;
BA_ "GenSigTimeoutMsg_Otto" SG_ 1056 KO2_Sta_Auss_T 1056;
BA_ "GenSigTimeoutTime_Diesel" SG_ 1056 KO2_Sta_Auss_T 2000;
BA_ "GenSigTimeoutMsg_Diesel" SG_ 1056 KO2_Sta_Auss_T 1056;
BA_ "GenSigSendType" SG_ 1056 KO2_Sta_Auss_T 0;
BA_ "INIT" SG_ 1056 KO2_Sta_Auss_T "0/1";
BA_ "GenSigSendType" SG_ 1056 KO2_Temp_Einheit 0;
BA_ "INIT" SG_ 1056 KO2_Temp_Einheit "alt/const";
BA_ "GenSigTimeoutTime_Selespeed" SG_ 1056 KO2_gef_Auss_T 2000;
BA_ "GenSigTimeoutMsg_Selespeed" SG_ 1056 KO2_gef_Auss_T 1056;
BA_ "GenSigTimeoutTime_HCA" SG_ 1056 KO2_gef_Auss_T 2000;
BA_ "GenSigTimeoutMsg_HCA" SG_ 1056 KO2_gef_Auss_T 1056;
BA_ "GenSigTimeoutTime_Hybrid_DQ200" SG_ 1056 KO2_gef_Auss_T 2000;
BA_ "GenSigTimeoutMsg_Hybrid_DQ200" SG_ 1056 KO2_gef_Auss_T 1056;
BA_ "GenSigTimeoutTime_Hybrid_MSG" SG_ 1056 KO2_gef_Auss_T 2000;
BA_ "GenSigTimeoutMsg_Hybrid_MSG" SG_ 1056 KO2_gef_Auss_T 1056;
BA_ "GenSigTimeoutTime_PDC_PLA" SG_ 1056 KO2_gef_Auss_T 2000;
BA_ "GenSigTimeoutMsg_PDC_PLA" SG_ 1056 KO2_gef_Auss_T 1056;
BA_ "GenSigTimeoutTime_RKA_Plus" SG_ 1056 KO2_gef_Auss_T 2000;
BA_ "GenSigTimeoutMsg_RKA_Plus" SG_ 1056 KO2_gef_Auss_T 1056;
BA_ "GenSigTimeoutTime_Magne_Ride" SG_ 1056 KO2_gef_Auss_T 2000;
BA_ "GenSigTimeoutMsg_Magne_Ride" SG_ 1056 KO2_gef_Auss_T 1056;
BA_ "GenSigTimeoutTime_TRW_ESP" SG_ 1056 KO2_gef_Auss_T 2000;
BA_ "GenSigTimeoutMsg_TRW_ESP" SG_ 1056 KO2_gef_Auss_T 1056;
BA_ "GenSigTimeoutTime_DQ" SG_ 1056 KO2_gef_Auss_T 2000;
BA_ "GenSigTimeoutMsg_DQ" SG_ 1056 KO2_gef_Auss_T 1056;
BA_ "GenSigTimeoutTime_Otto" SG_ 1056 KO2_gef_Auss_T 2000;
BA_ "GenSigTimeoutMsg_Otto" SG_ 1056 KO2_gef_Auss_T 1056;
BA_ "GenSigSendType" SG_ 1056 KO2_gef_Auss_T 0;
BA_ "GenSigSendType" SG_ 1056 KO2_Bel_Schalt 0;
BA_ "GenSigSendType" SG_ 1056 KO2_Oelwarn 0;
BA_ "GenSigTimeoutTime_Teves_MK70_MAB" SG_ 1056 KO2_Aussen_T 2000;
BA_ "GenSigTimeoutMsg_Teves_MK70_MAB" SG_ 1056 KO2_Aussen_T 1056;
BA_ "GenSigTimeoutTime_Teves_MK60_ESP" SG_ 1056 KO2_Aussen_T 2000;
BA_ "GenSigTimeoutMsg_Teves_MK60_ESP" SG_ 1056 KO2_Aussen_T 1056;
BA_ "GenSigTimeoutTime_Diesel" SG_ 1056 KO2_Aussen_T 2000;
BA_ "GenSigTimeoutMsg_Diesel" SG_ 1056 KO2_Aussen_T 1056;
BA_ "GenSigTimeoutTime_Otto" SG_ 1056 KO2_Aussen_T 2000;
BA_ "GenSigTimeoutMsg_Otto" SG_ 1056 KO2_Aussen_T 1056;
BA_ "GenSigTimeoutTime_Magne_Ride" SG_ 1056 KO2_Aussen_T 2000;
BA_ "GenSigTimeoutMsg_Magne_Ride" SG_ 1056 KO2_Aussen_T 1056;
BA_ "GenSigTimeoutTime_PDC_PLA" SG_ 1056 KO2_Aussen_T 2000;
BA_ "GenSigTimeoutMsg_PDC_PLA" SG_ 1056 KO2_Aussen_T 1056;
BA_ "GenSigSendType" SG_ 1056 KO2_Aussen_T 0;
BA_ "INIT" SG_ 1056 KO2_Aussen_T "0/alt";
BA_ "GenSigSendType" SG_ 1056 KO2_Sta_Schalt 0;
BA_ "GenSigTimeoutTime_Daempfer" SG_ 1056 KO2_Sta_Displ 2000;
BA_ "GenSigTimeoutMsg_Daempfer" SG_ 1056 KO2_Sta_Displ 1056;
BA_ "GenSigTimeoutTime_PDC_PLA" SG_ 1056 KO2_Sta_Displ 2000;
BA_ "GenSigTimeoutMsg_PDC_PLA" SG_ 1056 KO2_Sta_Displ 1056;
BA_ "GenSigTimeoutTime_Waehlhebel_Sel" SG_ 1056 KO2_Sta_Displ 2000;
BA_ "GenSigTimeoutMsg_Waehlhebel_Sel" SG_ 1056 KO2_Sta_Displ 1056;
BA_ "GenSigTimeoutTime_Magne_Ride" SG_ 1056 KO2_Sta_Displ 2000;
BA_ "GenSigTimeoutMsg_Magne_Ride" SG_ 1056 KO2_Sta_Displ 1056;
BA_ "GenSigTimeoutTime_Airbag" SG_ 1056 KO2_Sta_Displ 2000;
BA_ "GenSigTimeoutMsg_Airbag" SG_ 1056 KO2_Sta_Displ 1056;
BA_ "GenSigSendType" SG_ 1056 KO2_Sta_Displ 0;
BA_ "GenSigTimeoutTime_Daempfer" SG_ 1056 KO2_Bel_Displ 2000;
BA_ "GenSigTimeoutMsg_Daempfer" SG_ 1056 KO2_Bel_Displ 1056;
BA_ "GenSigTimeoutTime_PDC_PLA" SG_ 1056 KO2_Bel_Displ 2000;
BA_ "GenSigTimeoutMsg_PDC_PLA" SG_ 1056 KO2_Bel_Displ 1056;
BA_ "GenSigTimeoutTime_Waehlhebel_Sel" SG_ 1056 KO2_Bel_Displ 2000;
BA_ "GenSigTimeoutMsg_Waehlhebel_Sel" SG_ 1056 KO2_Bel_Displ 1056;
BA_ "GenSigTimeoutTime_Magne_Ride" SG_ 1056 KO2_Bel_Displ 2000;
BA_ "GenSigTimeoutMsg_Magne_Ride" SG_ 1056 KO2_Bel_Displ 1056;
BA_ "GenSigTimeoutTime_Airbag" SG_ 1056 KO2_Bel_Displ 2000;
BA_ "GenSigTimeoutMsg_Airbag" SG_ 1056 KO2_Bel_Displ 1056;
BA_ "GenSigSendType" SG_ 1056 KO2_Bel_Displ 0;
BA_ "GenSigSendType" SG_ 1056 KO2_Fehlereintr 0;
BA_ "GenSigSendType" SG_ 1056 KO2_Reserve5 0;
BA_ "GenSigSendType" SG_ 1056 KO2_Wischwasser 0;
BA_ "GenSigTimeoutTime_PDC_PLA" SG_ 1056 KO2_PLA_Displaystatus 2000;
BA_ "GenSigTimeoutMsg_PDC_PLA" SG_ 1056 KO2_PLA_Displaystatus 1056;
BA_ "GenSigSendType" SG_ 1056 KO2_PLA_Displaystatus 0;
BA_ "GenSigTimeoutTime_Otto" SG_ 1056 KO2_GRA_High 2000;
BA_ "GenSigTimeoutMsg_Otto" SG_ 1056 KO2_GRA_High 1056;
BA_ "GenSigTimeoutTime_Diesel" SG_ 1056 KO2_GRA_High 2000;
BA_ "GenSigTimeoutMsg_Diesel" SG_ 1056 KO2_GRA_High 1056;
BA_ "GenSigSendType" SG_ 1056 KO2_GRA_High 0;
BA_ "GenSigSendType" SG_ 1056 KO2_Kuehlm_T 0;
BA_ "INIT" SG_ 1056 KO2_Kuehlm_T "0/alt";
BA_ "GenSigTimeoutTime_Otto" SG_ 1056 KO2_Verb_TOG 2000;
BA_ "GenSigTimeoutMsg_Otto" SG_ 1056 KO2_Verb_TOG 1056;
BA_ "GenSigTimeoutTime_Hybrid_MSG" SG_ 1056 KO2_Verb_TOG 2000;
BA_ "GenSigTimeoutMsg_Hybrid_MSG" SG_ 1056 KO2_Verb_TOG 1056;
BA_ "GenSigTimeoutTime_Diesel" SG_ 1056 KO2_Verb_TOG 2000;
BA_ "GenSigTimeoutMsg_Diesel" SG_ 1056 KO2_Verb_TOG 1056;
BA_ "GenSigSendType" SG_ 1056 KO2_Verb_TOG 0;
BA_ "GenSigSendType" SG_ 1056 KO2_OelTemp 0;
BA_ "INIT" SG_ 1056 KO2_OelTemp "0/alt";
BA_ "GenSigTimeoutTime_Hybrid_MSG" SG_ 1056 KO2_MFA_v_Einheit 2000;
BA_ "GenSigTimeoutMsg_Hybrid_MSG" SG_ 1056 KO2_MFA_v_Einheit 1056;
BA_ "GenSigTimeoutTime_Otto" SG_ 1056 KO2_MFA_v_Einheit 2000;
BA_ "GenSigTimeoutMsg_Otto" SG_ 1056 KO2_MFA_v_Einheit 1056;
BA_ "GenSigTimeoutTime_Diesel" SG_ 1056 KO2_MFA_v_Einheit 2000;
BA_ "GenSigTimeoutMsg_Diesel" SG_ 1056 KO2_MFA_v_Einheit 1056;
BA_ "GenSigSendType" SG_ 1056 KO2_MFA_v_Einheit 0;
BA_ "GenSigTimeoutTime_Hybrid_MSG" SG_ 1056 KO2_OBD_Nib_Temp 2000;
BA_ "GenSigTimeoutMsg_Hybrid_MSG" SG_ 1056 KO2_OBD_Nib_Temp 1056;
BA_ "GenSigTimeoutTime_Otto" SG_ 1056 KO2_OBD_Nib_Temp 2000;
BA_ "GenSigTimeoutMsg_Otto" SG_ 1056 KO2_OBD_Nib_Temp 1056;
BA_ "GenSigTimeoutTime_Diesel" SG_ 1056 KO2_OBD_Nib_Temp 2000;
BA_ "GenSigTimeoutMsg_Diesel" SG_ 1056 KO2_OBD_Nib_Temp 1056;
BA_ "GenSigSendType" SG_ 1056 KO2_OBD_Nib_Temp 0;
BA_ "GenSigSendType" SG_ 1056 KO2_Passiv_Autolock 0;
BA_ "GenSigSendType" SG_ 1056 KO2_WFS_Schl_Ort 0;
BA_ "GenSigTimeoutTime_FLA" SG_ 912 GK1_Sta_Licht1 1000;
BA_ "GenSigTimeoutMsg_FLA" SG_ 912 GK1_Sta_Licht1 912;
BA_ "GenSigTimeoutTime_EPB" SG_ 912 GK1_Sta_Licht1 1000;
BA_ "GenSigTimeoutMsg_EPB" SG_ 912 GK1_Sta_Licht1 912;
BA_ "GenSigTimeoutTime_Lenkhilfe_ZF_3" SG_ 912 GK1_Sta_Licht1 1000;
BA_ "GenSigTimeoutMsg_Lenkhilfe_ZF_3" SG_ 912 GK1_Sta_Licht1 912;
BA_ "GenSigTimeoutTime_Lenkhilfe_ZF_2" SG_ 912 GK1_Sta_Licht1 1000;
BA_ "GenSigTimeoutMsg_Lenkhilfe_ZF_2" SG_ 912 GK1_Sta_Licht1 912;
BA_ "GenSigTimeoutTime_Otto" SG_ 912 GK1_Sta_Licht1 1000;
BA_ "GenSigTimeoutMsg_Otto" SG_ 912 GK1_Sta_Licht1 912;
BA_ "GenSigTimeoutTime_Diesel" SG_ 912 GK1_Sta_Licht1 1000;
BA_ "GenSigTimeoutMsg_Diesel" SG_ 912 GK1_Sta_Licht1 912;
BA_ "GenSigTimeoutTime_Lenkhilfe_APA" SG_ 912 GK1_Sta_Licht1 1000;
BA_ "GenSigTimeoutMsg_Lenkhilfe_APA" SG_ 912 GK1_Sta_Licht1 912;
BA_ "GenSigTimeoutTime_SWA" SG_ 912 GK1_Sta_Licht1 1000;
BA_ "GenSigTimeoutMsg_SWA" SG_ 912 GK1_Sta_Licht1 912;
BA_ "GenSigTimeoutTime_PDC_PLA" SG_ 912 GK1_Sta_Licht1 1000;
BA_ "GenSigTimeoutMsg_PDC_PLA" SG_ 912 GK1_Sta_Licht1 912;
BA_ "GenSigTimeoutTime_AFS" SG_ 912 GK1_Sta_Licht1 1000;
BA_ "GenSigTimeoutMsg_AFS" SG_ 912 GK1_Sta_Licht1 912;
BA_ "GenSigTimeoutTime_TRW_ESP" SG_ 912 GK1_Sta_Licht1 1000;
BA_ "GenSigTimeoutMsg_TRW_ESP" SG_ 912 GK1_Sta_Licht1 912;
BA_ "GenSigTimeoutTime_Teves_MK70_MAB" SG_ 912 GK1_Sta_Licht1 1000;
BA_ "GenSigTimeoutMsg_Teves_MK70_MAB" SG_ 912 GK1_Sta_Licht1 912;
BA_ "GenSigTimeoutTime_Teves_MK60_ESP" SG_ 912 GK1_Sta_Licht1 1000;
BA_ "GenSigTimeoutMsg_Teves_MK60_ESP" SG_ 912 GK1_Sta_Licht1 912;
BA_ "GenSigSendType" SG_ 912 GK1_Sta_Licht1 0;
BA_ "GenSigStartValue" SG_ 912 GK1_Sta_Licht1 1;
BA_ "GenSigTimeoutTime_TRW_ESP" SG_ 912 GK1_Sta_Licht3 1000;
BA_ "GenSigTimeoutMsg_TRW_ESP" SG_ 912 GK1_Sta_Licht3 912;
BA_ "GenSigTimeoutTime_AFS" SG_ 912 GK1_Sta_Licht3 1000;
BA_ "GenSigTimeoutMsg_AFS" SG_ 912 GK1_Sta_Licht3 912;
BA_ "GenSigSendType" SG_ 912 GK1_Sta_Licht3 0;
BA_ "GenSigStartValue" SG_ 912 GK1_Sta_Licht3 1;
BA_ "GenSigTimeoutTime_HCA" SG_ 912 GK1_Sta_Anhaen 1000;
BA_ "GenSigTimeoutMsg_HCA" SG_ 912 GK1_Sta_Anhaen 912;
BA_ "GenSigTimeoutTime_SWA" SG_ 912 GK1_Sta_Anhaen 1000;
BA_ "GenSigTimeoutMsg_SWA" SG_ 912 GK1_Sta_Anhaen 912;
BA_ "GenSigTimeoutTime_Otto" SG_ 912 GK1_Sta_Anhaen 1000;
BA_ "GenSigTimeoutMsg_Otto" SG_ 912 GK1_Sta_Anhaen 912;
BA_ "GenSigTimeoutTime_Diesel" SG_ 912 GK1_Sta_Anhaen 1000;
BA_ "GenSigTimeoutMsg_Diesel" SG_ 912 GK1_Sta_Anhaen 912;
BA_ "GenSigTimeoutTime_Hybrid_DQ200" SG_ 912 GK1_Sta_Anhaen 1000;
BA_ "GenSigTimeoutMsg_Hybrid_DQ200" SG_ 912 GK1_Sta_Anhaen 912;
BA_ "GenSigTimeoutTime_PDC_PLA" SG_ 912 GK1_Sta_Anhaen 1000;
BA_ "GenSigTimeoutMsg_PDC_PLA" SG_ 912 GK1_Sta_Anhaen 912;
BA_ "GenSigTimeoutTime_RKA_Plus" SG_ 912 GK1_Sta_Anhaen 1000;
BA_ "GenSigTimeoutMsg_RKA_Plus" SG_ 912 GK1_Sta_Anhaen 912;
BA_ "GenSigTimeoutTime_TRW_ESP" SG_ 912 GK1_Sta_Anhaen 1000;
BA_ "GenSigTimeoutMsg_TRW_ESP" SG_ 912 GK1_Sta_Anhaen 912;
BA_ "GenSigTimeoutTime_DQ" SG_ 912 GK1_Sta_Anhaen 1000;
BA_ "GenSigTimeoutMsg_DQ" SG_ 912 GK1_Sta_Anhaen 912;
BA_ "GenSigTimeoutTime_Teves_MK60_ESP" SG_ 912 GK1_Sta_Anhaen 1000;
BA_ "GenSigTimeoutMsg_Teves_MK60_ESP" SG_ 912 GK1_Sta_Anhaen 912;
BA_ "GenSigSendType" SG_ 912 GK1_Sta_Anhaen 0;
BA_ "GenSigStartValue" SG_ 912 GK1_Sta_Anhaen 1;
BA_ "GenSigTimeoutTime_Diesel" SG_ 912 GK1_Sta_Tuerkont 1000;
BA_ "GenSigTimeoutMsg_Diesel" SG_ 912 GK1_Sta_Tuerkont 912;
BA_ "GenSigTimeoutTime_Otto" SG_ 912 GK1_Sta_Tuerkont 1000;
BA_ "GenSigTimeoutMsg_Otto" SG_ 912 GK1_Sta_Tuerkont 912;
BA_ "GenSigTimeoutTime_Hybrid_MSG" SG_ 912 GK1_Sta_Tuerkont 1000;
BA_ "GenSigTimeoutMsg_Hybrid_MSG" SG_ 912 GK1_Sta_Tuerkont 912;
BA_ "GenSigTimeoutTime_TRW_ESP" SG_ 912 GK1_Sta_Tuerkont 1000;
BA_ "GenSigTimeoutMsg_TRW_ESP" SG_ 912 GK1_Sta_Tuerkont 912;
BA_ "GenSigTimeoutTime_EPB" SG_ 912 GK1_Sta_Tuerkont 1000;
BA_ "GenSigTimeoutMsg_EPB" SG_ 912 GK1_Sta_Tuerkont 912;
BA_ "GenSigTimeoutTime_Teves_MK70_MAB" SG_ 912 GK1_Sta_Tuerkont 1000;
BA_ "GenSigTimeoutMsg_Teves_MK70_MAB" SG_ 912 GK1_Sta_Tuerkont 912;
BA_ "GenSigTimeoutTime_Teves_MK60_ESP" SG_ 912 GK1_Sta_Tuerkont 1000;
BA_ "GenSigTimeoutMsg_Teves_MK60_ESP" SG_ 912 GK1_Sta_Tuerkont 912;
BA_ "GenSigSendType" SG_ 912 GK1_Sta_Tuerkont 0;
BA_ "GenSigStartValue" SG_ 912 GK1_Sta_Tuerkont 1;
BA_ "GenSigTimeoutTime_TRW_ESP" SG_ 912 GK1_Sta_RDK_Warn 1000;
BA_ "GenSigTimeoutMsg_TRW_ESP" SG_ 912 GK1_Sta_RDK_Warn 912;
BA_ "GenSigSendType" SG_ 912 GK1_Sta_RDK_Warn 0;
BA_ "GenSigStartValue" SG_ 912 GK1_Sta_RDK_Warn 1;
BA_ "GenSigTimeoutTime_Lenkhilfe_ZF_3" SG_ 912 GK1_SleepAckn 1000;
BA_ "GenSigTimeoutMsg_Lenkhilfe_ZF_3" SG_ 912 GK1_SleepAckn 912;
BA_ "GenSigTimeoutTime_Selespeed" SG_ 912 GK1_SleepAckn 1000;
BA_ "GenSigTimeoutMsg_Selespeed" SG_ 912 GK1_SleepAckn 912;
BA_ "GenSigTimeoutTime_Hybrid_DQ200" SG_ 912 GK1_SleepAckn 1000;
BA_ "GenSigTimeoutMsg_Hybrid_DQ200" SG_ 912 GK1_SleepAckn 912;
BA_ "GenSigTimeoutTime_Hybrid_MSG" SG_ 912 GK1_SleepAckn 1000;
BA_ "GenSigTimeoutMsg_Hybrid_MSG" SG_ 912 GK1_SleepAckn 912;
BA_ "GenSigTimeoutTime_Lenkhilfe_APA" SG_ 912 GK1_SleepAckn 1000;
BA_ "GenSigTimeoutMsg_Lenkhilfe_APA" SG_ 912 GK1_SleepAckn 912;
BA_ "GenSigTimeoutTime_Waehlhebel_Sel" SG_ 912 GK1_SleepAckn 1000;
BA_ "GenSigTimeoutMsg_Waehlhebel_Sel" SG_ 912 GK1_SleepAckn 912;
BA_ "GenSigTimeoutTime_TRW_ESP" SG_ 912 GK1_SleepAckn 1000;
BA_ "GenSigTimeoutMsg_TRW_ESP" SG_ 912 GK1_SleepAckn 912;
BA_ "GenSigTimeoutTime_EPB" SG_ 912 GK1_SleepAckn 1000;
BA_ "GenSigTimeoutMsg_EPB" SG_ 912 GK1_SleepAckn 912;
BA_ "GenSigTimeoutTime_DQ" SG_ 912 GK1_SleepAckn 1000;
BA_ "GenSigTimeoutMsg_DQ" SG_ 912 GK1_SleepAckn 912;
BA_ "GenSigTimeoutTime_Teves_MK70_MAB" SG_ 912 GK1_SleepAckn 1000;
BA_ "GenSigTimeoutMsg_Teves_MK70_MAB" SG_ 912 GK1_SleepAckn 912;
BA_ "GenSigTimeoutTime_LWS" SG_ 912 GK1_SleepAckn 1000;
BA_ "GenSigTimeoutMsg_LWS" SG_ 912 GK1_SleepAckn 912;
BA_ "GenSigTimeoutTime_Teves_MK60_ESP" SG_ 912 GK1_SleepAckn 1000;
BA_ "GenSigTimeoutMsg_Teves_MK60_ESP" SG_ 912 GK1_SleepAckn 912;
BA_ "GenSigTimeoutTime_Otto" SG_ 912 GK1_SleepAckn 1000;
BA_ "GenSigTimeoutMsg_Otto" SG_ 912 GK1_SleepAckn 912;
BA_ "GenSigTimeoutTime_Lenkhilfe_ZF_2" SG_ 912 GK1_SleepAckn 1000;
BA_ "GenSigTimeoutMsg_Lenkhilfe_ZF_2" SG_ 912 GK1_SleepAckn 912;
BA_ "GenSigTimeoutTime_Diesel" SG_ 912 GK1_SleepAckn 1000;
BA_ "GenSigTimeoutMsg_Diesel" SG_ 912 GK1_SleepAckn 912;
BA_ "GenSigTimeoutTime_AG6" SG_ 912 GK1_SleepAckn 1000;
BA_ "GenSigTimeoutMsg_AG6" SG_ 912 GK1_SleepAckn 912;
BA_ "GenSigSendType" SG_ 912 GK1_SleepAckn 0;
BA_ "GenSigTimeoutTime_Otto" SG_ 912 GK1_Fa_Tuerkont 1000;
BA_ "GenSigTimeoutMsg_Otto" SG_ 912 GK1_Fa_Tuerkont 912;
BA_ "GenSigTimeoutTime_Diesel" SG_ 912 GK1_Fa_Tuerkont 1000;
BA_ "GenSigTimeoutMsg_Diesel" SG_ 912 GK1_Fa_Tuerkont 912;
BA_ "GenSigTimeoutTime_Hybrid_MSG" SG_ 912 GK1_Fa_Tuerkont 1000;
BA_ "GenSigTimeoutMsg_Hybrid_MSG" SG_ 912 GK1_Fa_Tuerkont 912;
BA_ "GenSigTimeoutTime_TRW_ESP" SG_ 912 GK1_Fa_Tuerkont 1000;
BA_ "GenSigTimeoutMsg_TRW_ESP" SG_ 912 GK1_Fa_Tuerkont 912;
BA_ "GenSigTimeoutTime_EPB" SG_ 912 GK1_Fa_Tuerkont 1000;
BA_ "GenSigTimeoutMsg_EPB" SG_ 912 GK1_Fa_Tuerkont 912;
BA_ "GenSigTimeoutTime_Teves_MK70_MAB" SG_ 912 GK1_Fa_Tuerkont 1000;
BA_ "GenSigTimeoutMsg_Teves_MK70_MAB" SG_ 912 GK1_Fa_Tuerkont 912;
BA_ "GenSigTimeoutTime_Teves_MK60_ESP" SG_ 912 GK1_Fa_Tuerkont 1000;
BA_ "GenSigTimeoutMsg_Teves_MK60_ESP" SG_ 912 GK1_Fa_Tuerkont 912;
BA_ "GenSigSendType" SG_ 912 GK1_Fa_Tuerkont 0;
BA_ "GenSigTimeoutTime_TRW_ESP" SG_ 912 GK1_BLS_ILM 1000;
BA_ "GenSigTimeoutMsg_TRW_ESP" SG_ 912 GK1_BLS_ILM 912;
BA_ "GenSigSendType" SG_ 912 GK1_BLS_ILM 0;
BA_ "GenSigTimeoutTime_TRW_ESP" SG_ 912 GK1_Count_Li_Hi 1000;
BA_ "GenSigTimeoutMsg_TRW_ESP" SG_ 912 GK1_Count_Li_Hi 912;
BA_ "GenSigSendType" SG_ 912 GK1_Count_Li_Hi 0;
BA_ "GenSigTimeoutTime_TRW_ESP" SG_ 912 GK1_BrLi_links 1000;
BA_ "GenSigTimeoutMsg_TRW_ESP" SG_ 912 GK1_BrLi_links 912;
BA_ "GenSigSendType" SG_ 912 GK1_BrLi_links 0;
BA_ "GenSigTimeoutTime_TRW_ESP" SG_ 912 GK1_BrLi_rechts 1000;
BA_ "GenSigTimeoutMsg_TRW_ESP" SG_ 912 GK1_BrLi_rechts 912;
BA_ "GenSigSendType" SG_ 912 GK1_BrLi_rechts 0;
BA_ "GenSigTimeoutTime_Hybrid_MSG" SG_ 912 GK1_KW_Warm 1000;
BA_ "GenSigTimeoutMsg_Hybrid_MSG" SG_ 912 GK1_KW_Warm 912;
BA_ "GenSigTimeoutTime_TRW_ESP" SG_ 912 GK1_KW_Warm 1000;
BA_ "GenSigTimeoutMsg_TRW_ESP" SG_ 912 GK1_KW_Warm 912;
BA_ "GenSigTimeoutTime_Otto" SG_ 912 GK1_KW_Warm 1000;
BA_ "GenSigTimeoutMsg_Otto" SG_ 912 GK1_KW_Warm 912;
BA_ "GenSigSendType" SG_ 912 GK1_KW_Warm 0;
BA_ "GenSigTimeoutTime_TRW_ESP" SG_ 912 GK1_BrLi_mitte 1000;
BA_ "GenSigTimeoutMsg_TRW_ESP" SG_ 912 GK1_BrLi_mitte 912;
BA_ "GenSigSendType" SG_ 912 GK1_BrLi_mitte 0;
BA_ "GenSigTimeoutTime_TRW_ESP" SG_ 912 GK1_EDC_ILM 1000;
BA_ "GenSigTimeoutMsg_TRW_ESP" SG_ 912 GK1_EDC_ILM 912;
BA_ "GenSigSendType" SG_ 912 GK1_EDC_ILM 0;
BA_ "GenSigTimeoutTime_TRW_ESP" SG_ 912 GK1_EDC_AAG 1000;
BA_ "GenSigTimeoutMsg_TRW_ESP" SG_ 912 GK1_EDC_AAG 912;
BA_ "GenSigSendType" SG_ 912 GK1_EDC_AAG 0;
BA_ "GenSigTimeoutTime_TRW_ESP" SG_ 912 GK1_Count_Anhaen 1000;
BA_ "GenSigTimeoutMsg_TRW_ESP" SG_ 912 GK1_Count_Anhaen 912;
BA_ "GenSigSendType" SG_ 912 GK1_Count_Anhaen 0;
BA_ "GenSigTimeoutTime_TRW_ESP" SG_ 912 GK1_BLS_AAG 1000;
BA_ "GenSigTimeoutMsg_TRW_ESP" SG_ 912 GK1_BLS_AAG 912;
BA_ "GenSigSendType" SG_ 912 GK1_BLS_AAG 0;
BA_ "GenSigTimeoutTime_FLA" SG_ 912 GK1_LS1_Fernlicht 1000;
BA_ "GenSigTimeoutMsg_FLA" SG_ 912 GK1_LS1_Fernlicht 912;
BA_ "GenSigTimeoutTime_TRW_ESP" SG_ 912 GK1_LS1_Fernlicht 1000;
BA_ "GenSigTimeoutMsg_TRW_ESP" SG_ 912 GK1_LS1_Fernlicht 912;
BA_ "GenSigSendType" SG_ 912 GK1_LS1_Fernlicht 0;
BA_ "GenSigTimeoutTime_FLA" SG_ 912 GK1_Rueckfahr 1000;
BA_ "GenSigTimeoutMsg_FLA" SG_ 912 GK1_Rueckfahr 912;
BA_ "GenSigTimeoutTime_Lenkhilfe_ZF_3" SG_ 912 GK1_Rueckfahr 1000;
BA_ "GenSigTimeoutMsg_Lenkhilfe_ZF_3" SG_ 912 GK1_Rueckfahr 912;
BA_ "GenSigTimeoutTime_Lenkhilfe_ZF_2" SG_ 912 GK1_Rueckfahr 1000;
BA_ "GenSigTimeoutMsg_Lenkhilfe_ZF_2" SG_ 912 GK1_Rueckfahr 912;
BA_ "GenSigTimeoutTime_Lenkhilfe_APA" SG_ 912 GK1_Rueckfahr 1000;
BA_ "GenSigTimeoutMsg_Lenkhilfe_APA" SG_ 912 GK1_Rueckfahr 912;
BA_ "GenSigTimeoutTime_Diesel" SG_ 912 GK1_Rueckfahr 1000;
BA_ "GenSigTimeoutMsg_Diesel" SG_ 912 GK1_Rueckfahr 912;
BA_ "GenSigTimeoutTime_Otto" SG_ 912 GK1_Rueckfahr 1000;
BA_ "GenSigTimeoutMsg_Otto" SG_ 912 GK1_Rueckfahr 912;
BA_ "GenSigTimeoutTime_SWA" SG_ 912 GK1_Rueckfahr 1000;
BA_ "GenSigTimeoutMsg_SWA" SG_ 912 GK1_Rueckfahr 912;
BA_ "GenSigTimeoutTime_PDC_PLA" SG_ 912 GK1_Rueckfahr 1000;
BA_ "GenSigTimeoutMsg_PDC_PLA" SG_ 912 GK1_Rueckfahr 912;
BA_ "GenSigTimeoutTime_AFS" SG_ 912 GK1_Rueckfahr 1000;
BA_ "GenSigTimeoutMsg_AFS" SG_ 912 GK1_Rueckfahr 912;
BA_ "GenSigTimeoutTime_TRW_ESP" SG_ 912 GK1_Rueckfahr 1000;
BA_ "GenSigTimeoutMsg_TRW_ESP" SG_ 912 GK1_Rueckfahr 912;
BA_ "GenSigTimeoutTime_EPB" SG_ 912 GK1_Rueckfahr 1000;
BA_ "GenSigTimeoutMsg_EPB" SG_ 912 GK1_Rueckfahr 912;
BA_ "GenSigTimeoutTime_Teves_MK70_MAB" SG_ 912 GK1_Rueckfahr 1000;
BA_ "GenSigTimeoutMsg_Teves_MK70_MAB" SG_ 912 GK1_Rueckfahr 912;
BA_ "GenSigTimeoutTime_Teves_MK60_ESP" SG_ 912 GK1_Rueckfahr 1000;
BA_ "GenSigTimeoutMsg_Teves_MK60_ESP" SG_ 912 GK1_Rueckfahr 912;
BA_ "GenSigSendType" SG_ 912 GK1_Rueckfahr 0;
BA_ "GenSigTimeoutTime_HCA" SG_ 912 GK1_Anhaenger 1000;
BA_ "GenSigTimeoutMsg_HCA" SG_ 912 GK1_Anhaenger 912;
BA_ "GenSigTimeoutTime_SWA" SG_ 912 GK1_Anhaenger 1000;
BA_ "GenSigTimeoutMsg_SWA" SG_ 912 GK1_Anhaenger 912;
BA_ "GenSigTimeoutTime_Diesel" SG_ 912 GK1_Anhaenger 1000;
BA_ "GenSigTimeoutMsg_Diesel" SG_ 912 GK1_Anhaenger 912;
BA_ "GenSigTimeoutTime_Otto" SG_ 912 GK1_Anhaenger 1000;
BA_ "GenSigTimeoutMsg_Otto" SG_ 912 GK1_Anhaenger 912;
BA_ "GenSigTimeoutTime_Hybrid_DQ200" SG_ 912 GK1_Anhaenger 1000;
BA_ "GenSigTimeoutMsg_Hybrid_DQ200" SG_ 912 GK1_Anhaenger 912;
BA_ "GenSigTimeoutTime_PDC_PLA" SG_ 912 GK1_Anhaenger 1000;
BA_ "GenSigTimeoutMsg_PDC_PLA" SG_ 912 GK1_Anhaenger 912;
BA_ "GenSigTimeoutTime_RKA_Plus" SG_ 912 GK1_Anhaenger 1000;
BA_ "GenSigTimeoutMsg_RKA_Plus" SG_ 912 GK1_Anhaenger 912;
BA_ "GenSigTimeoutTime_TRW_ESP" SG_ 912 GK1_Anhaenger 1000;
BA_ "GenSigTimeoutMsg_TRW_ESP" SG_ 912 GK1_Anhaenger 912;
BA_ "GenSigTimeoutTime_DQ" SG_ 912 GK1_Anhaenger 1000;
BA_ "GenSigTimeoutMsg_DQ" SG_ 912 GK1_Anhaenger 912;
BA_ "GenSigTimeoutTime_Teves_MK60_ESP" SG_ 912 GK1_Anhaenger 1000;
BA_ "GenSigTimeoutMsg_Teves_MK60_ESP" SG_ 912 GK1_Anhaenger 912;
BA_ "GenSigSendType" SG_ 912 GK1_Anhaenger 0;
BA_ "GenSigTimeoutTime_FLA" SG_ 912 GK1_Abblendlicht 1000;
BA_ "GenSigTimeoutMsg_FLA" SG_ 912 GK1_Abblendlicht 912;
BA_ "GenSigTimeoutTime_AFS" SG_ 912 GK1_Abblendlicht 1000;
BA_ "GenSigTimeoutMsg_AFS" SG_ 912 GK1_Abblendlicht 912;
BA_ "GenSigTimeoutTime_TRW_ESP" SG_ 912 GK1_Abblendlicht 1000;
BA_ "GenSigTimeoutMsg_TRW_ESP" SG_ 912 GK1_Abblendlicht 912;
BA_ "GenSigTimeoutTime_LWR" SG_ 912 GK1_Abblendlicht 1000;
BA_ "GenSigTimeoutMsg_LWR" SG_ 912 GK1_Abblendlicht 912;
BA_ "GenSigSendType" SG_ 912 GK1_Abblendlicht 0;
BA_ "GenSigTimeoutTime_TRW_ESP" SG_ 912 GK1_BrLi_Anhaen 1000;
BA_ "GenSigTimeoutMsg_TRW_ESP" SG_ 912 GK1_BrLi_Anhaen 912;
BA_ "GenSigSendType" SG_ 912 GK1_BrLi_Anhaen 0;
BA_ "GenSigTimeoutTime_Otto" SG_ 912 GK1_Blinker_re 1000;
BA_ "GenSigTimeoutMsg_Otto" SG_ 912 GK1_Blinker_re 912;
BA_ "GenSigTimeoutTime_Diesel" SG_ 912 GK1_Blinker_re 1000;
BA_ "GenSigTimeoutMsg_Diesel" SG_ 912 GK1_Blinker_re 912;
BA_ "GenSigTimeoutTime_PDC_PLA" SG_ 912 GK1_Blinker_re 1000;
BA_ "GenSigTimeoutMsg_PDC_PLA" SG_ 912 GK1_Blinker_re 912;
BA_ "GenSigTimeoutTime_AFS" SG_ 912 GK1_Blinker_re 1000;
BA_ "GenSigTimeoutMsg_AFS" SG_ 912 GK1_Blinker_re 912;
BA_ "GenSigTimeoutTime_TRW_ESP" SG_ 912 GK1_Blinker_re 1000;
BA_ "GenSigTimeoutMsg_TRW_ESP" SG_ 912 GK1_Blinker_re 912;
BA_ "GenSigTimeoutTime_LWR" SG_ 912 GK1_Blinker_re 1000;
BA_ "GenSigTimeoutMsg_LWR" SG_ 912 GK1_Blinker_re 912;
BA_ "GenSigSendType" SG_ 912 GK1_Blinker_re 0;
BA_ "GenSigTimeoutTime_Otto" SG_ 912 GK1_Blinker_li 1000;
BA_ "GenSigTimeoutMsg_Otto" SG_ 912 GK1_Blinker_li 912;
BA_ "GenSigTimeoutTime_Diesel" SG_ 912 GK1_Blinker_li 1000;
BA_ "GenSigTimeoutMsg_Diesel" SG_ 912 GK1_Blinker_li 912;
BA_ "GenSigTimeoutTime_PDC_PLA" SG_ 912 GK1_Blinker_li 1000;
BA_ "GenSigTimeoutMsg_PDC_PLA" SG_ 912 GK1_Blinker_li 912;
BA_ "GenSigTimeoutTime_AFS" SG_ 912 GK1_Blinker_li 1000;
BA_ "GenSigTimeoutMsg_AFS" SG_ 912 GK1_Blinker_li 912;
BA_ "GenSigTimeoutTime_TRW_ESP" SG_ 912 GK1_Blinker_li 1000;
BA_ "GenSigTimeoutMsg_TRW_ESP" SG_ 912 GK1_Blinker_li 912;
BA_ "GenSigTimeoutTime_LWR" SG_ 912 GK1_Blinker_li 1000;
BA_ "GenSigTimeoutMsg_LWR" SG_ 912 GK1_Blinker_li 912;
BA_ "GenSigSendType" SG_ 912 GK1_Blinker_li 0;
BA_ "GenSigTimeoutTime_TRW_ESP" SG_ 912 GK1_Anh_abgesteckt 1000;
BA_ "GenSigTimeoutMsg_TRW_ESP" SG_ 912 GK1_Anh_abgesteckt 912;
BA_ "GenSigSendType" SG_ 912 GK1_Anh_abgesteckt 0;
BA_ "GenSigTimeoutTime_TRW_ESP" SG_ 912 GK1_Sta_Li_vorn 1000;
BA_ "GenSigTimeoutMsg_TRW_ESP" SG_ 912 GK1_Sta_Li_vorn 912;
BA_ "GenSigTimeoutTime_AFS" SG_ 912 GK1_Sta_Li_vorn 1000;
BA_ "GenSigTimeoutMsg_AFS" SG_ 912 GK1_Sta_Li_vorn 912;
BA_ "GenSigSendType" SG_ 912 GK1_Sta_Li_vorn 0;
BA_ "INIT" SG_ 912 GK1_Sta_Li_vorn "0/1";
BA_ "GenSigTimeoutTime_TRW_ESP" SG_ 912 GK1_Warnblk_Status 1000;
BA_ "GenSigTimeoutMsg_TRW_ESP" SG_ 912 GK1_Warnblk_Status 912;
BA_ "GenSigSendType" SG_ 912 GK1_Warnblk_Status 0;
BA_ "GenSigTimeoutTime_FLA" SG_ 912 GK1_Fernlicht 1000;
BA_ "GenSigTimeoutMsg_FLA" SG_ 912 GK1_Fernlicht 912;
BA_ "GenSigTimeoutTime_AFS" SG_ 912 GK1_Fernlicht 1000;
BA_ "GenSigTimeoutMsg_AFS" SG_ 912 GK1_Fernlicht 912;
BA_ "GenSigTimeoutTime_TRW_ESP" SG_ 912 GK1_Fernlicht 1000;
BA_ "GenSigTimeoutMsg_TRW_ESP" SG_ 912 GK1_Fernlicht 912;
BA_ "GenSigTimeoutTime_LWR" SG_ 912 GK1_Fernlicht 1000;
BA_ "GenSigTimeoutMsg_LWR" SG_ 912 GK1_Fernlicht 912;
BA_ "GenSigSendType" SG_ 912 GK1_Fernlicht 0;
BA_ "GenSigTimeoutTime_TRW_ESP" SG_ 912 GK1_RueckfahrSch 1000;
BA_ "GenSigTimeoutMsg_TRW_ESP" SG_ 912 GK1_RueckfahrSch 912;
BA_ "GenSigSendType" SG_ 912 GK1_RueckfahrSch 0;
BA_ "GenSigTimeoutTime_TRW_ESP" SG_ 912 GK1_res_06 1000;
BA_ "GenSigTimeoutMsg_TRW_ESP" SG_ 912 GK1_res_06 912;
BA_ "GenSigSendType" SG_ 912 GK1_res_06 0;
BA_ "INIT" SG_ 912 GK1_res_06 "0/1";
BA_ "GenSigTimeoutTime_AFS" SG_ 912 GK1_Abbl_VR_def 1000;
BA_ "GenSigTimeoutMsg_AFS" SG_ 912 GK1_Abbl_VR_def 912;
BA_ "GenSigTimeoutTime_TRW_ESP" SG_ 912 GK1_Abbl_VR_def 1000;
BA_ "GenSigTimeoutMsg_TRW_ESP" SG_ 912 GK1_Abbl_VR_def 912;
BA_ "GenSigSendType" SG_ 912 GK1_Abbl_VR_def 0;
BA_ "GenSigTimeoutTime_TRW_ESP" SG_ 912 GK1_Blink_Autob 1000;
BA_ "GenSigTimeoutMsg_TRW_ESP" SG_ 912 GK1_Blink_Autob 912;
BA_ "GenSigTimeoutTime_AFS" SG_ 912 GK1_Blink_Autob 1000;
BA_ "GenSigTimeoutMsg_AFS" SG_ 912 GK1_Blink_Autob 912;
BA_ "GenSigSendType" SG_ 912 GK1_Blink_Autob 0;
BA_ "GenSigTimeoutTime_HCA" SG_ 912 GK1_Wischer_vorn 1000;
BA_ "GenSigTimeoutMsg_HCA" SG_ 912 GK1_Wischer_vorn 912;
BA_ "GenSigTimeoutTime_Teves_MK70_MAB" SG_ 912 GK1_Wischer_vorn 1000;
BA_ "GenSigTimeoutMsg_Teves_MK70_MAB" SG_ 912 GK1_Wischer_vorn 912;
BA_ "GenSigTimeoutTime_AFS" SG_ 912 GK1_Wischer_vorn 1000;
BA_ "GenSigTimeoutMsg_AFS" SG_ 912 GK1_Wischer_vorn 912;
BA_ "GenSigTimeoutTime_TRW_ESP" SG_ 912 GK1_Wischer_vorn 1000;
BA_ "GenSigTimeoutMsg_TRW_ESP" SG_ 912 GK1_Wischer_vorn 912;
BA_ "GenSigTimeoutTime_Teves_MK60_ESP" SG_ 912 GK1_Wischer_vorn 1000;
BA_ "GenSigTimeoutMsg_Teves_MK60_ESP" SG_ 912 GK1_Wischer_vorn 912;
BA_ "GenSigTimeoutTime_Diesel" SG_ 912 GK1_Wischer_vorn 1000;
BA_ "GenSigTimeoutMsg_Diesel" SG_ 912 GK1_Wischer_vorn 912;
BA_ "GenSigSendType" SG_ 912 GK1_Wischer_vorn 0;
BA_ "GenSigTimeoutTime_AFS" SG_ 912 GK1_Abbl_VL_def 1000;
BA_ "GenSigTimeoutMsg_AFS" SG_ 912 GK1_Abbl_VL_def 912;
BA_ "GenSigTimeoutTime_TRW_ESP" SG_ 912 GK1_Abbl_VL_def 1000;
BA_ "GenSigTimeoutMsg_TRW_ESP" SG_ 912 GK1_Abbl_VL_def 912;
BA_ "GenSigSendType" SG_ 912 GK1_Abbl_VL_def 0;
BA_ "GenSigTimeoutTime_HCA" SG_ 912 GK1_Sta_ILM_F_1 1000;
BA_ "GenSigTimeoutMsg_HCA" SG_ 912 GK1_Sta_ILM_F_1 912;
BA_ "GenSigTimeoutTime_Teves_MK70_MAB" SG_ 912 GK1_Sta_ILM_F_1 1000;
BA_ "GenSigTimeoutMsg_Teves_MK70_MAB" SG_ 912 GK1_Sta_ILM_F_1 912;
BA_ "GenSigTimeoutTime_AFS" SG_ 912 GK1_Sta_ILM_F_1 1000;
BA_ "GenSigTimeoutMsg_AFS" SG_ 912 GK1_Sta_ILM_F_1 912;
BA_ "GenSigTimeoutTime_TRW_ESP" SG_ 912 GK1_Sta_ILM_F_1 1000;
BA_ "GenSigTimeoutMsg_TRW_ESP" SG_ 912 GK1_Sta_ILM_F_1 912;
BA_ "GenSigTimeoutTime_Teves_MK60_ESP" SG_ 912 GK1_Sta_ILM_F_1 1000;
BA_ "GenSigTimeoutMsg_Teves_MK60_ESP" SG_ 912 GK1_Sta_ILM_F_1 912;
BA_ "GenSigSendType" SG_ 912 GK1_Sta_ILM_F_1 0;
BA_ "GenSigStartValue" SG_ 912 GK1_Sta_ILM_F_1 1;
BA_ "GenSigTimeoutTime_TRW_ESP" SG_ 912 GK1_ELV_verrieg 1000;
BA_ "GenSigTimeoutMsg_TRW_ESP" SG_ 912 GK1_ELV_verrieg 912;
BA_ "GenSigTimeoutTime_EPB" SG_ 912 GK1_ELV_verrieg 1000;
BA_ "GenSigTimeoutMsg_EPB" SG_ 912 GK1_ELV_verrieg 912;
BA_ "GenSigSendType" SG_ 912 GK1_ELV_verrieg 0;
BA_ "GenSigTimeoutTime_Hybrid_DQ200" SG_ 912 GK1_def_P_verr 1000;
BA_ "GenSigTimeoutMsg_Hybrid_DQ200" SG_ 912 GK1_def_P_verr 912;
BA_ "GenSigTimeoutTime_TRW_ESP" SG_ 912 GK1_def_P_verr 1000;
BA_ "GenSigTimeoutMsg_TRW_ESP" SG_ 912 GK1_def_P_verr 912;
BA_ "GenSigTimeoutTime_DQ" SG_ 912 GK1_def_P_verr 1000;
BA_ "GenSigTimeoutMsg_DQ" SG_ 912 GK1_def_P_verr 912;
BA_ "GenSigTimeoutTime_AG6" SG_ 912 GK1_def_P_verr 1000;
BA_ "GenSigTimeoutMsg_AG6" SG_ 912 GK1_def_P_verr 912;
BA_ "GenSigSendType" SG_ 912 GK1_def_P_verr 0;
BA_ "GenSigTimeoutTime_EPB" SG_ 912 GK1_Sta_Kessy_2 1000;
BA_ "GenSigTimeoutMsg_EPB" SG_ 912 GK1_Sta_Kessy_2 912;
BA_ "GenSigTimeoutTime_TRW_ESP" SG_ 912 GK1_Sta_Kessy_2 1000;
BA_ "GenSigTimeoutMsg_TRW_ESP" SG_ 912 GK1_Sta_Kessy_2 912;
BA_ "GenSigSendType" SG_ 912 GK1_Sta_Kessy_2 0;
BA_ "GenSigStartValue" SG_ 912 GK1_Sta_Kessy_2 1;
BA_ "GenSigTimeoutTime_Hybrid_MSG" SG_ 912 GK1_SH_Verbau 1000;
BA_ "GenSigTimeoutMsg_Hybrid_MSG" SG_ 912 GK1_SH_Verbau 912;
BA_ "GenSigTimeoutTime_TRW_ESP" SG_ 912 GK1_SH_Verbau 1000;
BA_ "GenSigTimeoutMsg_TRW_ESP" SG_ 912 GK1_SH_Verbau 912;
BA_ "GenSigTimeoutTime_Otto" SG_ 912 GK1_SH_Verbau 1000;
BA_ "GenSigTimeoutMsg_Otto" SG_ 912 GK1_SH_Verbau 912;
BA_ "GenSigSendType" SG_ 912 GK1_SH_Verbau 0;
BA_ "GenSigTimeoutTime_FLA" SG_ 912 GK1_Sta_LSM 1000;
BA_ "GenSigTimeoutMsg_FLA" SG_ 912 GK1_Sta_LSM 912;
BA_ "GenSigTimeoutTime_Otto" SG_ 912 GK1_Sta_LSM 1000;
BA_ "GenSigTimeoutMsg_Otto" SG_ 912 GK1_Sta_LSM 912;
BA_ "GenSigTimeoutTime_Diesel" SG_ 912 GK1_Sta_LSM 1000;
BA_ "GenSigTimeoutMsg_Diesel" SG_ 912 GK1_Sta_LSM 912;
BA_ "GenSigTimeoutTime_PDC_PLA" SG_ 912 GK1_Sta_LSM 1000;
BA_ "GenSigTimeoutMsg_PDC_PLA" SG_ 912 GK1_Sta_LSM 912;
BA_ "GenSigTimeoutTime_AFS" SG_ 912 GK1_Sta_LSM 1000;
BA_ "GenSigTimeoutMsg_AFS" SG_ 912 GK1_Sta_LSM 912;
BA_ "GenSigTimeoutTime_TRW_ESP" SG_ 912 GK1_Sta_LSM 1000;
BA_ "GenSigTimeoutMsg_TRW_ESP" SG_ 912 GK1_Sta_LSM 912;
BA_ "GenSigTimeoutTime_AG6" SG_ 912 GK1_Sta_LSM 1000;
BA_ "GenSigTimeoutMsg_AG6" SG_ 912 GK1_Sta_LSM 912;
BA_ "GenSigSendType" SG_ 912 GK1_Sta_LSM 0;
BA_ "GenSigStartValue" SG_ 912 GK1_Sta_LSM 1;
BA_ "GenSigTimeoutTime_AFS" SG_ 912 GK1_Sta_Licht2 1000;
BA_ "GenSigTimeoutMsg_AFS" SG_ 912 GK1_Sta_Licht2 912;
BA_ "GenSigTimeoutTime_TRW_ESP" SG_ 912 GK1_Sta_Licht2 1000;
BA_ "GenSigTimeoutMsg_TRW_ESP" SG_ 912 GK1_Sta_Licht2 912;
BA_ "GenSigSendType" SG_ 912 GK1_Sta_Licht2 0;
BA_ "GenSigStartValue" SG_ 912 GK1_Sta_Licht2 1;
BA_ "GenSigTimeoutTime_Hybrid_MSG" SG_ 912 GK1_Sta_Stdhzg 1000;
BA_ "GenSigTimeoutMsg_Hybrid_MSG" SG_ 912 GK1_Sta_Stdhzg 912;
BA_ "GenSigTimeoutTime_TRW_ESP" SG_ 912 GK1_Sta_Stdhzg 1000;
BA_ "GenSigTimeoutMsg_TRW_ESP" SG_ 912 GK1_Sta_Stdhzg 912;
BA_ "GenSigTimeoutTime_Otto" SG_ 912 GK1_Sta_Stdhzg 1000;
BA_ "GenSigTimeoutMsg_Otto" SG_ 912 GK1_Sta_Stdhzg 912;
BA_ "GenSigSendType" SG_ 912 GK1_Sta_Stdhzg 0;
BA_ "GenSigStartValue" SG_ 912 GK1_Sta_Stdhzg 1;
BA_ "GenSigTimeoutTime_TRW_ESP" SG_ 912 GK1_SH_laeuft 1000;
BA_ "GenSigTimeoutMsg_TRW_ESP" SG_ 912 GK1_SH_laeuft 912;
BA_ "GenSigSendType" SG_ 912 GK1_SH_laeuft 0;
BA_ "GenSigTimeoutTime_TRW_ESP" SG_ 912 GK1_ParkFrontWi 1000;
BA_ "GenSigTimeoutMsg_TRW_ESP" SG_ 912 GK1_ParkFrontWi 912;
BA_ "GenSigSendType" SG_ 912 GK1_ParkFrontWi 0;
BA_ "GenSigTimeoutTime_TRW_ESP" SG_ 912 GK1_AnhKonLamp 1000;
BA_ "GenSigTimeoutMsg_TRW_ESP" SG_ 912 GK1_AnhKonLamp 912;
BA_ "GenSigSendType" SG_ 912 GK1_AnhKonLamp 0;
BA_ "GenSigTimeoutTime_TRW_ESP" SG_ 912 GK1_SH_Zusatzfkt 1000;
BA_ "GenSigTimeoutMsg_TRW_ESP" SG_ 912 GK1_SH_Zusatzfkt 912;
BA_ "GenSigSendType" SG_ 912 GK1_SH_Zusatzfkt 0;
BA_ "GenSigTimeoutTime_FLA" SG_ 912 GK1_Nebel_ein 1000;
BA_ "GenSigTimeoutMsg_FLA" SG_ 912 GK1_Nebel_ein 912;
BA_ "GenSigTimeoutTime_AFS" SG_ 912 GK1_Nebel_ein 1000;
BA_ "GenSigTimeoutMsg_AFS" SG_ 912 GK1_Nebel_ein 912;
BA_ "GenSigTimeoutTime_TRW_ESP" SG_ 912 GK1_Nebel_ein 1000;
BA_ "GenSigTimeoutMsg_TRW_ESP" SG_ 912 GK1_Nebel_ein 912;
BA_ "GenSigSendType" SG_ 912 GK1_Nebel_ein 0;
BA_ "GenSigTimeoutTime_TRW_ESP" SG_ 912 GK1_Bremslicht 1000;
BA_ "GenSigTimeoutMsg_TRW_ESP" SG_ 912 GK1_Bremslicht 912;
BA_ "GenSigSendType" SG_ 912 GK1_Bremslicht 0;
BA_ "GenSigTimeoutTime_TRW_ESP" SG_ 912 GK1_SH_Vorwaerm 1000;
BA_ "GenSigTimeoutMsg_TRW_ESP" SG_ 912 GK1_SH_Vorwaerm 912;
BA_ "GenSigSendType" SG_ 912 GK1_SH_Vorwaerm 0;
BA_ "GenSigTimeoutTime_TRW_ESP" SG_ 912 GK1_res_62 1000;
BA_ "GenSigTimeoutMsg_TRW_ESP" SG_ 912 GK1_res_62 912;
BA_ "GenSigSendType" SG_ 912 GK1_res_62 0;
BA_ "GenSigTimeoutTime_Lenkhilfe_ZF_3" SG_ 912 GK1_CharismaModus 1000;
BA_ "GenSigTimeoutMsg_Lenkhilfe_ZF_3" SG_ 912 GK1_CharismaModus 912;
BA_ "GenSigTimeoutTime_DQ" SG_ 912 GK1_CharismaModus 1000;
BA_ "GenSigTimeoutMsg_DQ" SG_ 912 GK1_CharismaModus 912;
BA_ "GenSigTimeoutTime_AG6" SG_ 912 GK1_CharismaModus 1000;
BA_ "GenSigTimeoutMsg_AG6" SG_ 912 GK1_CharismaModus 912;
BA_ "GenSigTimeoutTime_Diesel" SG_ 912 GK1_CharismaModus 1000;
BA_ "GenSigTimeoutMsg_Diesel" SG_ 912 GK1_CharismaModus 912;
BA_ "GenSigTimeoutTime_Otto" SG_ 912 GK1_CharismaModus 1000;
BA_ "GenSigTimeoutMsg_Otto" SG_ 912 GK1_CharismaModus 912;
BA_ "GenSigTimeoutTime_Lenkhilfe_ZF_2" SG_ 912 GK1_CharismaModus 1000;
BA_ "GenSigTimeoutMsg_Lenkhilfe_ZF_2" SG_ 912 GK1_CharismaModus 912;
BA_ "GenSigTimeoutTime_Lenkhilfe_APA" SG_ 912 GK1_CharismaModus 1000;
BA_ "GenSigTimeoutMsg_Lenkhilfe_APA" SG_ 912 GK1_CharismaModus 912;
BA_ "GenSigTimeoutTime_Daempfer" SG_ 912 GK1_CharismaModus 1000;
BA_ "GenSigTimeoutMsg_Daempfer" SG_ 912 GK1_CharismaModus 912;
BA_ "GenSigTimeoutTime_TRW_ESP" SG_ 912 GK1_CharismaModus 1000;
BA_ "GenSigTimeoutMsg_TRW_ESP" SG_ 912 GK1_CharismaModus 912;
BA_ "GenSigSendType" SG_ 912 GK1_CharismaModus 3;
BA_ "GenSigTimeoutTime_Lenkhilfe_ZF_3" SG_ 912 GK1_SamFktNr 1000;
BA_ "GenSigTimeoutMsg_Lenkhilfe_ZF_3" SG_ 912 GK1_SamFktNr 912;
BA_ "GenSigTimeoutTime_DQ" SG_ 912 GK1_SamFktNr 1000;
BA_ "GenSigTimeoutMsg_DQ" SG_ 912 GK1_SamFktNr 912;
BA_ "GenSigTimeoutTime_AG6" SG_ 912 GK1_SamFktNr 1000;
BA_ "GenSigTimeoutMsg_AG6" SG_ 912 GK1_SamFktNr 912;
BA_ "GenSigTimeoutTime_Otto" SG_ 912 GK1_SamFktNr 1000;
BA_ "GenSigTimeoutMsg_Otto" SG_ 912 GK1_SamFktNr 912;
BA_ "GenSigTimeoutTime_Lenkhilfe_ZF_2" SG_ 912 GK1_SamFktNr 1000;
BA_ "GenSigTimeoutMsg_Lenkhilfe_ZF_2" SG_ 912 GK1_SamFktNr 912;
BA_ "GenSigTimeoutTime_Lenkhilfe_APA" SG_ 912 GK1_SamFktNr 1000;
BA_ "GenSigTimeoutMsg_Lenkhilfe_APA" SG_ 912 GK1_SamFktNr 912;
BA_ "GenSigTimeoutTime_Daempfer" SG_ 912 GK1_SamFktNr 1000;
BA_ "GenSigTimeoutMsg_Daempfer" SG_ 912 GK1_SamFktNr 912;
BA_ "GenSigTimeoutTime_Diesel" SG_ 912 GK1_SamFktNr 1000;
BA_ "GenSigTimeoutMsg_Diesel" SG_ 912 GK1_SamFktNr 912;
BA_ "GenSigTimeoutTime_TRW_ESP" SG_ 912 GK1_SamFktNr 1000;
BA_ "GenSigTimeoutMsg_TRW_ESP" SG_ 912 GK1_SamFktNr 912;
BA_ "GenSigSendType" SG_ 912 GK1_SamFktNr 3;
BA_ "GenSigTimeoutTime_Airbag" SG_ 1490 IDT_Mux 2000;
BA_ "GenSigTimeoutMsg_Airbag" SG_ 1490 IDT_Mux 1490;
BA_ "GenSigTimeoutTime_Lenkhilfe_ZF_3" SG_ 1490 IDT_Mux 2000;
BA_ "GenSigTimeoutMsg_Lenkhilfe_ZF_3" SG_ 1490 IDT_Mux 1490;
BA_ "GenSigTimeoutTime_EPB" SG_ 1490 IDT_Mux 2000;
BA_ "GenSigTimeoutMsg_EPB" SG_ 1490 IDT_Mux 1490;
BA_ "GenSigTimeoutTime_LWS" SG_ 1490 IDT_Mux 2000;
BA_ "GenSigTimeoutMsg_LWS" SG_ 1490 IDT_Mux 1490;
BA_ "GenSigTimeoutTime_Daempfer" SG_ 1490 IDT_Mux 2000;
BA_ "GenSigTimeoutMsg_Daempfer" SG_ 1490 IDT_Mux 1490;
BA_ "GenSigTimeoutTime_Lenkhilfe_APA" SG_ 1490 IDT_Mux 2000;
BA_ "GenSigTimeoutMsg_Lenkhilfe_APA" SG_ 1490 IDT_Mux 1490;
BA_ "GenSigTimeoutTime_Magne_Ride" SG_ 1490 IDT_Mux 2000;
BA_ "GenSigTimeoutMsg_Magne_Ride" SG_ 1490 IDT_Mux 1490;
BA_ "GenSigTimeoutTime_TRW_ESP" SG_ 1490 IDT_Mux 2000;
BA_ "GenSigTimeoutMsg_TRW_ESP" SG_ 1490 IDT_Mux 1490;
BA_ "GenSigTimeoutTime_Teves_MK70_MAB" SG_ 1490 IDT_Mux 2000;
BA_ "GenSigTimeoutMsg_Teves_MK70_MAB" SG_ 1490 IDT_Mux 1490;
BA_ "GenSigTimeoutTime_Teves_MK60_ESP" SG_ 1490 IDT_Mux 2000;
BA_ "GenSigTimeoutMsg_Teves_MK60_ESP" SG_ 1490 IDT_Mux 1490;
BA_ "GenSigTimeoutTime_Lenkhilfe_ZF_2" SG_ 1490 IDT_Mux 2000;
BA_ "GenSigTimeoutMsg_Lenkhilfe_ZF_2" SG_ 1490 IDT_Mux 1490;
BA_ "GenSigSendType" SG_ 1490 IDT_Mux 0;
BA_ "GenSigTimeoutTime_TRW_ESP" SG_ 1490 IDT_Geheimnis_2 2000;
BA_ "GenSigTimeoutMsg_TRW_ESP" SG_ 1490 IDT_Geheimnis_2 1490;
BA_ "GenSigSendType" SG_ 1490 IDT_Geheimnis_2 0;
BA_ "GenSigTimeoutTime_Airbag" SG_ 1490 IDT_VIN_1 2000;
BA_ "GenSigTimeoutMsg_Airbag" SG_ 1490 IDT_VIN_1 1490;
BA_ "GenSigTimeoutTime_TRW_ESP" SG_ 1490 IDT_VIN_1 2000;
BA_ "GenSigTimeoutMsg_TRW_ESP" SG_ 1490 IDT_VIN_1 1490;
BA_ "GenSigTimeoutTime_LWS" SG_ 1490 IDT_VIN_1 2000;
BA_ "GenSigTimeoutMsg_LWS" SG_ 1490 IDT_VIN_1 1490;
BA_ "GenSigTimeoutTime_Daempfer" SG_ 1490 IDT_VIN_1 2000;
BA_ "GenSigTimeoutMsg_Daempfer" SG_ 1490 IDT_VIN_1 1490;
BA_ "GenSigTimeoutTime_Magne_Ride" SG_ 1490 IDT_VIN_1 2000;
BA_ "GenSigTimeoutMsg_Magne_Ride" SG_ 1490 IDT_VIN_1 1490;
BA_ "GenSigSendType" SG_ 1490 IDT_VIN_1 0;
BA_ "INIT" SG_ 1490 IDT_VIN_1 "const";
BA_ "GenSigTimeoutTime_TRW_ESP" SG_ 1490 IDT_Geheimnis_1 2000;
BA_ "GenSigTimeoutMsg_TRW_ESP" SG_ 1490 IDT_Geheimnis_1 1490;
BA_ "GenSigSendType" SG_ 1490 IDT_Geheimnis_1 0;
BA_ "GenSigTimeoutTime_Airbag" SG_ 1490 IDT_VIN_16 2000;
BA_ "GenSigTimeoutMsg_Airbag" SG_ 1490 IDT_VIN_16 1490;
BA_ "GenSigTimeoutTime_Lenkhilfe_ZF_3" SG_ 1490 IDT_VIN_16 2000;
BA_ "GenSigTimeoutMsg_Lenkhilfe_ZF_3" SG_ 1490 IDT_VIN_16 1490;
BA_ "GenSigTimeoutTime_EPB" SG_ 1490 IDT_VIN_16 2000;
BA_ "GenSigTimeoutMsg_EPB" SG_ 1490 IDT_VIN_16 1490;
BA_ "GenSigTimeoutTime_LWS" SG_ 1490 IDT_VIN_16 2000;
BA_ "GenSigTimeoutMsg_LWS" SG_ 1490 IDT_VIN_16 1490;
BA_ "GenSigTimeoutTime_Daempfer" SG_ 1490 IDT_VIN_16 2000;
BA_ "GenSigTimeoutMsg_Daempfer" SG_ 1490 IDT_VIN_16 1490;
BA_ "GenSigTimeoutTime_Lenkhilfe_APA" SG_ 1490 IDT_VIN_16 2000;
BA_ "GenSigTimeoutMsg_Lenkhilfe_APA" SG_ 1490 IDT_VIN_16 1490;
BA_ "GenSigTimeoutTime_Magne_Ride" SG_ 1490 IDT_VIN_16 2000;
BA_ "GenSigTimeoutMsg_Magne_Ride" SG_ 1490 IDT_VIN_16 1490;
BA_ "GenSigTimeoutTime_TRW_ESP" SG_ 1490 IDT_VIN_16 2000;
BA_ "GenSigTimeoutMsg_TRW_ESP" SG_ 1490 IDT_VIN_16 1490;
BA_ "GenSigTimeoutTime_Teves_MK70_MAB" SG_ 1490 IDT_VIN_16 2000;
BA_ "GenSigTimeoutMsg_Teves_MK70_MAB" SG_ 1490 IDT_VIN_16 1490;
BA_ "GenSigTimeoutTime_Teves_MK60_ESP" SG_ 1490 IDT_VIN_16 2000;
BA_ "GenSigTimeoutMsg_Teves_MK60_ESP" SG_ 1490 IDT_VIN_16 1490;
BA_ "GenSigTimeoutTime_Lenkhilfe_ZF_2" SG_ 1490 IDT_VIN_16 2000;
BA_ "GenSigTimeoutMsg_Lenkhilfe_ZF_2" SG_ 1490 IDT_VIN_16 1490;
BA_ "GenSigSendType" SG_ 1490 IDT_VIN_16 0;
BA_ "INIT" SG_ 1490 IDT_VIN_16 "const";
BA_ "GenSigTimeoutTime_TRW_ESP" SG_ 1490 IDT_Geheimnis_3 2000;
BA_ "GenSigTimeoutMsg_TRW_ESP" SG_ 1490 IDT_Geheimnis_3 1490;
BA_ "GenSigSendType" SG_ 1490 IDT_Geheimnis_3 0;
BA_ "GenSigTimeoutTime_Airbag" SG_ 1490 IDT_VIN_14 2000;
BA_ "GenSigTimeoutMsg_Airbag" SG_ 1490 IDT_VIN_14 1490;
BA_ "GenSigTimeoutTime_Lenkhilfe_ZF_3" SG_ 1490 IDT_VIN_14 2000;
BA_ "GenSigTimeoutMsg_Lenkhilfe_ZF_3" SG_ 1490 IDT_VIN_14 1490;
BA_ "GenSigTimeoutTime_EPB" SG_ 1490 IDT_VIN_14 2000;
BA_ "GenSigTimeoutMsg_EPB" SG_ 1490 IDT_VIN_14 1490;
BA_ "GenSigTimeoutTime_LWS" SG_ 1490 IDT_VIN_14 2000;
BA_ "GenSigTimeoutMsg_LWS" SG_ 1490 IDT_VIN_14 1490;
BA_ "GenSigTimeoutTime_Daempfer" SG_ 1490 IDT_VIN_14 2000;
BA_ "GenSigTimeoutMsg_Daempfer" SG_ 1490 IDT_VIN_14 1490;
BA_ "GenSigTimeoutTime_Lenkhilfe_APA" SG_ 1490 IDT_VIN_14 2000;
BA_ "GenSigTimeoutMsg_Lenkhilfe_APA" SG_ 1490 IDT_VIN_14 1490;
BA_ "GenSigTimeoutTime_Magne_Ride" SG_ 1490 IDT_VIN_14 2000;
BA_ "GenSigTimeoutMsg_Magne_Ride" SG_ 1490 IDT_VIN_14 1490;
BA_ "GenSigTimeoutTime_TRW_ESP" SG_ 1490 IDT_VIN_14 2000;
BA_ "GenSigTimeoutMsg_TRW_ESP" SG_ 1490 IDT_VIN_14 1490;
BA_ "GenSigTimeoutTime_Teves_MK70_MAB" SG_ 1490 IDT_VIN_14 2000;
BA_ "GenSigTimeoutMsg_Teves_MK70_MAB" SG_ 1490 IDT_VIN_14 1490;
BA_ "GenSigTimeoutTime_Teves_MK60_ESP" SG_ 1490 IDT_VIN_14 2000;
BA_ "GenSigTimeoutMsg_Teves_MK60_ESP" SG_ 1490 IDT_VIN_14 1490;
BA_ "GenSigTimeoutTime_Lenkhilfe_ZF_2" SG_ 1490 IDT_VIN_14 2000;
BA_ "GenSigTimeoutMsg_Lenkhilfe_ZF_2" SG_ 1490 IDT_VIN_14 1490;
BA_ "GenSigSendType" SG_ 1490 IDT_VIN_14 0;
BA_ "INIT" SG_ 1490 IDT_VIN_14 "const";
BA_ "GenSigTimeoutTime_Airbag" SG_ 1490 IDT_VIN_15 2000;
BA_ "GenSigTimeoutMsg_Airbag" SG_ 1490 IDT_VIN_15 1490;
BA_ "GenSigTimeoutTime_Lenkhilfe_ZF_3" SG_ 1490 IDT_VIN_15 2000;
BA_ "GenSigTimeoutMsg_Lenkhilfe_ZF_3" SG_ 1490 IDT_VIN_15 1490;
BA_ "GenSigTimeoutTime_EPB" SG_ 1490 IDT_VIN_15 2000;
BA_ "GenSigTimeoutMsg_EPB" SG_ 1490 IDT_VIN_15 1490;
BA_ "GenSigTimeoutTime_LWS" SG_ 1490 IDT_VIN_15 2000;
BA_ "GenSigTimeoutMsg_LWS" SG_ 1490 IDT_VIN_15 1490;
BA_ "GenSigTimeoutTime_Daempfer" SG_ 1490 IDT_VIN_15 2000;
BA_ "GenSigTimeoutMsg_Daempfer" SG_ 1490 IDT_VIN_15 1490;
BA_ "GenSigTimeoutTime_Lenkhilfe_APA" SG_ 1490 IDT_VIN_15 2000;
BA_ "GenSigTimeoutMsg_Lenkhilfe_APA" SG_ 1490 IDT_VIN_15 1490;
BA_ "GenSigTimeoutTime_Magne_Ride" SG_ 1490 IDT_VIN_15 2000;
BA_ "GenSigTimeoutMsg_Magne_Ride" SG_ 1490 IDT_VIN_15 1490;
BA_ "GenSigTimeoutTime_TRW_ESP" SG_ 1490 IDT_VIN_15 2000;
BA_ "GenSigTimeoutMsg_TRW_ESP" SG_ 1490 IDT_VIN_15 1490;
BA_ "GenSigTimeoutTime_Teves_MK70_MAB" SG_ 1490 IDT_VIN_15 2000;
BA_ "GenSigTimeoutMsg_Teves_MK70_MAB" SG_ 1490 IDT_VIN_15 1490;
BA_ "GenSigTimeoutTime_Teves_MK60_ESP" SG_ 1490 IDT_VIN_15 2000;
BA_ "GenSigTimeoutMsg_Teves_MK60_ESP" SG_ 1490 IDT_VIN_15 1490;
BA_ "GenSigTimeoutTime_Lenkhilfe_ZF_2" SG_ 1490 IDT_VIN_15 2000;
BA_ "GenSigTimeoutMsg_Lenkhilfe_ZF_2" SG_ 1490 IDT_VIN_15 1490;
BA_ "GenSigSendType" SG_ 1490 IDT_VIN_15 0;
BA_ "INIT" SG_ 1490 IDT_VIN_15 "const";
BA_ "GenSigTimeoutTime_TRW_ESP" SG_ 1490 IDT_Geheimnis_4 2000;
BA_ "GenSigTimeoutMsg_TRW_ESP" SG_ 1490 IDT_Geheimnis_4 1490;
BA_ "GenSigSendType" SG_ 1490 IDT_Geheimnis_4 0;
BA_ "GenSigTimeoutTime_Teves_MK60_ESP" SG_ 1490 IDT_VIN_13 2000;
BA_ "GenSigTimeoutMsg_Teves_MK60_ESP" SG_ 1490 IDT_VIN_13 1490;
BA_ "GenSigTimeoutTime_Airbag" SG_ 1490 IDT_VIN_13 2000;
BA_ "GenSigTimeoutMsg_Airbag" SG_ 1490 IDT_VIN_13 1490;
BA_ "GenSigTimeoutTime_EPB" SG_ 1490 IDT_VIN_13 2000;
BA_ "GenSigTimeoutMsg_EPB" SG_ 1490 IDT_VIN_13 1490;
BA_ "GenSigTimeoutTime_TRW_ESP" SG_ 1490 IDT_VIN_13 2000;
BA_ "GenSigTimeoutMsg_TRW_ESP" SG_ 1490 IDT_VIN_13 1490;
BA_ "GenSigTimeoutTime_LWS" SG_ 1490 IDT_VIN_13 2000;
BA_ "GenSigTimeoutMsg_LWS" SG_ 1490 IDT_VIN_13 1490;
BA_ "GenSigTimeoutTime_Daempfer" SG_ 1490 IDT_VIN_13 2000;
BA_ "GenSigTimeoutMsg_Daempfer" SG_ 1490 IDT_VIN_13 1490;
BA_ "GenSigTimeoutTime_Magne_Ride" SG_ 1490 IDT_VIN_13 2000;
BA_ "GenSigTimeoutMsg_Magne_Ride" SG_ 1490 IDT_VIN_13 1490;
BA_ "GenSigSendType" SG_ 1490 IDT_VIN_13 0;
BA_ "INIT" SG_ 1490 IDT_VIN_13 "const";
BA_ "GenSigTimeoutTime_Airbag" SG_ 1490 IDT_VIN_10 2000;
BA_ "GenSigTimeoutMsg_Airbag" SG_ 1490 IDT_VIN_10 1490;
BA_ "GenSigTimeoutTime_TRW_ESP" SG_ 1490 IDT_VIN_10 2000;
BA_ "GenSigTimeoutMsg_TRW_ESP" SG_ 1490 IDT_VIN_10 1490;
BA_ "GenSigTimeoutTime_LWS" SG_ 1490 IDT_VIN_10 2000;
BA_ "GenSigTimeoutMsg_LWS" SG_ 1490 IDT_VIN_10 1490;
BA_ "GenSigTimeoutTime_Daempfer" SG_ 1490 IDT_VIN_10 2000;
BA_ "GenSigTimeoutMsg_Daempfer" SG_ 1490 IDT_VIN_10 1490;
BA_ "GenSigTimeoutTime_Magne_Ride" SG_ 1490 IDT_VIN_10 2000;
BA_ "GenSigTimeoutMsg_Magne_Ride" SG_ 1490 IDT_VIN_10 1490;
BA_ "GenSigSendType" SG_ 1490 IDT_VIN_10 0;
BA_ "INIT" SG_ 1490 IDT_VIN_10 "const";
BA_ "GenSigTimeoutTime_Airbag" SG_ 1490 IDT_VIN_11 2000;
BA_ "GenSigTimeoutMsg_Airbag" SG_ 1490 IDT_VIN_11 1490;
BA_ "GenSigTimeoutTime_TRW_ESP" SG_ 1490 IDT_VIN_11 2000;
BA_ "GenSigTimeoutMsg_TRW_ESP" SG_ 1490 IDT_VIN_11 1490;
BA_ "GenSigTimeoutTime_LWS" SG_ 1490 IDT_VIN_11 2000;
BA_ "GenSigTimeoutMsg_LWS" SG_ 1490 IDT_VIN_11 1490;
BA_ "GenSigTimeoutTime_Daempfer" SG_ 1490 IDT_VIN_11 2000;
BA_ "GenSigTimeoutMsg_Daempfer" SG_ 1490 IDT_VIN_11 1490;
BA_ "GenSigTimeoutTime_Magne_Ride" SG_ 1490 IDT_VIN_11 2000;
BA_ "GenSigTimeoutMsg_Magne_Ride" SG_ 1490 IDT_VIN_11 1490;
BA_ "GenSigSendType" SG_ 1490 IDT_VIN_11 0;
BA_ "INIT" SG_ 1490 IDT_VIN_11 "const";
BA_ "GenSigTimeoutTime_Airbag" SG_ 1490 IDT_VIN_4 2000;
BA_ "GenSigTimeoutMsg_Airbag" SG_ 1490 IDT_VIN_4 1490;
BA_ "GenSigTimeoutTime_TRW_ESP" SG_ 1490 IDT_VIN_4 2000;
BA_ "GenSigTimeoutMsg_TRW_ESP" SG_ 1490 IDT_VIN_4 1490;
BA_ "GenSigTimeoutTime_LWS" SG_ 1490 IDT_VIN_4 2000;
BA_ "GenSigTimeoutMsg_LWS" SG_ 1490 IDT_VIN_4 1490;
BA_ "GenSigTimeoutTime_Daempfer" SG_ 1490 IDT_VIN_4 2000;
BA_ "GenSigTimeoutMsg_Daempfer" SG_ 1490 IDT_VIN_4 1490;
BA_ "GenSigTimeoutTime_Magne_Ride" SG_ 1490 IDT_VIN_4 2000;
BA_ "GenSigTimeoutMsg_Magne_Ride" SG_ 1490 IDT_VIN_4 1490;
BA_ "GenSigSendType" SG_ 1490 IDT_VIN_4 0;
BA_ "INIT" SG_ 1490 IDT_VIN_4 "const";
BA_ "GenSigTimeoutTime_Airbag" SG_ 1490 IDT_VIN_2 2000;
BA_ "GenSigTimeoutMsg_Airbag" SG_ 1490 IDT_VIN_2 1490;
BA_ "GenSigTimeoutTime_TRW_ESP" SG_ 1490 IDT_VIN_2 2000;
BA_ "GenSigTimeoutMsg_TRW_ESP" SG_ 1490 IDT_VIN_2 1490;
BA_ "GenSigTimeoutTime_LWS" SG_ 1490 IDT_VIN_2 2000;
BA_ "GenSigTimeoutMsg_LWS" SG_ 1490 IDT_VIN_2 1490;
BA_ "GenSigTimeoutTime_Daempfer" SG_ 1490 IDT_VIN_2 2000;
BA_ "GenSigTimeoutMsg_Daempfer" SG_ 1490 IDT_VIN_2 1490;
BA_ "GenSigTimeoutTime_Magne_Ride" SG_ 1490 IDT_VIN_2 2000;
BA_ "GenSigTimeoutMsg_Magne_Ride" SG_ 1490 IDT_VIN_2 1490;
BA_ "GenSigSendType" SG_ 1490 IDT_VIN_2 0;
BA_ "INIT" SG_ 1490 IDT_VIN_2 "const";
BA_ "GenSigTimeoutTime_Airbag" SG_ 1490 IDT_VIN_12 2000;
BA_ "GenSigTimeoutMsg_Airbag" SG_ 1490 IDT_VIN_12 1490;
BA_ "GenSigTimeoutTime_TRW_ESP" SG_ 1490 IDT_VIN_12 2000;
BA_ "GenSigTimeoutMsg_TRW_ESP" SG_ 1490 IDT_VIN_12 1490;
BA_ "GenSigTimeoutTime_LWS" SG_ 1490 IDT_VIN_12 2000;
BA_ "GenSigTimeoutMsg_LWS" SG_ 1490 IDT_VIN_12 1490;
BA_ "GenSigTimeoutTime_Daempfer" SG_ 1490 IDT_VIN_12 2000;
BA_ "GenSigTimeoutMsg_Daempfer" SG_ 1490 IDT_VIN_12 1490;
BA_ "GenSigTimeoutTime_Magne_Ride" SG_ 1490 IDT_VIN_12 2000;
BA_ "GenSigTimeoutMsg_Magne_Ride" SG_ 1490 IDT_VIN_12 1490;
BA_ "GenSigSendType" SG_ 1490 IDT_VIN_12 0;
BA_ "INIT" SG_ 1490 IDT_VIN_12 "const";
BA_ "GenSigTimeoutTime_Airbag" SG_ 1490 IDT_VIN_6 2000;
BA_ "GenSigTimeoutMsg_Airbag" SG_ 1490 IDT_VIN_6 1490;
BA_ "GenSigTimeoutTime_TRW_ESP" SG_ 1490 IDT_VIN_6 2000;
BA_ "GenSigTimeoutMsg_TRW_ESP" SG_ 1490 IDT_VIN_6 1490;
BA_ "GenSigTimeoutTime_LWS" SG_ 1490 IDT_VIN_6 2000;
BA_ "GenSigTimeoutMsg_LWS" SG_ 1490 IDT_VIN_6 1490;
BA_ "GenSigTimeoutTime_Daempfer" SG_ 1490 IDT_VIN_6 2000;
BA_ "GenSigTimeoutMsg_Daempfer" SG_ 1490 IDT_VIN_6 1490;
BA_ "GenSigTimeoutTime_Magne_Ride" SG_ 1490 IDT_VIN_6 2000;
BA_ "GenSigTimeoutMsg_Magne_Ride" SG_ 1490 IDT_VIN_6 1490;
BA_ "GenSigSendType" SG_ 1490 IDT_VIN_6 0;
BA_ "INIT" SG_ 1490 IDT_VIN_6 "const";
BA_ "GenSigTimeoutTime_Airbag" SG_ 1490 IDT_VIN_3 2000;
BA_ "GenSigTimeoutMsg_Airbag" SG_ 1490 IDT_VIN_3 1490;
BA_ "GenSigTimeoutTime_TRW_ESP" SG_ 1490 IDT_VIN_3 2000;
BA_ "GenSigTimeoutMsg_TRW_ESP" SG_ 1490 IDT_VIN_3 1490;
BA_ "GenSigTimeoutTime_LWS" SG_ 1490 IDT_VIN_3 2000;
BA_ "GenSigTimeoutMsg_LWS" SG_ 1490 IDT_VIN_3 1490;
BA_ "GenSigTimeoutTime_Daempfer" SG_ 1490 IDT_VIN_3 2000;
BA_ "GenSigTimeoutMsg_Daempfer" SG_ 1490 IDT_VIN_3 1490;
BA_ "GenSigTimeoutTime_Magne_Ride" SG_ 1490 IDT_VIN_3 2000;
BA_ "GenSigTimeoutMsg_Magne_Ride" SG_ 1490 IDT_VIN_3 1490;
BA_ "GenSigSendType" SG_ 1490 IDT_VIN_3 0;
BA_ "INIT" SG_ 1490 IDT_VIN_3 "const";
BA_ "GenSigTimeoutTime_Airbag" SG_ 1490 IDT_VIN_17 2000;
BA_ "GenSigTimeoutMsg_Airbag" SG_ 1490 IDT_VIN_17 1490;
BA_ "GenSigTimeoutTime_Lenkhilfe_ZF_3" SG_ 1490 IDT_VIN_17 2000;
BA_ "GenSigTimeoutMsg_Lenkhilfe_ZF_3" SG_ 1490 IDT_VIN_17 1490;
BA_ "GenSigTimeoutTime_EPB" SG_ 1490 IDT_VIN_17 2000;
BA_ "GenSigTimeoutMsg_EPB" SG_ 1490 IDT_VIN_17 1490;
BA_ "GenSigTimeoutTime_LWS" SG_ 1490 IDT_VIN_17 2000;
BA_ "GenSigTimeoutMsg_LWS" SG_ 1490 IDT_VIN_17 1490;
BA_ "GenSigTimeoutTime_Daempfer" SG_ 1490 IDT_VIN_17 2000;
BA_ "GenSigTimeoutMsg_Daempfer" SG_ 1490 IDT_VIN_17 1490;
BA_ "GenSigTimeoutTime_Lenkhilfe_APA" SG_ 1490 IDT_VIN_17 2000;
BA_ "GenSigTimeoutMsg_Lenkhilfe_APA" SG_ 1490 IDT_VIN_17 1490;
BA_ "GenSigTimeoutTime_Magne_Ride" SG_ 1490 IDT_VIN_17 2000;
BA_ "GenSigTimeoutMsg_Magne_Ride" SG_ 1490 IDT_VIN_17 1490;
BA_ "GenSigTimeoutTime_TRW_ESP" SG_ 1490 IDT_VIN_17 2000;
BA_ "GenSigTimeoutMsg_TRW_ESP" SG_ 1490 IDT_VIN_17 1490;
BA_ "GenSigTimeoutTime_Teves_MK70_MAB" SG_ 1490 IDT_VIN_17 2000;
BA_ "GenSigTimeoutMsg_Teves_MK70_MAB" SG_ 1490 IDT_VIN_17 1490;
BA_ "GenSigTimeoutTime_Teves_MK60_ESP" SG_ 1490 IDT_VIN_17 2000;
BA_ "GenSigTimeoutMsg_Teves_MK60_ESP" SG_ 1490 IDT_VIN_17 1490;
BA_ "GenSigTimeoutTime_Lenkhilfe_ZF_2" SG_ 1490 IDT_VIN_17 2000;
BA_ "GenSigTimeoutMsg_Lenkhilfe_ZF_2" SG_ 1490 IDT_VIN_17 1490;
BA_ "GenSigSendType" SG_ 1490 IDT_VIN_17 0;
BA_ "INIT" SG_ 1490 IDT_VIN_17 "const";
BA_ "GenSigTimeoutTime_Airbag" SG_ 1490 IDT_VIN_7 2000;
BA_ "GenSigTimeoutMsg_Airbag" SG_ 1490 IDT_VIN_7 1490;
BA_ "GenSigTimeoutTime_EPB" SG_ 1490 IDT_VIN_7 2000;
BA_ "GenSigTimeoutMsg_EPB" SG_ 1490 IDT_VIN_7 1490;
BA_ "GenSigTimeoutTime_TRW_ESP" SG_ 1490 IDT_VIN_7 2000;
BA_ "GenSigTimeoutMsg_TRW_ESP" SG_ 1490 IDT_VIN_7 1490;
BA_ "GenSigTimeoutTime_LWS" SG_ 1490 IDT_VIN_7 2000;
BA_ "GenSigTimeoutMsg_LWS" SG_ 1490 IDT_VIN_7 1490;
BA_ "GenSigTimeoutTime_Daempfer" SG_ 1490 IDT_VIN_7 2000;
BA_ "GenSigTimeoutMsg_Daempfer" SG_ 1490 IDT_VIN_7 1490;
BA_ "GenSigTimeoutTime_Magne_Ride" SG_ 1490 IDT_VIN_7 2000;
BA_ "GenSigTimeoutMsg_Magne_Ride" SG_ 1490 IDT_VIN_7 1490;
BA_ "GenSigTimeoutTime_Teves_MK60_ESP" SG_ 1490 IDT_VIN_7 2000;
BA_ "GenSigTimeoutMsg_Teves_MK60_ESP" SG_ 1490 IDT_VIN_7 1490;
BA_ "GenSigSendType" SG_ 1490 IDT_VIN_7 0;
BA_ "INIT" SG_ 1490 IDT_VIN_7 "const";
BA_ "GenSigTimeoutTime_Airbag" SG_ 1490 IDT_VIN_9 2000;
BA_ "GenSigTimeoutMsg_Airbag" SG_ 1490 IDT_VIN_9 1490;
BA_ "GenSigTimeoutTime_TRW_ESP" SG_ 1490 IDT_VIN_9 2000;
BA_ "GenSigTimeoutMsg_TRW_ESP" SG_ 1490 IDT_VIN_9 1490;
BA_ "GenSigTimeoutTime_LWS" SG_ 1490 IDT_VIN_9 2000;
BA_ "GenSigTimeoutMsg_LWS" SG_ 1490 IDT_VIN_9 1490;
BA_ "GenSigTimeoutTime_Daempfer" SG_ 1490 IDT_VIN_9 2000;
BA_ "GenSigTimeoutMsg_Daempfer" SG_ 1490 IDT_VIN_9 1490;
BA_ "GenSigTimeoutTime_Magne_Ride" SG_ 1490 IDT_VIN_9 2000;
BA_ "GenSigTimeoutMsg_Magne_Ride" SG_ 1490 IDT_VIN_9 1490;
BA_ "GenSigSendType" SG_ 1490 IDT_VIN_9 0;
BA_ "INIT" SG_ 1490 IDT_VIN_9 "const";
BA_ "GenSigTimeoutTime_Airbag" SG_ 1490 IDT_VIN_5 2000;
BA_ "GenSigTimeoutMsg_Airbag" SG_ 1490 IDT_VIN_5 1490;
BA_ "GenSigTimeoutTime_TRW_ESP" SG_ 1490 IDT_VIN_5 2000;
BA_ "GenSigTimeoutMsg_TRW_ESP" SG_ 1490 IDT_VIN_5 1490;
BA_ "GenSigTimeoutTime_LWS" SG_ 1490 IDT_VIN_5 2000;
BA_ "GenSigTimeoutMsg_LWS" SG_ 1490 IDT_VIN_5 1490;
BA_ "GenSigTimeoutTime_Daempfer" SG_ 1490 IDT_VIN_5 2000;
BA_ "GenSigTimeoutMsg_Daempfer" SG_ 1490 IDT_VIN_5 1490;
BA_ "GenSigTimeoutTime_Magne_Ride" SG_ 1490 IDT_VIN_5 2000;
BA_ "GenSigTimeoutMsg_Magne_Ride" SG_ 1490 IDT_VIN_5 1490;
BA_ "GenSigSendType" SG_ 1490 IDT_VIN_5 0;
BA_ "INIT" SG_ 1490 IDT_VIN_5 "const";
BA_ "GenSigTimeoutTime_Airbag" SG_ 1490 IDT_VIN_8 2000;
BA_ "GenSigTimeoutMsg_Airbag" SG_ 1490 IDT_VIN_8 1490;
BA_ "GenSigTimeoutTime_EPB" SG_ 1490 IDT_VIN_8 2000;
BA_ "GenSigTimeoutMsg_EPB" SG_ 1490 IDT_VIN_8 1490;
BA_ "GenSigTimeoutTime_TRW_ESP" SG_ 1490 IDT_VIN_8 2000;
BA_ "GenSigTimeoutMsg_TRW_ESP" SG_ 1490 IDT_VIN_8 1490;
BA_ "GenSigTimeoutTime_LWS" SG_ 1490 IDT_VIN_8 2000;
BA_ "GenSigTimeoutMsg_LWS" SG_ 1490 IDT_VIN_8 1490;
BA_ "GenSigTimeoutTime_Daempfer" SG_ 1490 IDT_VIN_8 2000;
BA_ "GenSigTimeoutMsg_Daempfer" SG_ 1490 IDT_VIN_8 1490;
BA_ "GenSigTimeoutTime_Magne_Ride" SG_ 1490 IDT_VIN_8 2000;
BA_ "GenSigTimeoutMsg_Magne_Ride" SG_ 1490 IDT_VIN_8 1490;
BA_ "GenSigTimeoutTime_Teves_MK60_ESP" SG_ 1490 IDT_VIN_8 2000;
BA_ "GenSigTimeoutMsg_Teves_MK60_ESP" SG_ 1490 IDT_VIN_8 1490;
BA_ "GenSigSendType" SG_ 1490 IDT_VIN_8 0;
BA_ "INIT" SG_ 1490 IDT_VIN_8 "const";
BA_ "GenSigTimeoutTime_TRW_ESP" SG_ 1490 IDT_res2 2000;
BA_ "GenSigTimeoutMsg_TRW_ESP" SG_ 1490 IDT_res2 1490;
BA_ "GenSigSendType" SG_ 1490 IDT_res2 0;
BA_ "GenSigTimeoutTime_TRW_ESP" SG_ 1490 IDT_res3 2000;
BA_ "GenSigTimeoutMsg_TRW_ESP" SG_ 1490 IDT_res3 1490;
BA_ "GenSigSendType" SG_ 1490 IDT_res3 0;
BA_ "GenSigTimeoutTime_TRW_ESP" SG_ 1490 IDT_res7 2000;
BA_ "GenSigTimeoutMsg_TRW_ESP" SG_ 1490 IDT_res7 1490;
BA_ "GenSigSendType" SG_ 1490 IDT_res7 0;
BA_ "GenSigTimeoutTime_TRW_ESP" SG_ 1490 IDT_res5 2000;
BA_ "GenSigTimeoutMsg_TRW_ESP" SG_ 1490 IDT_res5 1490;
BA_ "GenSigSendType" SG_ 1490 IDT_res5 0;
BA_ "GenSigTimeoutTime_TRW_ESP" SG_ 1490 IDT_res6 2000;
BA_ "GenSigTimeoutMsg_TRW_ESP" SG_ 1490 IDT_res6 1490;
BA_ "GenSigSendType" SG_ 1490 IDT_res6 0;
BA_ "GenSigTimeoutTime_TRW_ESP" SG_ 1490 IDT_res4 2000;
BA_ "GenSigTimeoutMsg_TRW_ESP" SG_ 1490 IDT_res4 1490;
BA_ "GenSigSendType" SG_ 1490 IDT_res4 0;
BA_ "GenSigTimeoutTime_ACC_Lidar" SG_ 906 GRA_Checksum 500;
BA_ "GenSigTimeoutMsg_ACC_Lidar" SG_ 906 GRA_Checksum 906;
BA_ "GenSigTimeoutTime_Hybrid_MSG" SG_ 906 GRA_Checksum 500;
BA_ "GenSigTimeoutMsg_Hybrid_MSG" SG_ 906 GRA_Checksum 906;
BA_ "GenSigTimeoutTime_ACC_Radar" SG_ 906 GRA_Checksum 500;
BA_ "GenSigTimeoutMsg_ACC_Radar" SG_ 906 GRA_Checksum 906;
BA_ "GenSigTimeoutTime_Otto" SG_ 906 GRA_Checksum 500;
BA_ "GenSigTimeoutMsg_Otto" SG_ 906 GRA_Checksum 906;
BA_ "GenSigTimeoutTime_Diesel" SG_ 906 GRA_Checksum 500;
BA_ "GenSigTimeoutMsg_Diesel" SG_ 906 GRA_Checksum 906;
BA_ "GenSigSendType" SG_ 906 GRA_Checksum 0;
BA_ "INIT" SG_ 906 GRA_Checksum "CHK";
BA_ "GenSigTimeoutTime_ACC_Lidar" SG_ 906 GRA_Kodierinfo 500;
BA_ "GenSigTimeoutMsg_ACC_Lidar" SG_ 906 GRA_Kodierinfo 906;
BA_ "GenSigTimeoutTime_ACC_Radar" SG_ 906 GRA_Kodierinfo 500;
BA_ "GenSigTimeoutMsg_ACC_Radar" SG_ 906 GRA_Kodierinfo 906;
BA_ "GenSigTimeoutTime_Diesel" SG_ 906 GRA_Kodierinfo 500;
BA_ "GenSigTimeoutMsg_Diesel" SG_ 906 GRA_Kodierinfo 906;
BA_ "GenSigSendType" SG_ 906 GRA_Kodierinfo 0;
BA_ "INIT" SG_ 906 GRA_Kodierinfo "const";
BA_ "GenSigTimeoutTime_ACC_Lidar" SG_ 906 GRA_Hauptschalt 500;
BA_ "GenSigTimeoutMsg_ACC_Lidar" SG_ 906 GRA_Hauptschalt 906;
BA_ "GenSigTimeoutTime_Hybrid_MSG" SG_ 906 GRA_Hauptschalt 500;
BA_ "GenSigTimeoutMsg_Hybrid_MSG" SG_ 906 GRA_Hauptschalt 906;
BA_ "GenSigTimeoutTime_ACC_Radar" SG_ 906 GRA_Hauptschalt 500;
BA_ "GenSigTimeoutMsg_ACC_Radar" SG_ 906 GRA_Hauptschalt 906;
BA_ "GenSigTimeoutTime_Otto" SG_ 906 GRA_Hauptschalt 500;
BA_ "GenSigTimeoutMsg_Otto" SG_ 906 GRA_Hauptschalt 906;
BA_ "GenSigTimeoutTime_Diesel" SG_ 906 GRA_Hauptschalt 500;
BA_ "GenSigTimeoutMsg_Diesel" SG_ 906 GRA_Hauptschalt 906;
BA_ "GenSigSendType" SG_ 906 GRA_Hauptschalt 0;
BA_ "GenSigTimeoutTime_ACC_Lidar" SG_ 906 GRA_Neu_Zaehler 500;
BA_ "GenSigTimeoutMsg_ACC_Lidar" SG_ 906 GRA_Neu_Zaehler 906;
BA_ "GenSigTimeoutTime_Hybrid_MSG" SG_ 906 GRA_Neu_Zaehler 500;
BA_ "GenSigTimeoutMsg_Hybrid_MSG" SG_ 906 GRA_Neu_Zaehler 906;
BA_ "GenSigTimeoutTime_ACC_Radar" SG_ 906 GRA_Neu_Zaehler 500;
BA_ "GenSigTimeoutMsg_ACC_Radar" SG_ 906 GRA_Neu_Zaehler 906;
BA_ "GenSigTimeoutTime_Otto" SG_ 906 GRA_Neu_Zaehler 500;
BA_ "GenSigTimeoutMsg_Otto" SG_ 906 GRA_Neu_Zaehler 906;
BA_ "GenSigTimeoutTime_Diesel" SG_ 906 GRA_Neu_Zaehler 500;
BA_ "GenSigTimeoutMsg_Diesel" SG_ 906 GRA_Neu_Zaehler 906;
BA_ "GenSigSendType" SG_ 906 GRA_Neu_Zaehler 0;
BA_ "GenSigTimeoutTime_ACC_Lidar" SG_ 906 GRA_Sender 500;
BA_ "GenSigTimeoutMsg_ACC_Lidar" SG_ 906 GRA_Sender 906;
BA_ "GenSigTimeoutTime_Hybrid_MSG" SG_ 906 GRA_Sender 500;
BA_ "GenSigTimeoutMsg_Hybrid_MSG" SG_ 906 GRA_Sender 906;
BA_ "GenSigTimeoutTime_ACC_Radar" SG_ 906 GRA_Sender 500;
BA_ "GenSigTimeoutMsg_ACC_Radar" SG_ 906 GRA_Sender 906;
BA_ "GenSigTimeoutTime_Otto" SG_ 906 GRA_Sender 500;
BA_ "GenSigTimeoutMsg_Otto" SG_ 906 GRA_Sender 906;
BA_ "GenSigTimeoutTime_Diesel" SG_ 906 GRA_Sender 500;
BA_ "GenSigTimeoutMsg_Diesel" SG_ 906 GRA_Sender 906;
BA_ "GenSigSendType" SG_ 906 GRA_Sender 0;
BA_ "INIT" SG_ 906 GRA_Sender "const";
BA_ "GenSigSendType" SG_ 906 GRA_Sta_Limiter 0;
BA_ "GenSigSendType" SG_ 906 GRA_Sportschalter 0;
BA_ "GenSigTimeoutTime_ACC_Lidar" SG_ 906 GRA_Abbrechen 500;
BA_ "GenSigTimeoutMsg_ACC_Lidar" SG_ 906 GRA_Abbrechen 906;
BA_ "GenSigTimeoutTime_Hybrid_MSG" SG_ 906 GRA_Abbrechen 500;
BA_ "GenSigTimeoutMsg_Hybrid_MSG" SG_ 906 GRA_Abbrechen 906;
BA_ "GenSigTimeoutTime_ACC_Radar" SG_ 906 GRA_Abbrechen 500;
BA_ "GenSigTimeoutMsg_ACC_Radar" SG_ 906 GRA_Abbrechen 906;
BA_ "GenSigTimeoutTime_Otto" SG_ 906 GRA_Abbrechen 500;
BA_ "GenSigTimeoutMsg_Otto" SG_ 906 GRA_Abbrechen 906;
BA_ "GenSigTimeoutTime_Diesel" SG_ 906 GRA_Abbrechen 500;
BA_ "GenSigTimeoutMsg_Diesel" SG_ 906 GRA_Abbrechen 906;
BA_ "GenSigSendType" SG_ 906 GRA_Abbrechen 0;
BA_ "GenSigTimeoutTime_ACC_Lidar" SG_ 906 GRA_Down_kurz 500;
BA_ "GenSigTimeoutMsg_ACC_Lidar" SG_ 906 GRA_Down_kurz 906;
BA_ "GenSigTimeoutTime_Hybrid_MSG" SG_ 906 GRA_Down_kurz 500;
BA_ "GenSigTimeoutMsg_Hybrid_MSG" SG_ 906 GRA_Down_kurz 906;
BA_ "GenSigTimeoutTime_ACC_Radar" SG_ 906 GRA_Down_kurz 500;
BA_ "GenSigTimeoutMsg_ACC_Radar" SG_ 906 GRA_Down_kurz 906;
BA_ "GenSigTimeoutTime_Otto" SG_ 906 GRA_Down_kurz 500;
BA_ "GenSigTimeoutMsg_Otto" SG_ 906 GRA_Down_kurz 906;
BA_ "GenSigTimeoutTime_Diesel" SG_ 906 GRA_Down_kurz 500;
BA_ "GenSigTimeoutMsg_Diesel" SG_ 906 GRA_Down_kurz 906;
BA_ "GenSigSendType" SG_ 906 GRA_Down_kurz 0;
BA_ "GenSigTimeoutTime_AG6" SG_ 906 GRA_Fehler_Tip 500;
BA_ "GenSigTimeoutMsg_AG6" SG_ 906 GRA_Fehler_Tip 906;
BA_ "GenSigSendType" SG_ 906 GRA_Fehler_Tip 0;
BA_ "GenSigTimeoutTime_ACC_Lidar" SG_ 906 GRA_Up_kurz 500;
BA_ "GenSigTimeoutMsg_ACC_Lidar" SG_ 906 GRA_Up_kurz 906;
BA_ "GenSigTimeoutTime_Hybrid_MSG" SG_ 906 GRA_Up_kurz 500;
BA_ "GenSigTimeoutMsg_Hybrid_MSG" SG_ 906 GRA_Up_kurz 906;
BA_ "GenSigTimeoutTime_ACC_Radar" SG_ 906 GRA_Up_kurz 500;
BA_ "GenSigTimeoutMsg_ACC_Radar" SG_ 906 GRA_Up_kurz 906;
BA_ "GenSigTimeoutTime_Otto" SG_ 906 GRA_Up_kurz 500;
BA_ "GenSigTimeoutMsg_Otto" SG_ 906 GRA_Up_kurz 906;
BA_ "GenSigTimeoutTime_Diesel" SG_ 906 GRA_Up_kurz 500;
BA_ "GenSigTimeoutMsg_Diesel" SG_ 906 GRA_Up_kurz 906;
BA_ "GenSigSendType" SG_ 906 GRA_Up_kurz 0;
BA_ "GenSigTimeoutTime_ACC_Lidar" SG_ 906 GRA_Up_lang 500;
BA_ "GenSigTimeoutMsg_ACC_Lidar" SG_ 906 GRA_Up_lang 906;
BA_ "GenSigTimeoutTime_Hybrid_MSG" SG_ 906 GRA_Up_lang 500;
BA_ "GenSigTimeoutMsg_Hybrid_MSG" SG_ 906 GRA_Up_lang 906;
BA_ "GenSigTimeoutTime_ACC_Radar" SG_ 906 GRA_Up_lang 500;
BA_ "GenSigTimeoutMsg_ACC_Radar" SG_ 906 GRA_Up_lang 906;
BA_ "GenSigTimeoutTime_Otto" SG_ 906 GRA_Up_lang 500;
BA_ "GenSigTimeoutMsg_Otto" SG_ 906 GRA_Up_lang 906;
BA_ "GenSigTimeoutTime_Diesel" SG_ 906 GRA_Up_lang 500;
BA_ "GenSigTimeoutMsg_Diesel" SG_ 906 GRA_Up_lang 906;
BA_ "GenSigSendType" SG_ 906 GRA_Up_lang 0;
BA_ "GenSigTimeoutTime_ACC_Lidar" SG_ 906 GRA_Down_lang 500;
BA_ "GenSigTimeoutMsg_ACC_Lidar" SG_ 906 GRA_Down_lang 906;
BA_ "GenSigTimeoutTime_Hybrid_MSG" SG_ 906 GRA_Down_lang 500;
BA_ "GenSigTimeoutMsg_Hybrid_MSG" SG_ 906 GRA_Down_lang 906;
BA_ "GenSigTimeoutTime_ACC_Radar" SG_ 906 GRA_Down_lang 500;
BA_ "GenSigTimeoutMsg_ACC_Radar" SG_ 906 GRA_Down_lang 906;
BA_ "GenSigTimeoutTime_Otto" SG_ 906 GRA_Down_lang 500;
BA_ "GenSigTimeoutMsg_Otto" SG_ 906 GRA_Down_lang 906;
BA_ "GenSigTimeoutTime_Diesel" SG_ 906 GRA_Down_lang 500;
BA_ "GenSigTimeoutMsg_Diesel" SG_ 906 GRA_Down_lang 906;
BA_ "GenSigSendType" SG_ 906 GRA_Down_lang 0;
BA_ "GenSigTimeoutTime_ACC_Lidar" SG_ 906 GRA_Neu_Setzen 500;
BA_ "GenSigTimeoutMsg_ACC_Lidar" SG_ 906 GRA_Neu_Setzen 906;
BA_ "GenSigTimeoutTime_Hybrid_DQ200" SG_ 906 GRA_Neu_Setzen 500;
BA_ "GenSigTimeoutMsg_Hybrid_DQ200" SG_ 906 GRA_Neu_Setzen 906;
BA_ "GenSigTimeoutTime_Hybrid_MSG" SG_ 906 GRA_Neu_Setzen 500;
BA_ "GenSigTimeoutMsg_Hybrid_MSG" SG_ 906 GRA_Neu_Setzen 906;
BA_ "GenSigTimeoutTime_ACC_Radar" SG_ 906 GRA_Neu_Setzen 500;
BA_ "GenSigTimeoutMsg_ACC_Radar" SG_ 906 GRA_Neu_Setzen 906;
BA_ "GenSigTimeoutTime_DQ" SG_ 906 GRA_Neu_Setzen 500;
BA_ "GenSigTimeoutMsg_DQ" SG_ 906 GRA_Neu_Setzen 906;
BA_ "GenSigTimeoutTime_Otto" SG_ 906 GRA_Neu_Setzen 500;
BA_ "GenSigTimeoutMsg_Otto" SG_ 906 GRA_Neu_Setzen 906;
BA_ "GenSigTimeoutTime_Diesel" SG_ 906 GRA_Neu_Setzen 500;
BA_ "GenSigTimeoutMsg_Diesel" SG_ 906 GRA_Neu_Setzen 906;
BA_ "GenSigSendType" SG_ 906 GRA_Neu_Setzen 0;
BA_ "GenSigTimeoutTime_Selespeed" SG_ 906 GRA_Tip_Down 500;
BA_ "GenSigTimeoutMsg_Selespeed" SG_ 906 GRA_Tip_Down 906;
BA_ "GenSigTimeoutTime_Hybrid_DQ200" SG_ 906 GRA_Tip_Down 500;
BA_ "GenSigTimeoutMsg_Hybrid_DQ200" SG_ 906 GRA_Tip_Down 906;
BA_ "GenSigTimeoutTime_DQ" SG_ 906 GRA_Tip_Down 500;
BA_ "GenSigTimeoutMsg_DQ" SG_ 906 GRA_Tip_Down 906;
BA_ "GenSigTimeoutTime_AG6" SG_ 906 GRA_Tip_Down 500;
BA_ "GenSigTimeoutMsg_AG6" SG_ 906 GRA_Tip_Down 906;
BA_ "GenSigSendType" SG_ 906 GRA_Tip_Down 0;
BA_ "GenSigTimeoutTime_ACC_Lidar" SG_ 906 GRA_Recall 500;
BA_ "GenSigTimeoutMsg_ACC_Lidar" SG_ 906 GRA_Recall 906;
BA_ "GenSigTimeoutTime_Hybrid_DQ200" SG_ 906 GRA_Recall 500;
BA_ "GenSigTimeoutMsg_Hybrid_DQ200" SG_ 906 GRA_Recall 906;
BA_ "GenSigTimeoutTime_Hybrid_MSG" SG_ 906 GRA_Recall 500;
BA_ "GenSigTimeoutMsg_Hybrid_MSG" SG_ 906 GRA_Recall 906;
BA_ "GenSigTimeoutTime_ACC_Radar" SG_ 906 GRA_Recall 500;
BA_ "GenSigTimeoutMsg_ACC_Radar" SG_ 906 GRA_Recall 906;
BA_ "GenSigTimeoutTime_DQ" SG_ 906 GRA_Recall 500;
BA_ "GenSigTimeoutMsg_DQ" SG_ 906 GRA_Recall 906;
BA_ "GenSigTimeoutTime_Otto" SG_ 906 GRA_Recall 500;
BA_ "GenSigTimeoutMsg_Otto" SG_ 906 GRA_Recall 906;
BA_ "GenSigTimeoutTime_Diesel" SG_ 906 GRA_Recall 500;
BA_ "GenSigTimeoutMsg_Diesel" SG_ 906 GRA_Recall 906;
BA_ "GenSigSendType" SG_ 906 GRA_Recall 0;
BA_ "GenSigTimeoutTime_Selespeed" SG_ 906 GRA_Tip_Up 500;
BA_ "GenSigTimeoutMsg_Selespeed" SG_ 906 GRA_Tip_Up 906;
BA_ "GenSigTimeoutTime_Hybrid_DQ200" SG_ 906 GRA_Tip_Up 500;
BA_ "GenSigTimeoutMsg_Hybrid_DQ200" SG_ 906 GRA_Tip_Up 906;
BA_ "GenSigTimeoutTime_DQ" SG_ 906 GRA_Tip_Up 500;
BA_ "GenSigTimeoutMsg_DQ" SG_ 906 GRA_Tip_Up 906;
BA_ "GenSigTimeoutTime_AG6" SG_ 906 GRA_Tip_Up 500;
BA_ "GenSigTimeoutMsg_AG6" SG_ 906 GRA_Tip_Up 906;
BA_ "GenSigSendType" SG_ 906 GRA_Tip_Up 0;
BA_ "GenSigTimeoutTime_ACC_Lidar" SG_ 906 GRA_Zeitluecke 500;
BA_ "GenSigTimeoutMsg_ACC_Lidar" SG_ 906 GRA_Zeitluecke 906;
BA_ "GenSigTimeoutTime_ACC_Radar" SG_ 906 GRA_Zeitluecke 500;
BA_ "GenSigTimeoutMsg_ACC_Radar" SG_ 906 GRA_Zeitluecke 906;
BA_ "GenSigSendType" SG_ 906 GRA_Zeitluecke 0;
BA_ "GenSigTimeoutTime_ACC_Lidar" SG_ 906 GRA_Typ_Hauptschalt 500;
BA_ "GenSigTimeoutMsg_ACC_Lidar" SG_ 906 GRA_Typ_Hauptschalt 906;
BA_ "GenSigTimeoutTime_Hybrid_MSG" SG_ 906 GRA_Typ_Hauptschalt 500;
BA_ "GenSigTimeoutMsg_Hybrid_MSG" SG_ 906 GRA_Typ_Hauptschalt 906;
BA_ "GenSigTimeoutTime_ACC_Radar" SG_ 906 GRA_Typ_Hauptschalt 500;
BA_ "GenSigTimeoutMsg_ACC_Radar" SG_ 906 GRA_Typ_Hauptschalt 906;
BA_ "GenSigTimeoutTime_Otto" SG_ 906 GRA_Typ_Hauptschalt 500;
BA_ "GenSigTimeoutMsg_Otto" SG_ 906 GRA_Typ_Hauptschalt 906;
BA_ "GenSigTimeoutTime_Diesel" SG_ 906 GRA_Typ_Hauptschalt 500;
BA_ "GenSigTimeoutMsg_Diesel" SG_ 906 GRA_Typ_Hauptschalt 906;
BA_ "GenSigSendType" SG_ 906 GRA_Typ_Hauptschalt 0;
BA_ "INIT" SG_ 906 GRA_Typ_Hauptschalt "const";
BA_ "GenSigTimeoutTime_ACC_Lidar" SG_ 906 GRA_Fehler_Bed 500;
BA_ "GenSigTimeoutMsg_ACC_Lidar" SG_ 906 GRA_Fehler_Bed 906;
BA_ "GenSigTimeoutTime_Otto" SG_ 906 GRA_Fehler_Bed 500;
BA_ "GenSigTimeoutMsg_Otto" SG_ 906 GRA_Fehler_Bed 906;
BA_ "GenSigTimeoutTime_Hybrid_MSG" SG_ 906 GRA_Fehler_Bed 500;
BA_ "GenSigTimeoutMsg_Hybrid_MSG" SG_ 906 GRA_Fehler_Bed 906;
BA_ "GenSigTimeoutTime_ACC_Radar" SG_ 906 GRA_Fehler_Bed 500;
BA_ "GenSigTimeoutMsg_ACC_Radar" SG_ 906 GRA_Fehler_Bed 906;
BA_ "GenSigTimeoutTime_Diesel" SG_ 906 GRA_Fehler_Bed 500;
BA_ "GenSigTimeoutMsg_Diesel" SG_ 906 GRA_Fehler_Bed 906;
BA_ "GenSigSendType" SG_ 906 GRA_Fehler_Bed 0;
VAL_ 1164 HS1_Gang 7 "nicht_bekannt" 3 "Rueckwaertsgang" 2 "Hoechster_Gang" 1 "Gang_1" 0 "Triebstrang_offen" ;
VAL_ 1164 HS1_Drehz_Grenze 4 "Obere_Komfortgrenze" 3 "Obere_Abschaltgrenze" 2 "untere_Komfortgrenze" 1 "untere_Abschaltgrenze" 0 "kein_Grenzwert" ;
VAL_ 1423 M12_SCR_Anz_Motorstarts 15 "keine_Einschraenkung" 14 "Fahrbarkeitseinschraenkung" ;
VAL_ 1423 M12_SCR_Reichweite 32767 "keine_Anzeige" ;
VAL_ 1423 M12_SCR_Warnstufe_1 1 "Warnstufe_1" ;
VAL_ 1423 M12_SCR_Warnstufe_2 1 "Warnstufe_2" ;
VAL_ 1423 M12_Luftfilter_Lampe 1 "Lampe_ein" 0 "Lampe_aus" ;
VAL_ 1423 M12_Akustik 3 "Akustik_bei_Hinweis" 2 "Akustik_2" 1 "Akustik_1" 0 "keine_Akustik" ;
VAL_ 1423 M12_SCR_Systemfehler 1 "SCR_Systemfehler_aktiv" ;
VAL_ 1423 M12_SCR_Text 7 "Hinweis_SysFehler" 6 "Sysfehler_2" 5 "SysFehler_1" 3 "Hinweis_Fuellstand" 2 "Warntext_2" 1 "Warntext_1" 0 "kein_Text" ;
VAL_ 1423 M12_SCR_Inducement 1 "Reduced_Drivability_Strategie" 0 "Restart_Strategie" ;
VAL_ 1823 MSI_KD_Fehler 1 "Fehlerspeichereintrag" 0 "kein_Fehlerspeichereintrag" ;
VAL_ 1800 MC1_Anz_Betrieb 1 "Gasbetrieb" 0 "Benzinbetrieb" ;
VAL_ 1800 MC1_Schalter 1 "Gasbetrieb" 0 "Benzin_od_Schalter_nicht_verb" ;
VAL_ 1800 MC1_Fuellungsgrad 255 "Fehler" ;
VAL_ 1800 MC1_akt_Betrieb 1 "Gasbetrieb" 0 "Benzinbetrieb" ;
VAL_ 1800 MC1_Ueb_Verbr 1 "mind_1_Ueberlauf" 0 "kein_Ueberlauf" ;
VAL_ 800 KO1_Oeldruck 1 "groesser_Schwellwert" 0 "kleiner_Schwellwert" ;
VAL_ 800 KO1_SleepInd 1 "Sleep_bereit" 0 "Bus_benoetigt" ;
VAL_ 800 KO1_Sta_Tank 1 "Tankfuellst_n_iO" 0 "Tankfuellst_iO" ;
VAL_ 800 KO1_Kuehlmittel 1 "Mangel" 0 "iO" ;
VAL_ 800 KO1_Sta_Oeldr 1 "Warnung" 0 "iO" ;
VAL_ 800 KO1_Warn_Tank 1 "Lampe_ein" 0 "Lampe_aus" ;
VAL_ 800 KO1_La_Ladekon 1 "Lampe_ein" 0 "Lampe_aus" ;
VAL_ 800 KO1_Vorgluehen 1 "Lampe_ein" 0 "Lampe_aus" ;
VAL_ 800 KO1_Wakeup_Komfort 1 "Wake_Up_Komfort" 0 "keine_Anforderung" ;
VAL_ 800 KO1_Tankinhalt 127 "Fehler" ;
VAL_ 800 KO1_Zeitluecke 7 "Zeitluecke_7" 6 "Zeitluecke_6" 5 "Zeitluecke_5" 4 "Zeitluecke_4" 3 "Zeitluecke_3" 2 "Zeitluecke_2" 1 "Zeitluecke_1" 0 "keine_Anzeige" ;
VAL_ 800 KO1_Tankstop 1 "Tankstop_erkannt" ;
VAL_ 800 KO1_OBD_Tank 1 "Tankwarnung" 0 "iO" ;
VAL_ 800 KO1_Quelle_kmh 1 "ABS_Signale" 0 "Tachogeber" ;
VAL_ 800 KO1_ACC_Inkons 1 "Fehler" 0 "iO" ;
VAL_ 800 KO1_kmh_mph 1 "miles_hour" 0 "km_h" ;
VAL_ 800 KO1_ACC_AnzFhl 1 "ACC_Anzeige_defekt" 0 "kein_Fehler" ;
VAL_ 800 KO1_angez_kmh 1020 "Fehler" ;
VAL_ 800 KO1_Bremsinfo 1 "Bremsfluessigkeitswarnung" 0 "iO" ;
VAL_ 800 KO1_Stellglieder 1 "ja" 0 "nein" ;
VAL_ 800 KO1_ABS_Lampe 1 "Lampe_ein" 0 "Lampe_aus" ;
VAL_ 800 KO1_LDW_AnzFeh 1 "Fehler" 0 "i_O" ;
VAL_ 800 KO1_Airbag_Lampe 1 "Lampe_ein" 0 "Lampe_aus" ;
VAL_ 800 KO1_ASRESP_Lampe 1 "Lampe_ein" 0 "Lampe_aus" ;
VAL_ 800 KO1_Lenkh_Lampe 1 "Lampe_ein" 0 "Lampe_aus" ;
VAL_ 800 KO1_SILA_gueltig 1 "gueltig" 0 "ungueltig" ;
VAL_ 800 KO1_Handbremse 1 "angezogen" 0 "nicht_angezogen" ;
VAL_ 800 KO1_Brems_Lampe 1 "Lampe_ein" 0 "Lampe_aus" ;
VAL_ 1306 TOG_Fuellstand_1 2047 "unguelt_Wert_oder_Bereichsueberl" 1 "Init" 0 "kein_Wert" ;
VAL_ 1306 TOG_Sensorfehler 1 "Fehler" 0 "Sensor_iO" ;
VAL_ 1306 TOG_OelwarnUeber 1 "Schwelle_ueberschritten" 0 "Schwelle_nicht_ueberschritten" ;
VAL_ 1306 TOG_Oelwarn_hoch 1 "Schwelle_ueberschritten" 0 "Schwelle_nicht_ueberschritten" ;
VAL_ 1306 TOG_Oeltempzeit 1023 "Bereichsueberl" 1 "Init" 0 "kein_Wert" ;
VAL_ 1306 TOG_Fuellstand_4 2047 "unguelt_Wert_oder_Bereichsueberl" 1 "Init" 0 "kein_Wert" ;
VAL_ 1306 TOG_Fuellstand_3 2047 "unguelt_Wert_oder_Bereichsueberl" 1 "Init" 0 "kein_Wert" ;
VAL_ 1306 TOG_OelmaxUeber 1 "Schwelle_ueberschritten" 0 "Schwelle_nicht_ueberschritten" ;
VAL_ 1306 TOG_Fuellstand_2 2047 "unguelt_Wert_oder_Bereichsueberl" 1 "Init" 0 "kein_Wert" ;
VAL_ 1306 TOG_Oelmax_hoch 1 "Schwelle_ueberschritten" 0 "Schwelle_nicht_ueberschritten" ;
VAL_ 1312 KO3_Sprache 12 "Japanisch" 11 "Niederlaendisch" 10 "US_Englisch" 9 "Chinesisch" 8 "Tschechisch" 6 "Portugiesisch" 5 "Spanisch" 4 "Italienisch" 3 "Franzoesisch" 2 "Englisch" 1 "Deutsch" 0 "keine_Sprachvar" ;
VAL_ 1312 KO3_Mp_Code 3 "Verbauliste" 2 "Radumfang" 1 "Plattform" 0 "Land_Sprache" ;
VAL_ 1312 KO3_Schluessel 15 "Schluessel15" 14 "Schluessel14" 13 "Schluessel13" 12 "Schluessel12" 11 "Schluessel11" 10 "Schluessel10" 9 "Schluessel9" 8 "Schluessel8" 7 "Schluessel7" 6 "Schluessel6" 5 "Schluessel5" 4 "Schluessel4" 3 "Schluessel3" 2 "Schluessel2" 1 "Schluessel1" 0 "keine_Info" ;
VAL_ 1312 KO3_Sta_Standz 1 "Kl_30_war_weg" 0 "Standzeit_iO" ;
VAL_ 1312 KO3_Kilometer 1048575 "Fehler" ;
VAL_ 1312 KO3_Um_AFS2 1 "Taster_gedrueckt" 0 "Taster_nicht_gedrueckt" ;
VAL_ 1312 KO3_Land 7 "Australien" 6 "Saudi_Arabien" 5 "Japan" 4 "Grossbritannien" 3 "Kanada" 2 "USA" 1 "Europa" 0 "Deutschland" ;
VAL_ 1312 KO3_Baureihe 7 "T_Klasse" 6 "D_Klasse" 5 "C_Klasse" 4 "B_Klasse" 3 "A_Klasse" 2 "A0_Klasse" 1 "A00_Klasse" 0 "LT_Klasse" ;
VAL_ 1312 KO3_Derivat 9 "Sonstige" 8 "MPV" 7 "City_Van_Pickup" 6 "Offroad" 5 "Cabrio_Roadster_Spider" 4 "Coupe_Sportwagen" 3 "Fliessheck" 2 "Variant" 1 "Stufenheck_Nutz" 0 "Kurzheck_Multivan" ;
VAL_ 1312 KO3_Marke 7 "Ford_Porsche" 6 "Bentley_RollsRoyce" 5 "Bugatti_Lamborghini" 4 "VW_Nutzf" 3 "Skoda" 2 "Seat" 1 "Audi" 0 "VW" ;
VAL_ 1312 KO3_Verbau_BN 1 "mit_CAN" 0 "ohne_CAN" ;
VAL_ 1312 KO3_Verbau_ADR 1 "mit_CAN" 0 "ohne_CAN" ;
VAL_ 1312 KO3_Verbau_Air 1 "mit_CAN" 0 "ohne_CAN" ;
VAL_ 1312 KO3_Verbau_DP 1 "mit_CAN" 0 "ohne_CAN" ;
VAL_ 1312 KO3_Verbau_Get 1 "mit_CAN" 0 "ohne_CAN" ;
VAL_ 1312 KO3_Verbau_Kl 1 "mit_CAN" 0 "ohne_CAN" ;
VAL_ 1312 KO3_Verbau_LH 1 "mit_CAN" 0 "ohne_CAN" ;
VAL_ 1312 KO3_Verbau_Br 1 "mit_CAN" 0 "ohne_CAN" ;
VAL_ 1312 KO3_Verbau_Niveau 1 "mit_CAN" 0 "ohne_CAN" ;
VAL_ 1312 KO3_Verbau_Mot 1 "mit_CAN" 0 "ohne_CAN" ;
VAL_ 1312 KO3_SWA_AnzFeh 1 "Fehler" 0 "iO" ;
VAL_ 1312 KO3_Verbau_LWS 1 "mit_CAN" 0 "ohne_CAN" ;
VAL_ 1312 KO3_Um_AutoHold 1 "Taster_gedrueckt" 0 "Taster_nicht_gedrueckt" ;
VAL_ 1312 KO3_Verbau_Syn 1 "mit_CAN" 0 "ohne_CAN" ;
VAL_ 1312 KO3_Um_Tourist 1 "Taster_gedrueckt" 0 "Taster_nicht_gedrueckt" ;
VAL_ 1056 KO2_Sta_Auss_T 1 "n_iO" 0 "iO" ;
VAL_ 1056 KO2_Temp_Einheit 1 "Fahrenheit" 0 "Celsius" ;
VAL_ 1056 KO2_gef_Auss_T 255 "Fehler" ;
VAL_ 1056 KO2_Bel_Schalt 127 "kein_Ersatzwert" ;
VAL_ 1056 KO2_Oelwarn 1 "ja" 0 "nein" ;
VAL_ 1056 KO2_Aussen_T 255 "Fehler" ;
VAL_ 1056 KO2_Sta_Schalt 1 "Kl_58s_n_iO" 0 "Kl_58s_iO" ;
VAL_ 1056 KO2_Sta_Displ 1 "Kl_58d_n_iO" 0 "Kl_58d_iO" ;
VAL_ 1056 KO2_Bel_Displ 127 "kein_Ersatzwert" ;
VAL_ 1056 KO2_Fehlereintr 1 "Fehlerspeichereintrag" 0 "kein_Fehlerspeichereintrag" ;
VAL_ 1056 KO2_Wischwasser 1 "Wischwasserwarnung_aktiv" 0 "keine_Warnung" ;
VAL_ 1056 KO2_PLA_Displaystatus 1 "dargestellt" 0 "nicht_dargestellt" ;
VAL_ 1056 KO2_GRA_High 1 "ja" 0 "nein" ;
VAL_ 1056 KO2_Kuehlm_T 255 "Fehler" ;
VAL_ 1056 KO2_Verb_TOG 1 "TOG_nicht_verbaut" 0 "TOG_verbaut" ;
VAL_ 1056 KO2_OelTemp 255 "Fehler" ;
VAL_ 1056 KO2_MFA_v_Einheit 1 "mph" 0 "kmh" ;
VAL_ 1056 KO2_OBD_Nib_Temp 15 "frei" 14 "frei" 13 "frei" 12 "frei" 11 "KS_MP_OC" 10 "KS_MP" 9 "KS_M_OC" 8 "KS_P_OC" 7 "RC_M" 6 "RC_P" 5 "OOR_M" 4 "OOR_P" 3 "OC" 2 "KS_P" 1 "KS_M" 0 "kein_Fehler" ;
VAL_ 1056 KO2_Passiv_Autolock 1 "aktiv" 0 "inaktiv" ;
VAL_ 1056 KO2_WFS_Schl_Ort 1 "Lesespule" 0 "keyless" ;
VAL_ 912 GK1_Sta_Licht1 1 "veraltet" 0 "aktuell_empfangen" ;
VAL_ 912 GK1_Sta_Licht3 1 "veraltet" 0 "aktuell_empfangen" ;
VAL_ 912 GK1_Sta_Anhaen 1 "veraltet" 0 "aktuell_empfangen" ;
VAL_ 912 GK1_Sta_Tuerkont 1 "veraltet" 0 "aktuell_empfangen" ;
VAL_ 912 GK1_Sta_RDK_Warn 1 "veraltet" 0 "aktuell_empfangen" ;
VAL_ 912 GK1_SleepAckn 1 "Sleep_Mode_Befehl" 0 "CAN_Kom_erforderlich" ;
VAL_ 912 GK1_Fa_Tuerkont 1 "offen" 0 "geschlossen" ;
VAL_ 912 GK1_BLS_ILM 1 "unplausibel" 0 "ok" ;
VAL_ 912 GK1_BrLi_links 1 "defekt" 0 "iO" ;
VAL_ 912 GK1_BrLi_rechts 1 "defekt" 0 "iO" ;
VAL_ 912 GK1_KW_Warm 1 "ja" 0 "nein" ;
VAL_ 912 GK1_BrLi_mitte 1 "defekt" 0 "iO" ;
VAL_ 912 GK1_EDC_ILM 1 "unplausibel" 0 "ok" ;
VAL_ 912 GK1_EDC_AAG 1 "unplausibel" 0 "ok" ;
VAL_ 912 GK1_BLS_AAG 1 "unplausibel" 0 "ok" ;
VAL_ 912 GK1_LS1_Fernlicht 1 "Fernlichtschalter_ein" 0 "Fernlichtschalter_aus" ;
VAL_ 912 GK1_Rueckfahr 1 "ein" 0 "aus" ;
VAL_ 912 GK1_Anhaenger 1 "Anhaenger_erkannt" 0 "kein_Anhaenger_erkannt" ;
VAL_ 912 GK1_Abblendlicht 1 "an" 0 "aus" ;
VAL_ 912 GK1_BrLi_Anhaen 1 "defekt" 0 "iO" ;
VAL_ 912 GK1_Blinker_re 1 "aktiviert" 0 "aus" ;
VAL_ 912 GK1_Blinker_li 1 "aktiviert" 0 "aus" ;
VAL_ 912 GK1_Anh_abgesteckt 1 "ja" 0 "nein" ;
VAL_ 912 GK1_Sta_Li_vorn 1 "veraltet" 0 "aktuell_empfangen" ;
VAL_ 912 GK1_Warnblk_Status 1 "aktiviert" 0 "aus_nicht_aktiviert" ;
VAL_ 912 GK1_Fernlicht 1 "an" 0 "aus" ;
VAL_ 912 GK1_RueckfahrSch 1 "ein" 0 "aus" ;
VAL_ 912 GK1_Abbl_VR_def 1 "an" 0 "aus" ;
VAL_ 912 GK1_Blink_Autob 1 "Autobahnblinken_aktiviert" 0 "Autobahnblinken_aus" ;
VAL_ 912 GK1_Wischer_vorn 1 "Wischer_laeuft" 0 "Wischer_aus" ;
VAL_ 912 GK1_Abbl_VL_def 1 "an" 0 "aus" ;
VAL_ 912 GK1_Sta_ILM_F_1 1 "veraltet" 0 "aktuell_empfangen" ;
VAL_ 912 GK1_ELV_verrieg 1 "ELV_verriegelt" 0 "ELV_nicht_verriegelt" ;
VAL_ 912 GK1_def_P_verr 1 "defekt" 0 "OK" ;
VAL_ 912 GK1_Sta_Kessy_2 1 "veraltet" 0 "aktuell_empfangen" ;
VAL_ 912 GK1_SH_Verbau 1 "Standheizung" 0 "keine_Standheizung" ;
VAL_ 912 GK1_Sta_LSM 1 "veraltet" 0 "aktuell_empfangen" ;
VAL_ 912 GK1_Sta_Licht2 1 "veraltet" 0 "aktuell_empfangen" ;
VAL_ 912 GK1_Sta_Stdhzg 1 "veraltet" 0 "aktuell_empfangen" ;
VAL_ 912 GK1_SH_laeuft 1 "SH_ist_oder_war_aktiv" 0 "SH_aus" ;
VAL_ 912 GK1_ParkFrontWi 1 "Parklage" 0 "keine_Parklage" ;
VAL_ 912 GK1_AnhKonLamp 1 "ein" 0 "aus" ;
VAL_ 912 GK1_SH_Zusatzfkt 1 "verfuegbar" 0 "nicht_verf" ;
VAL_ 912 GK1_Nebel_ein 1 "ein" 0 "aus" ;
VAL_ 912 GK1_Bremslicht 1 "ein" 0 "aus" ;
VAL_ 912 GK1_SH_Vorwaerm 1 "SH_mit_MVW" 0 "SH_ohne_MVW" ;
VAL_ 912 GK1_CharismaModus 3 "sport" 2 "normal" 1 "comfort" 0 "Init" ;
VAL_ 912 GK1_SamFktNr 1 "Charisma" 0 "ungueltig_Init" ;
VAL_ 906 GRA_Kodierinfo 1 "ACC" 0 "GRA" ;
VAL_ 906 GRA_Hauptschalt 1 "EIN_Nicht_Gerastet_AUS" 0 "Gerastet_AUS" ;
VAL_ 906 GRA_Sender 3 "Lenksaeulenmodul_4_Pos" 2 "nicht_belegt" 1 "Lenksaeulenmodul_6_Pos" 0 "BSG_oder_BCM" ;
VAL_ 906 GRA_Sta_Limiter 1 "Limiter_ein" 0 "Limiter_aus" ;
VAL_ 906 GRA_Sportschalter 1 "ein" 0 "aus" ;
VAL_ 906 GRA_Abbrechen 1 "Tipschalter_betaetigt" 0 "Tipschalter_nicht_betaetigt" ;
VAL_ 906 GRA_Down_kurz 1 "Tipschalter_betaetigt" 0 "Tipschalter_nicht_betaetigt" ;
VAL_ 906 GRA_Fehler_Tip 1 "Fehler_erkannt" 0 "iO" ;
VAL_ 906 GRA_Up_kurz 1 "Tipschalter_betaetigt" 0 "Tipschalter_nicht_betaetigt" ;
VAL_ 906 GRA_Up_lang 1 "Tipschalter_lang_betaetigt" 0 "Tipschalter_nicht_betaetigt" ;
VAL_ 906 GRA_Down_lang 1 "Tipschalter_lang_betaetigt" 0 "Tipschalter_nicht_betaetigt" ;
VAL_ 906 GRA_Neu_Setzen 1 "Tipschalter_betaetigt" 0 "Tipschalter_nicht_betaetigt" ;
VAL_ 906 GRA_Tip_Down 1 "Tip_down" 0 "Tipschalter_nicht_betaetigt" ;
VAL_ 906 GRA_Recall 1 "Tipschalter_betaetigt" 0 "Tipschalter_nicht_betaetigt" ;
VAL_ 906 GRA_Tip_Up 1 "Tip_up" 0 "Tipschalter_nicht_betaetigt" ;
VAL_ 906 GRA_Zeitluecke 3 "nicht_belegt" 2 "DIST_plus_1" 1 "DIST_minus_1" 0 "Taste_nicht_betaetigt" ;
VAL_ 906 GRA_Typ_Hauptschalt 1 "getastet" 0 "gerastet" ;
VAL_ 906 GRA_Fehler_Bed 1 "Fehler_Bedienhebel" 0 "in_Ordnung" ;
